VERSION ""

NS_ :

BS_:

BU_: Bosch_Radar2 Bosch_Radar1 RADAR_INPUT
VAL_TABLE_ ValueTable_Power_SNA 255 "SNA" ;
VAL_TABLE_ ValueTable_YAngle_SNA 65535 "SNA" ;
VAL_TABLE_ ValueTable_YSigmaAngle_SNA 1023 "SNA" ;
VAL_TABLE_ ValueTable_AngleType 1 "First 2 angles valid in C msg" 0 "First 4 angles valid in C msg" ;
VAL_TABLE_ RI_Veh_PRNDSTAT 0 "Park" 1 "Reverse" 2 "Neutral" 3 "Drive" ;

BO_ 1010 Location_Starter: 8 Bosch_Radar1
 SG_ Location_Veh_vEgo : 23|12@0+ (0.0625,-128) [-128|127.9375] "m/s" Vector__XXX
 SG_ Location_Veh_aEgo : 27|10@0+ (0.03125,-16) [-16|15.96875] "m/s²" Vector__XXX
 SG_ Location_Veh_slipAngle : 45|14@0+ (6.103515625E-005,-0.5) [-0.5|0.49993896484375] "Rad" Vector__XXX
 SG_ Location_Veh_psiDt : 7|16@0+ (6.103515625E-005,-2) [-2|1.99993896484375] "rad/s" Vector__XXX
 SG_ Location_MessStarterConsistBit : 56|1@0+ (1,0) [0|1] "" Vector__XXX

BO_ 1203 Location_Ender: 8 Bosch_Radar1
 SG_ Location_PacketChecksum : 63|8@0+ (1,0) [0|0] "" Vector__XXX
 SG_ Location_timestamp : 7|8@0+ (0.0009765625,0) [0|0.2490234375] "s" Vector__XXX
 SG_ Location_MessEnderConsistBit : 48|1@0+ (1,0) [0|1] "" Vector__XXX
 SG_ Location_TCCounter : 31|8@0+ (1,0) [0|0] "" Vector__XXX

BO_ 1958 Radar2_Diag_Response: 8 Bosch_Radar2
 SG_ R2_DiagResponse : 7|64@0+ (1,0) [0|0] "" Vector__XXX

BO_ 1957 Radar2_Diag_Request: 8 RADAR_INPUT
 SG_ R2_DiagRequest : 7|64@0+ (1,0) [0|0] ""  Bosch_Radar2

BO_ 1985 Radar1_Diag_Response: 8 Bosch_Radar1
 SG_ R1_DiagResponse : 7|64@0+ (1,0) [0|0] "" Vector__XXX

BO_ 1879 Radar1_Diag_Request: 8 RADAR_INPUT
 SG_ R1_DiagRequest : 7|64@0+ (1,0) [0|0] ""  Bosch_Radar1

BO_ 1011 location00_A: 8 Bosch_Radar1
 SG_ Loc00_Status : 62|1@0+ (1,0) [0|1] "" Vector__XXX
 SG_ Loc00_AngleType : 63|1@0+ (1,0) [0|1] "" Vector__XXX
 SG_ Loc00_YExistProb4 : 55|8@0+ (0.00390625,0) [0|1] "" Vector__XXX
 SG_ Loc00_YExistProb3 : 47|8@0+ (0.00390625,0) [0|1] "" Vector__XXX
 SG_ Loc00_YExistProb2 : 39|8@0+ (0.00390625,0) [0|1] "" Vector__XXX
 SG_ Loc00_YExistProb1 : 31|8@0+ (0.00390625,0) [0|1] "" Vector__XXX
 SG_ Loc00_YExistProb0 : 23|8@0+ (0.00390625,0) [0|1] "" Vector__XXX
 SG_ Loc00_RadialDist : 7|16@0+ (0.0039063,0) [0|255.9993705] "m" Vector__XXX

BO_ 1012 location00_B: 8 Bosch_Radar1
 SG_ Loc00_ZCorrelated : 53|10@0+ (0.00390625,-2) [-2|1.99609375] "rad" Vector__XXX
 SG_ Loc00_YSigmaAngle4 : 25|10@0+ (0.00012207,0) [0|0.12487761] "rad" Vector__XXX
 SG_ Loc00_YSigmaAngle3 : 47|10@0+ (0.00012207,0) [0|0.12487761] "rad" Vector__XXX
 SG_ Loc00_YSigmaAngle2 : 19|10@0+ (0.00012207,0) [0|0.12487761] "rad" Vector__XXX
 SG_ Loc00_YSigmaAngle1 : 13|10@0+ (0.00012207,0) [0|0.12487761] "rad" Vector__XXX
 SG_ Loc00_YSigmaAngle0 : 7|10@0+ (0.00012207,0) [0|0.12487761] "rad" Vector__XXX

BO_ 1013 location00_C: 8 Bosch_Radar1
 SG_ Loc00_YAngle3 : 55|16@0+ (6.103608E-005,-2) [-2|1.9999995028] "rad" Vector__XXX
 SG_ Loc00_YAngle2 : 39|16@0+ (6.103608E-005,-2) [-2|1.9999995028] "rad" Vector__XXX
 SG_ Loc00_YAngle1 : 23|16@0+ (6.103608E-005,-2) [-2|1.9999995028] "rad" Vector__XXX
 SG_ Loc00_YAngle0 : 7|16@0+ (6.103608E-005,-2) [-2|1.9999995028] "rad" Vector__XXX

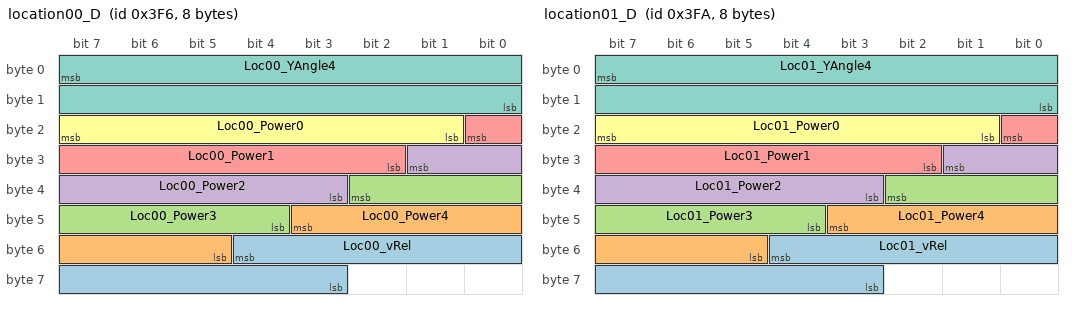
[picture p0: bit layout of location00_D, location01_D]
BO_ 1014 location00_D: 8 Bosch_Radar1
 SG_ Loc00_vRel : 52|10@0+ (0.125,-64) [-64|63.875] "m/s" Vector__XXX
 SG_ Loc00_Power4 : 43|7@0+ (1,-64) [-64|63] "dBm^2" Vector__XXX
 SG_ Loc00_Power3 : 34|7@0+ (1,-64) [-64|63] "dBm^2" Vector__XXX
 SG_ Loc00_Power2 : 25|7@0+ (1,-64) [-64|63] "dBm^2" Vector__XXX
 SG_ Loc00_Power1 : 16|7@0+ (1,-64) [-64|63] "dBm^2" Vector__XXX
 SG_ Loc00_Power0 : 23|7@0+ (1,-64) [-64|63] "dBm^2" Vector__XXX
 SG_ Loc00_YAngle4 : 7|16@0+ (6.103608E-005,-2) [-2|1.9999995028] "rad" Vector__XXX

BO_ 1015 location01_A: 8 Bosch_Radar1
 SG_ Loc01_Status : 62|1@0+ (1,0) [0|1] "" Vector__XXX
 SG_ Loc01_AngleType : 63|1@0+ (1,0) [0|1] "" Vector__XXX
 SG_ Loc01_YExistProb4 : 55|8@0+ (0.00390625,0) [0|1] "" Vector__XXX
 SG_ Loc01_YExistProb3 : 47|8@0+ (0.00390625,0) [0|1] "" Vector__XXX
 SG_ Loc01_YExistProb2 : 39|8@0+ (0.00390625,0) [0|1] "" Vector__XXX
 SG_ Loc01_YExistProb1 : 31|8@0+ (0.00390625,0) [0|1] "" Vector__XXX
 SG_ Loc01_YExistProb0 : 23|8@0+ (0.00390625,0) [0|1] "" Vector__XXX
 SG_ Loc01_RadialDist : 7|16@0+ (0.0039063,0) [0|255.9993705] "m" Vector__XXX

BO_ 1016 location01_B: 8 Bosch_Radar1
 SG_ Loc01_ZCorrelated : 53|10@0+ (0.00390625,-2) [-2|1.99609375] "rad" Vector__XXX
 SG_ Loc01_YSigmaAngle4 : 25|10@0+ (0.00012207,0) [0|0.12487761] "rad" Vector__XXX
 SG_ Loc01_YSigmaAngle3 : 47|10@0+ (0.00012207,0) [0|0.12487761] "rad" Vector__XXX
 SG_ Loc01_YSigmaAngle2 : 19|10@0+ (0.00012207,0) [0|0.12487761] "rad" Vector__XXX
 SG_ Loc01_YSigmaAngle1 : 13|10@0+ (0.00012207,0) [0|0.12487761] "rad" Vector__XXX
 SG_ Loc01_YSigmaAngle0 : 7|10@0+ (0.00012207,0) [0|0.12487761] "rad" Vector__XXX

BO_ 1017 location01_C: 8 Bosch_Radar1
 SG_ Loc01_YAngle3 : 55|16@0+ (6.103608E-005,-2) [-2|1.9999995028] "rad" Vector__XXX
 SG_ Loc01_YAngle2 : 39|16@0+ (6.103608E-005,-2) [-2|1.9999995028] "rad" Vector__XXX
 SG_ Loc01_YAngle1 : 23|16@0+ (6.103608E-005,-2) [-2|1.9999995028] "rad" Vector__XXX
 SG_ Loc01_YAngle0 : 7|16@0+ (6.103608E-005,-2) [-2|1.9999995028] "rad" Vector__XXX

BO_ 1018 location01_D: 8 Bosch_Radar1
 SG_ Loc01_vRel : 52|10@0+ (0.125,-64) [-64|63.875] "m/s" Vector__XXX
 SG_ Loc01_Power4 : 43|7@0+ (1,-64) [-64|63] "dBm^2" Vector__XXX
 SG_ Loc01_Power3 : 34|7@0+ (1,-64) [-64|63] "dBm^2" Vector__XXX
 SG_ Loc01_Power2 : 25|7@0+ (1,-64) [-64|63] "dBm^2" Vector__XXX
 SG_ Loc01_Power1 : 16|7@0+ (1,-64) [-64|63] "dBm^2" Vector__XXX
 SG_ Loc01_Power0 : 23|7@0+ (1,-64) [-64|63] "dBm^2" Vector__XXX
 SG_ Loc01_YAngle4 : 7|16@0+ (6.103608E-005,-2) [-2|1.9999995028] "rad" Vector__XXX

BO_ 1019 location02_A: 8 Bosch_Radar1
 SG_ Loc02_Status : 62|1@0+ (1,0) [0|1] "" Vector__XXX
 SG_ Loc02_AngleType : 63|1@0+ (1,0) [0|1] "" Vector__XXX
 SG_ Loc02_YExistProb4 : 55|8@0+ (0.00390625,0) [0|1] "" Vector__XXX
 SG_ Loc02_YExistProb3 : 47|8@0+ (0.00390625,0) [0|1] "" Vector__XXX
 SG_ Loc02_YExistProb2 : 39|8@0+ (0.00390625,0) [0|1] "" Vector__XXX
 SG_ Loc02_YExistProb1 : 31|8@0+ (0.00390625,0) [0|1] "" Vector__XXX
 SG_ Loc02_YExistProb0 : 23|8@0+ (0.00390625,0) [0|1] "" Vector__XXX
 SG_ Loc02_RadialDist : 7|16@0+ (0.0039063,0) [0|255.9993705] "m" Vector__XXX

BO_ 1020 location02_B: 8 Bosch_Radar1
 SG_ Loc02_ZCorrelated : 53|10@0+ (0.00390625,-2) [-2|1.99609375] "rad" Vector__XXX
 SG_ Loc02_YSigmaAngle4 : 25|10@0+ (0.00012207,0) [0|0.12487761] "rad" Vector__XXX
 SG_ Loc02_YSigmaAngle3 : 47|10@0+ (0.00012207,0) [0|0.12487761] "rad" Vector__XXX
 SG_ Loc02_YSigmaAngle2 : 19|10@0+ (0.00012207,0) [0|0.12487761] "rad" Vector__XXX
 SG_ Loc02_YSigmaAngle1 : 13|10@0+ (0.00012207,0) [0|0.12487761] "rad" Vector__XXX
 SG_ Loc02_YSigmaAngle0 : 7|10@0+ (0.00012207,0) [0|0.12487761] "rad" Vector__XXX

BO_ 1021 location02_C: 8 Bosch_Radar1
 SG_ Loc02_YAngle3 : 55|16@0+ (6.103608E-005,-2) [-2|1.9999995028] "rad" Vector__XXX
 SG_ Loc02_YAngle2 : 39|16@0+ (6.103608E-005,-2) [-2|1.9999995028] "rad" Vector__XXX
 SG_ Loc02_YAngle1 : 23|16@0+ (6.103608E-005,-2) [-2|1.9999995028] "rad" Vector__XXX
 SG_ Loc02_YAngle0 : 7|16@0+ (6.103608E-005,-2) [-2|1.9999995028] "rad" Vector__XXX

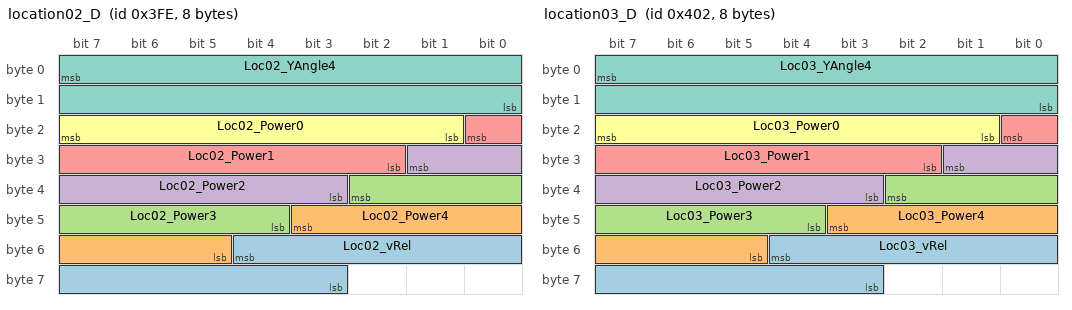
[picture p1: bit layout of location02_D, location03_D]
BO_ 1022 location02_D: 8 Bosch_Radar1
 SG_ Loc02_vRel : 52|10@0+ (0.125,-64) [-64|63.875] "m/s" Vector__XXX
 SG_ Loc02_Power4 : 43|7@0+ (1,-64) [-64|63] "dBm^2" Vector__XXX
 SG_ Loc02_Power3 : 34|7@0+ (1,-64) [-64|63] "dBm^2" Vector__XXX
 SG_ Loc02_Power2 : 25|7@0+ (1,-64) [-64|63] "dBm^2" Vector__XXX
 SG_ Loc02_Power1 : 16|7@0+ (1,-64) [-64|63] "dBm^2" Vector__XXX
 SG_ Loc02_Power0 : 23|7@0+ (1,-64) [-64|63] "dBm^2" Vector__XXX
 SG_ Loc02_YAngle4 : 7|16@0+ (6.103608E-005,-2) [-2|1.9999995028] "rad" Vector__XXX

BO_ 1023 location03_A: 8 Bosch_Radar1
 SG_ Loc03_Status : 62|1@0+ (1,0) [0|1] "" Vector__XXX
 SG_ Loc03_AngleType : 63|1@0+ (1,0) [0|1] "" Vector__XXX
 SG_ Loc03_YExistProb4 : 55|8@0+ (0.00390625,0) [0|1] "" Vector__XXX
 SG_ Loc03_YExistProb3 : 47|8@0+ (0.00390625,0) [0|1] "" Vector__XXX
 SG_ Loc03_YExistProb2 : 39|8@0+ (0.00390625,0) [0|1] "" Vector__XXX
 SG_ Loc03_YExistProb1 : 31|8@0+ (0.00390625,0) [0|1] "" Vector__XXX
 SG_ Loc03_YExistProb0 : 23|8@0+ (0.00390625,0) [0|1] "" Vector__XXX
 SG_ Loc03_RadialDist : 7|16@0+ (0.0039063,0) [0|255.9993705] "m" Vector__XXX

BO_ 1024 location03_B: 8 Bosch_Radar1
 SG_ Loc03_ZCorrelated : 53|10@0+ (0.00390625,-2) [-2|1.99609375] "rad" Vector__XXX
 SG_ Loc03_YSigmaAngle4 : 25|10@0+ (0.00012207,0) [0|0.12487761] "rad" Vector__XXX
 SG_ Loc03_YSigmaAngle3 : 47|10@0+ (0.00012207,0) [0|0.12487761] "rad" Vector__XXX
 SG_ Loc03_YSigmaAngle2 : 19|10@0+ (0.00012207,0) [0|0.12487761] "rad" Vector__XXX
 SG_ Loc03_YSigmaAngle1 : 13|10@0+ (0.00012207,0) [0|0.12487761] "rad" Vector__XXX
 SG_ Loc03_YSigmaAngle0 : 7|10@0+ (0.00012207,0) [0|0.12487761] "rad" Vector__XXX

BO_ 1025 location03_C: 8 Bosch_Radar1
 SG_ Loc03_YAngle3 : 55|16@0+ (6.103608E-005,-2) [-2|1.9999995028] "rad" Vector__XXX
 SG_ Loc03_YAngle2 : 39|16@0+ (6.103608E-005,-2) [-2|1.9999995028] "rad" Vector__XXX
 SG_ Loc03_YAngle1 : 23|16@0+ (6.103608E-005,-2) [-2|1.9999995028] "rad" Vector__XXX
 SG_ Loc03_YAngle0 : 7|16@0+ (6.103608E-005,-2) [-2|1.9999995028] "rad" Vector__XXX

BO_ 1026 location03_D: 8 Bosch_Radar1
 SG_ Loc03_vRel : 52|10@0+ (0.125,-64) [-64|63.875] "m/s" Vector__XXX
 SG_ Loc03_Power4 : 43|7@0+ (1,-64) [-64|63] "dBm^2" Vector__XXX
 SG_ Loc03_Power3 : 34|7@0+ (1,-64) [-64|63] "dBm^2" Vector__XXX
 SG_ Loc03_Power2 : 25|7@0+ (1,-64) [-64|63] "dBm^2" Vector__XXX
 SG_ Loc03_Power1 : 16|7@0+ (1,-64) [-64|63] "dBm^2" Vector__XXX
 SG_ Loc03_Power0 : 23|7@0+ (1,-64) [-64|63] "dBm^2" Vector__XXX
 SG_ Loc03_YAngle4 : 7|16@0+ (6.103608E-005,-2) [-2|1.9999995028] "rad" Vector__XXX

BO_ 1027 location04_A: 8 Bosch_Radar1
 SG_ Loc04_Status : 62|1@0+ (1,0) [0|1] "" Vector__XXX
 SG_ Loc04_AngleType : 63|1@0+ (1,0) [0|1] "" Vector__XXX
 SG_ Loc04_YExistProb4 : 55|8@0+ (0.00390625,0) [0|1] "" Vector__XXX
 SG_ Loc04_YExistProb3 : 47|8@0+ (0.00390625,0) [0|1] "" Vector__XXX
 SG_ Loc04_YExistProb2 : 39|8@0+ (0.00390625,0) [0|1] "" Vector__XXX
 SG_ Loc04_YExistProb1 : 31|8@0+ (0.00390625,0) [0|1] "" Vector__XXX
 SG_ Loc04_YExistProb0 : 23|8@0+ (0.00390625,0) [0|1] "" Vector__XXX
 SG_ Loc04_RadialDist : 7|16@0+ (0.0039063,0) [0|255.9993705] "m" Vector__XXX

BO_ 1028 location04_B: 8 Bosch_Radar1
 SG_ Loc04_ZCorrelated : 53|10@0+ (0.00390625,-2) [-2|1.99609375] "rad" Vector__XXX
 SG_ Loc04_YSigmaAngle4 : 25|10@0+ (0.00012207,0) [0|0.12487761] "rad" Vector__XXX
 SG_ Loc04_YSigmaAngle3 : 47|10@0+ (0.00012207,0) [0|0.12487761] "rad" Vector__XXX
 SG_ Loc04_YSigmaAngle2 : 19|10@0+ (0.00012207,0) [0|0.12487761] "rad" Vector__XXX
 SG_ Loc04_YSigmaAngle1 : 13|10@0+ (0.00012207,0) [0|0.12487761] "rad" Vector__XXX
 SG_ Loc04_YSigmaAngle0 : 7|10@0+ (0.00012207,0) [0|0.12487761] "rad" Vector__XXX

BO_ 1029 location04_C: 8 Bosch_Radar1
 SG_ Loc04_YAngle3 : 55|16@0+ (6.103608E-005,-2) [-2|1.9999995028] "rad" Vector__XXX
 SG_ Loc04_YAngle2 : 39|16@0+ (6.103608E-005,-2) [-2|1.9999995028] "rad" Vector__XXX
 SG_ Loc04_YAngle1 : 23|16@0+ (6.103608E-005,-2) [-2|1.9999995028] "rad" Vector__XXX
 SG_ Loc04_YAngle0 : 7|16@0+ (6.103608E-005,-2) [-2|1.9999995028] "rad" Vector__XXX

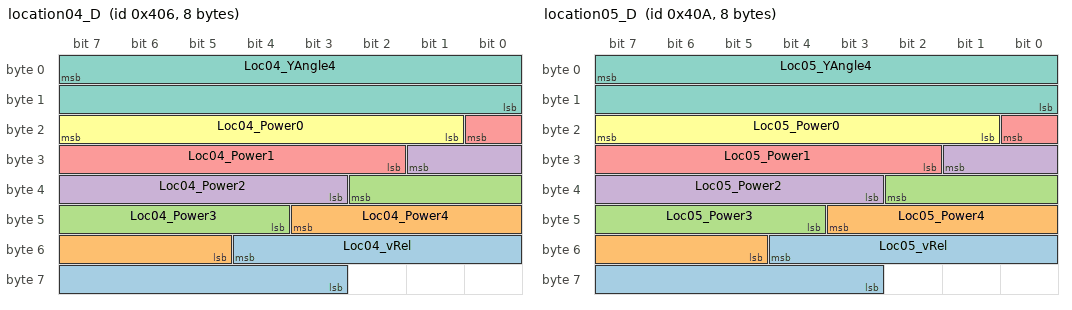
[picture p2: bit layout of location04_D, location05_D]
BO_ 1030 location04_D: 8 Bosch_Radar1
 SG_ Loc04_vRel : 52|10@0+ (0.125,-64) [-64|63.875] "m/s" Vector__XXX
 SG_ Loc04_Power4 : 43|7@0+ (1,-64) [-64|63] "dBm^2" Vector__XXX
 SG_ Loc04_Power3 : 34|7@0+ (1,-64) [-64|63] "dBm^2" Vector__XXX
 SG_ Loc04_Power2 : 25|7@0+ (1,-64) [-64|63] "dBm^2" Vector__XXX
 SG_ Loc04_Power1 : 16|7@0+ (1,-64) [-64|63] "dBm^2" Vector__XXX
 SG_ Loc04_Power0 : 23|7@0+ (1,-64) [-64|63] "dBm^2" Vector__XXX
 SG_ Loc04_YAngle4 : 7|16@0+ (6.103608E-005,-2) [-2|1.9999995028] "rad" Vector__XXX

BO_ 1031 location05_A: 8 Bosch_Radar1
 SG_ Loc05_Status : 62|1@0+ (1,0) [0|1] "" Vector__XXX
 SG_ Loc05_AngleType : 63|1@0+ (1,0) [0|1] "" Vector__XXX
 SG_ Loc05_YExistProb4 : 55|8@0+ (0.00390625,0) [0|1] "" Vector__XXX
 SG_ Loc05_YExistProb3 : 47|8@0+ (0.00390625,0) [0|1] "" Vector__XXX
 SG_ Loc05_YExistProb2 : 39|8@0+ (0.00390625,0) [0|1] "" Vector__XXX
 SG_ Loc05_YExistProb1 : 31|8@0+ (0.00390625,0) [0|1] "" Vector__XXX
 SG_ Loc05_YExistProb0 : 23|8@0+ (0.00390625,0) [0|1] "" Vector__XXX
 SG_ Loc05_RadialDist : 7|16@0+ (0.0039063,0) [0|255.9993705] "m" Vector__XXX

BO_ 1032 location05_B: 8 Bosch_Radar1
 SG_ Loc05_ZCorrelated : 53|10@0+ (0.00390625,-2) [-2|1.99609375] "rad" Vector__XXX
 SG_ Loc05_YSigmaAngle4 : 25|10@0+ (0.00012207,0) [0|0.12487761] "rad" Vector__XXX
 SG_ Loc05_YSigmaAngle3 : 47|10@0+ (0.00012207,0) [0|0.12487761] "rad" Vector__XXX
 SG_ Loc05_YSigmaAngle2 : 19|10@0+ (0.00012207,0) [0|0.12487761] "rad" Vector__XXX
 SG_ Loc05_YSigmaAngle1 : 13|10@0+ (0.00012207,0) [0|0.12487761] "rad" Vector__XXX
 SG_ Loc05_YSigmaAngle0 : 7|10@0+ (0.00012207,0) [0|0.12487761] "rad" Vector__XXX

BO_ 1033 location05_C: 8 Bosch_Radar1
 SG_ Loc05_YAngle3 : 55|16@0+ (6.103608E-005,-2) [-2|1.9999995028] "rad" Vector__XXX
 SG_ Loc05_YAngle2 : 39|16@0+ (6.103608E-005,-2) [-2|1.9999995028] "rad" Vector__XXX
 SG_ Loc05_YAngle1 : 23|16@0+ (6.103608E-005,-2) [-2|1.9999995028] "rad" Vector__XXX
 SG_ Loc05_YAngle0 : 7|16@0+ (6.103608E-005,-2) [-2|1.9999995028] "rad" Vector__XXX

BO_ 1034 location05_D: 8 Bosch_Radar1
 SG_ Loc05_vRel : 52|10@0+ (0.125,-64) [-64|63.875] "m/s" Vector__XXX
 SG_ Loc05_Power4 : 43|7@0+ (1,-64) [-64|63] "dBm^2" Vector__XXX
 SG_ Loc05_Power3 : 34|7@0+ (1,-64) [-64|63] "dBm^2" Vector__XXX
 SG_ Loc05_Power2 : 25|7@0+ (1,-64) [-64|63] "dBm^2" Vector__XXX
 SG_ Loc05_Power1 : 16|7@0+ (1,-64) [-64|63] "dBm^2" Vector__XXX
 SG_ Loc05_Power0 : 23|7@0+ (1,-64) [-64|63] "dBm^2" Vector__XXX
 SG_ Loc05_YAngle4 : 7|16@0+ (6.103608E-005,-2) [-2|1.9999995028] "rad" Vector__XXX

BO_ 1035 location06_A: 8 Bosch_Radar1
 SG_ Loc06_Status : 62|1@0+ (1,0) [0|1] "" Vector__XXX
 SG_ Loc06_AngleType : 63|1@0+ (1,0) [0|1] "" Vector__XXX
 SG_ Loc06_YExistProb4 : 55|8@0+ (0.00390625,0) [0|1] "" Vector__XXX
 SG_ Loc06_YExistProb3 : 47|8@0+ (0.00390625,0) [0|1] "" Vector__XXX
 SG_ Loc06_YExistProb2 : 39|8@0+ (0.00390625,0) [0|1] "" Vector__XXX
 SG_ Loc06_YExistProb1 : 31|8@0+ (0.00390625,0) [0|1] "" Vector__XXX
 SG_ Loc06_YExistProb0 : 23|8@0+ (0.00390625,0) [0|1] "" Vector__XXX
 SG_ Loc06_RadialDist : 7|16@0+ (0.0039063,0) [0|255.9993705] "m" Vector__XXX

BO_ 1036 location06_B: 8 Bosch_Radar1
 SG_ Loc06_ZCorrelated : 53|10@0+ (0.00390625,-2) [-2|1.99609375] "rad" Vector__XXX
 SG_ Loc06_YSigmaAngle4 : 25|10@0+ (0.00012207,0) [0|0.12487761] "rad" Vector__XXX
 SG_ Loc06_YSigmaAngle3 : 47|10@0+ (0.00012207,0) [0|0.12487761] "rad" Vector__XXX
 SG_ Loc06_YSigmaAngle2 : 19|10@0+ (0.00012207,0) [0|0.12487761] "rad" Vector__XXX
 SG_ Loc06_YSigmaAngle1 : 13|10@0+ (0.00012207,0) [0|0.12487761] "rad" Vector__XXX
 SG_ Loc06_YSigmaAngle0 : 7|10@0+ (0.00012207,0) [0|0.12487761] "rad" Vector__XXX

BO_ 1037 location06_C: 8 Bosch_Radar1
 SG_ Loc06_YAngle3 : 55|16@0+ (6.103608E-005,-2) [-2|1.9999995028] "rad" Vector__XXX
 SG_ Loc06_YAngle2 : 39|16@0+ (6.103608E-005,-2) [-2|1.9999995028] "rad" Vector__XXX
 SG_ Loc06_YAngle1 : 23|16@0+ (6.103608E-005,-2) [-2|1.9999995028] "rad" Vector__XXX
 SG_ Loc06_YAngle0 : 7|16@0+ (6.103608E-005,-2) [-2|1.9999995028] "rad" Vector__XXX

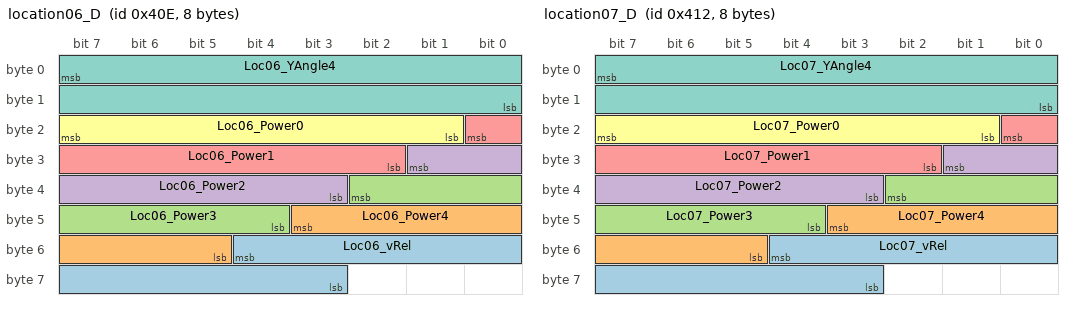
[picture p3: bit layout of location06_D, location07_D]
BO_ 1038 location06_D: 8 Bosch_Radar1
 SG_ Loc06_vRel : 52|10@0+ (0.125,-64) [-64|63.875] "m/s" Vector__XXX
 SG_ Loc06_Power4 : 43|7@0+ (1,-64) [-64|63] "dBm^2" Vector__XXX
 SG_ Loc06_Power3 : 34|7@0+ (1,-64) [-64|63] "dBm^2" Vector__XXX
 SG_ Loc06_Power2 : 25|7@0+ (1,-64) [-64|63] "dBm^2" Vector__XXX
 SG_ Loc06_Power1 : 16|7@0+ (1,-64) [-64|63] "dBm^2" Vector__XXX
 SG_ Loc06_Power0 : 23|7@0+ (1,-64) [-64|63] "dBm^2" Vector__XXX
 SG_ Loc06_YAngle4 : 7|16@0+ (6.103608E-005,-2) [-2|1.9999995028] "rad" Vector__XXX

BO_ 1039 location07_A: 8 Bosch_Radar1
 SG_ Loc07_Status : 62|1@0+ (1,0) [0|1] "" Vector__XXX
 SG_ Loc07_AngleType : 63|1@0+ (1,0) [0|1] "" Vector__XXX
 SG_ Loc07_YExistProb4 : 55|8@0+ (0.00390625,0) [0|1] "" Vector__XXX
 SG_ Loc07_YExistProb3 : 47|8@0+ (0.00390625,0) [0|1] "" Vector__XXX
 SG_ Loc07_YExistProb2 : 39|8@0+ (0.00390625,0) [0|1] "" Vector__XXX
 SG_ Loc07_YExistProb1 : 31|8@0+ (0.00390625,0) [0|1] "" Vector__XXX
 SG_ Loc07_YExistProb0 : 23|8@0+ (0.00390625,0) [0|1] "" Vector__XXX
 SG_ Loc07_RadialDist : 7|16@0+ (0.0039063,0) [0|255.9993705] "m" Vector__XXX

BO_ 1040 location07_B: 8 Bosch_Radar1
 SG_ Loc07_ZCorrelated : 53|10@0+ (0.00390625,-2) [-2|1.99609375] "rad" Vector__XXX
 SG_ Loc07_YSigmaAngle4 : 25|10@0+ (0.00012207,0) [0|0.12487761] "rad" Vector__XXX
 SG_ Loc07_YSigmaAngle3 : 47|10@0+ (0.00012207,0) [0|0.12487761] "rad" Vector__XXX
 SG_ Loc07_YSigmaAngle2 : 19|10@0+ (0.00012207,0) [0|0.12487761] "rad" Vector__XXX
 SG_ Loc07_YSigmaAngle1 : 13|10@0+ (0.00012207,0) [0|0.12487761] "rad" Vector__XXX
 SG_ Loc07_YSigmaAngle0 : 7|10@0+ (0.00012207,0) [0|0.12487761] "rad" Vector__XXX

BO_ 1041 location07_C: 8 Bosch_Radar1
 SG_ Loc07_YAngle3 : 55|16@0+ (6.103608E-005,-2) [-2|1.9999995028] "rad" Vector__XXX
 SG_ Loc07_YAngle2 : 39|16@0+ (6.103608E-005,-2) [-2|1.9999995028] "rad" Vector__XXX
 SG_ Loc07_YAngle1 : 23|16@0+ (6.103608E-005,-2) [-2|1.9999995028] "rad" Vector__XXX
 SG_ Loc07_YAngle0 : 7|16@0+ (6.103608E-005,-2) [-2|1.9999995028] "rad" Vector__XXX

BO_ 1042 location07_D: 8 Bosch_Radar1
 SG_ Loc07_vRel : 52|10@0+ (0.125,-64) [-64|63.875] "m/s" Vector__XXX
 SG_ Loc07_Power4 : 43|7@0+ (1,-64) [-64|63] "dBm^2" Vector__XXX
 SG_ Loc07_Power3 : 34|7@0+ (1,-64) [-64|63] "dBm^2" Vector__XXX
 SG_ Loc07_Power2 : 25|7@0+ (1,-64) [-64|63] "dBm^2" Vector__XXX
 SG_ Loc07_Power1 : 16|7@0+ (1,-64) [-64|63] "dBm^2" Vector__XXX
 SG_ Loc07_Power0 : 23|7@0+ (1,-64) [-64|63] "dBm^2" Vector__XXX
 SG_ Loc07_YAngle4 : 7|16@0+ (6.103608E-005,-2) [-2|1.9999995028] "rad" Vector__XXX

BO_ 1043 location08_A: 8 Bosch_Radar1
 SG_ Loc08_Status : 62|1@0+ (1,0) [0|1] "" Vector__XXX
 SG_ Loc08_AngleType : 63|1@0+ (1,0) [0|1] "" Vector__XXX
 SG_ Loc08_YExistProb4 : 55|8@0+ (0.00390625,0) [0|1] "" Vector__XXX
 SG_ Loc08_YExistProb3 : 47|8@0+ (0.00390625,0) [0|1] "" Vector__XXX
 SG_ Loc08_YExistProb2 : 39|8@0+ (0.00390625,0) [0|1] "" Vector__XXX
 SG_ Loc08_YExistProb1 : 31|8@0+ (0.00390625,0) [0|1] "" Vector__XXX
 SG_ Loc08_YExistProb0 : 23|8@0+ (0.00390625,0) [0|1] "" Vector__XXX
 SG_ Loc08_RadialDist : 7|16@0+ (0.0039063,0) [0|255.9993705] "m" Vector__XXX

BO_ 1044 location08_B: 8 Bosch_Radar1
 SG_ Loc08_ZCorrelated : 53|10@0+ (0.00390625,-2) [-2|1.99609375] "rad" Vector__XXX
 SG_ Loc08_YSigmaAngle4 : 25|10@0+ (0.00012207,0) [0|0.12487761] "rad" Vector__XXX
 SG_ Loc08_YSigmaAngle3 : 47|10@0+ (0.00012207,0) [0|0.12487761] "rad" Vector__XXX
 SG_ Loc08_YSigmaAngle2 : 19|10@0+ (0.00012207,0) [0|0.12487761] "rad" Vector__XXX
 SG_ Loc08_YSigmaAngle1 : 13|10@0+ (0.00012207,0) [0|0.12487761] "rad" Vector__XXX
 SG_ Loc08_YSigmaAngle0 : 7|10@0+ (0.00012207,0) [0|0.12487761] "rad" Vector__XXX

BO_ 1045 location08_C: 8 Bosch_Radar1
 SG_ Loc08_YAngle3 : 55|16@0+ (6.103608E-005,-2) [-2|1.9999995028] "rad" Vector__XXX
 SG_ Loc08_YAngle2 : 39|16@0+ (6.103608E-005,-2) [-2|1.9999995028] "rad" Vector__XXX
 SG_ Loc08_YAngle1 : 23|16@0+ (6.103608E-005,-2) [-2|1.9999995028] "rad" Vector__XXX
 SG_ Loc08_YAngle0 : 7|16@0+ (6.103608E-005,-2) [-2|1.9999995028] "rad" Vector__XXX

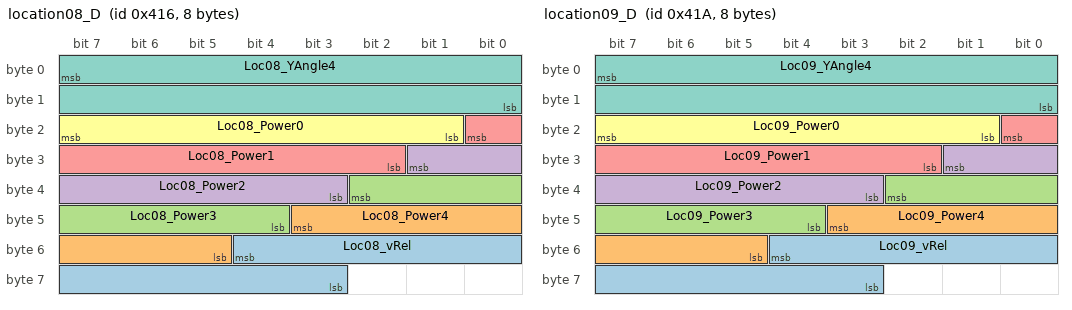
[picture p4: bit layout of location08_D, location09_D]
BO_ 1046 location08_D: 8 Bosch_Radar1
 SG_ Loc08_vRel : 52|10@0+ (0.125,-64) [-64|63.875] "m/s" Vector__XXX
 SG_ Loc08_Power4 : 43|7@0+ (1,-64) [-64|63] "dBm^2" Vector__XXX
 SG_ Loc08_Power3 : 34|7@0+ (1,-64) [-64|63] "dBm^2" Vector__XXX
 SG_ Loc08_Power2 : 25|7@0+ (1,-64) [-64|63] "dBm^2" Vector__XXX
 SG_ Loc08_Power1 : 16|7@0+ (1,-64) [-64|63] "dBm^2" Vector__XXX
 SG_ Loc08_Power0 : 23|7@0+ (1,-64) [-64|63] "dBm^2" Vector__XXX
 SG_ Loc08_YAngle4 : 7|16@0+ (6.103608E-005,-2) [-2|1.9999995028] "rad" Vector__XXX

BO_ 1047 location09_A: 8 Bosch_Radar1
 SG_ Loc09_Status : 62|1@0+ (1,0) [0|1] "" Vector__XXX
 SG_ Loc09_AngleType : 63|1@0+ (1,0) [0|1] "" Vector__XXX
 SG_ Loc09_YExistProb4 : 55|8@0+ (0.00390625,0) [0|1] "" Vector__XXX
 SG_ Loc09_YExistProb3 : 47|8@0+ (0.00390625,0) [0|1] "" Vector__XXX
 SG_ Loc09_YExistProb2 : 39|8@0+ (0.00390625,0) [0|1] "" Vector__XXX
 SG_ Loc09_YExistProb1 : 31|8@0+ (0.00390625,0) [0|1] "" Vector__XXX
 SG_ Loc09_YExistProb0 : 23|8@0+ (0.00390625,0) [0|1] "" Vector__XXX
 SG_ Loc09_RadialDist : 7|16@0+ (0.0039063,0) [0|255.9993705] "m" Vector__XXX

BO_ 1048 location09_B: 8 Bosch_Radar1
 SG_ Loc09_ZCorrelated : 53|10@0+ (0.00390625,-2) [-2|1.99609375] "rad" Vector__XXX
 SG_ Loc09_YSigmaAngle4 : 25|10@0+ (0.00012207,0) [0|0.12487761] "rad" Vector__XXX
 SG_ Loc09_YSigmaAngle3 : 47|10@0+ (0.00012207,0) [0|0.12487761] "rad" Vector__XXX
 SG_ Loc09_YSigmaAngle2 : 19|10@0+ (0.00012207,0) [0|0.12487761] "rad" Vector__XXX
 SG_ Loc09_YSigmaAngle1 : 13|10@0+ (0.00012207,0) [0|0.12487761] "rad" Vector__XXX
 SG_ Loc09_YSigmaAngle0 : 7|10@0+ (0.00012207,0) [0|0.12487761] "rad" Vector__XXX

BO_ 1049 location09_C: 8 Bosch_Radar1
 SG_ Loc09_YAngle3 : 55|16@0+ (6.103608E-005,-2) [-2|1.9999995028] "rad" Vector__XXX
 SG_ Loc09_YAngle2 : 39|16@0+ (6.103608E-005,-2) [-2|1.9999995028] "rad" Vector__XXX
 SG_ Loc09_YAngle1 : 23|16@0+ (6.103608E-005,-2) [-2|1.9999995028] "rad" Vector__XXX
 SG_ Loc09_YAngle0 : 7|16@0+ (6.103608E-005,-2) [-2|1.9999995028] "rad" Vector__XXX

BO_ 1050 location09_D: 8 Bosch_Radar1
 SG_ Loc09_vRel : 52|10@0+ (0.125,-64) [-64|63.875] "m/s" Vector__XXX
 SG_ Loc09_Power4 : 43|7@0+ (1,-64) [-64|63] "dBm^2" Vector__XXX
 SG_ Loc09_Power3 : 34|7@0+ (1,-64) [-64|63] "dBm^2" Vector__XXX
 SG_ Loc09_Power2 : 25|7@0+ (1,-64) [-64|63] "dBm^2" Vector__XXX
 SG_ Loc09_Power1 : 16|7@0+ (1,-64) [-64|63] "dBm^2" Vector__XXX
 SG_ Loc09_Power0 : 23|7@0+ (1,-64) [-64|63] "dBm^2" Vector__XXX
 SG_ Loc09_YAngle4 : 7|16@0+ (6.103608E-005,-2) [-2|1.9999995028] "rad" Vector__XXX

BO_ 1051 location10_A: 8 Bosch_Radar1
 SG_ Loc10_Status : 62|1@0+ (1,0) [0|1] "" Vector__XXX
 SG_ Loc10_AngleType : 63|1@0+ (1,0) [0|1] "" Vector__XXX
 SG_ Loc10_YExistProb4 : 55|8@0+ (0.00390625,0) [0|1] "" Vector__XXX
 SG_ Loc10_YExistProb3 : 47|8@0+ (0.00390625,0) [0|1] "" Vector__XXX
 SG_ Loc10_YExistProb2 : 39|8@0+ (0.00390625,0) [0|1] "" Vector__XXX
 SG_ Loc10_YExistProb1 : 31|8@0+ (0.00390625,0) [0|1] "" Vector__XXX
 SG_ Loc10_YExistProb0 : 23|8@0+ (0.00390625,0) [0|1] "" Vector__XXX
 SG_ Loc10_RadialDist : 7|16@0+ (0.0039063,0) [0|255.9993705] "m" Vector__XXX

BO_ 1052 location10_B: 8 Bosch_Radar1
 SG_ Loc10_ZCorrelated : 53|10@0+ (0.00390625,-2) [-2|1.99609375] "rad" Vector__XXX
 SG_ Loc10_YSigmaAngle4 : 25|10@0+ (0.00012207,0) [0|0.12487761] "rad" Vector__XXX
 SG_ Loc10_YSigmaAngle3 : 47|10@0+ (0.00012207,0) [0|0.12487761] "rad" Vector__XXX
 SG_ Loc10_YSigmaAngle2 : 19|10@0+ (0.00012207,0) [0|0.12487761] "rad" Vector__XXX
 SG_ Loc10_YSigmaAngle1 : 13|10@0+ (0.00012207,0) [0|0.12487761] "rad" Vector__XXX
 SG_ Loc10_YSigmaAngle0 : 7|10@0+ (0.00012207,0) [0|0.12487761] "rad" Vector__XXX

BO_ 1053 location10_C: 8 Bosch_Radar1
 SG_ Loc10_YAngle3 : 55|16@0+ (6.103608E-005,-2) [-2|1.9999995028] "rad" Vector__XXX
 SG_ Loc10_YAngle2 : 39|16@0+ (6.103608E-005,-2) [-2|1.9999995028] "rad" Vector__XXX
 SG_ Loc10_YAngle1 : 23|16@0+ (6.103608E-005,-2) [-2|1.9999995028] "rad" Vector__XXX
 SG_ Loc10_YAngle0 : 7|16@0+ (6.103608E-005,-2) [-2|1.9999995028] "rad" Vector__XXX

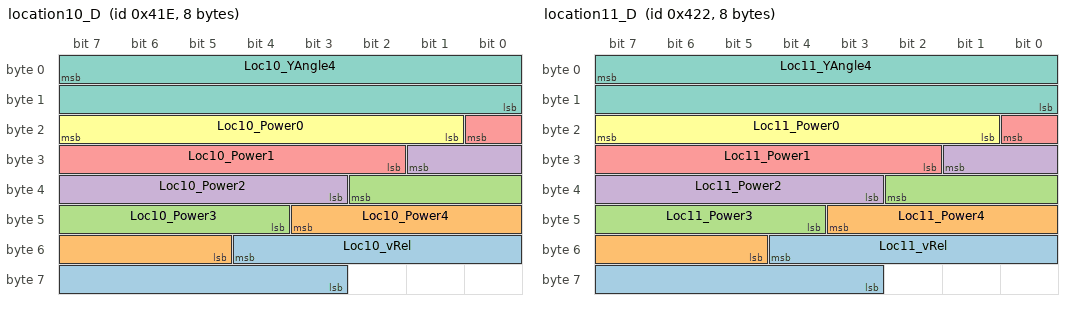
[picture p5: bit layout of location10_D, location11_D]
BO_ 1054 location10_D: 8 Bosch_Radar1
 SG_ Loc10_vRel : 52|10@0+ (0.125,-64) [-64|63.875] "m/s" Vector__XXX
 SG_ Loc10_Power4 : 43|7@0+ (1,-64) [-64|63] "dBm^2" Vector__XXX
 SG_ Loc10_Power3 : 34|7@0+ (1,-64) [-64|63] "dBm^2" Vector__XXX
 SG_ Loc10_Power2 : 25|7@0+ (1,-64) [-64|63] "dBm^2" Vector__XXX
 SG_ Loc10_Power1 : 16|7@0+ (1,-64) [-64|63] "dBm^2" Vector__XXX
 SG_ Loc10_Power0 : 23|7@0+ (1,-64) [-64|63] "dBm^2" Vector__XXX
 SG_ Loc10_YAngle4 : 7|16@0+ (6.103608E-005,-2) [-2|1.9999995028] "rad" Vector__XXX

BO_ 1055 location11_A: 8 Bosch_Radar1
 SG_ Loc11_Status : 62|1@0+ (1,0) [0|1] "" Vector__XXX
 SG_ Loc11_AngleType : 63|1@0+ (1,0) [0|1] "" Vector__XXX
 SG_ Loc11_YExistProb4 : 55|8@0+ (0.00390625,0) [0|1] "" Vector__XXX
 SG_ Loc11_YExistProb3 : 47|8@0+ (0.00390625,0) [0|1] "" Vector__XXX
 SG_ Loc11_YExistProb2 : 39|8@0+ (0.00390625,0) [0|1] "" Vector__XXX
 SG_ Loc11_YExistProb1 : 31|8@0+ (0.00390625,0) [0|1] "" Vector__XXX
 SG_ Loc11_YExistProb0 : 23|8@0+ (0.00390625,0) [0|1] "" Vector__XXX
 SG_ Loc11_RadialDist : 7|16@0+ (0.0039063,0) [0|255.9993705] "m" Vector__XXX

BO_ 1056 location11_B: 8 Bosch_Radar1
 SG_ Loc11_ZCorrelated : 53|10@0+ (0.00390625,-2) [-2|1.99609375] "rad" Vector__XXX
 SG_ Loc11_YSigmaAngle4 : 25|10@0+ (0.00012207,0) [0|0.12487761] "rad" Vector__XXX
 SG_ Loc11_YSigmaAngle3 : 47|10@0+ (0.00012207,0) [0|0.12487761] "rad" Vector__XXX
 SG_ Loc11_YSigmaAngle2 : 19|10@0+ (0.00012207,0) [0|0.12487761] "rad" Vector__XXX
 SG_ Loc11_YSigmaAngle1 : 13|10@0+ (0.00012207,0) [0|0.12487761] "rad" Vector__XXX
 SG_ Loc11_YSigmaAngle0 : 7|10@0+ (0.00012207,0) [0|0.12487761] "rad" Vector__XXX

BO_ 1057 location11_C: 8 Bosch_Radar1
 SG_ Loc11_YAngle3 : 55|16@0+ (6.103608E-005,-2) [-2|1.9999995028] "rad" Vector__XXX
 SG_ Loc11_YAngle2 : 39|16@0+ (6.103608E-005,-2) [-2|1.9999995028] "rad" Vector__XXX
 SG_ Loc11_YAngle1 : 23|16@0+ (6.103608E-005,-2) [-2|1.9999995028] "rad" Vector__XXX
 SG_ Loc11_YAngle0 : 7|16@0+ (6.103608E-005,-2) [-2|1.9999995028] "rad" Vector__XXX

BO_ 1058 location11_D: 8 Bosch_Radar1
 SG_ Loc11_vRel : 52|10@0+ (0.125,-64) [-64|63.875] "m/s" Vector__XXX
 SG_ Loc11_Power4 : 43|7@0+ (1,-64) [-64|63] "dBm^2" Vector__XXX
 SG_ Loc11_Power3 : 34|7@0+ (1,-64) [-64|63] "dBm^2" Vector__XXX
 SG_ Loc11_Power2 : 25|7@0+ (1,-64) [-64|63] "dBm^2" Vector__XXX
 SG_ Loc11_Power1 : 16|7@0+ (1,-64) [-64|63] "dBm^2" Vector__XXX
 SG_ Loc11_Power0 : 23|7@0+ (1,-64) [-64|63] "dBm^2" Vector__XXX
 SG_ Loc11_YAngle4 : 7|16@0+ (6.103608E-005,-2) [-2|1.9999995028] "rad" Vector__XXX

BO_ 1059 location12_A: 8 Bosch_Radar1
 SG_ Loc12_Status : 62|1@0+ (1,0) [0|1] "" Vector__XXX
 SG_ Loc12_AngleType : 63|1@0+ (1,0) [0|1] "" Vector__XXX
 SG_ Loc12_YExistProb4 : 55|8@0+ (0.00390625,0) [0|1] "" Vector__XXX
 SG_ Loc12_YExistProb3 : 47|8@0+ (0.00390625,0) [0|1] "" Vector__XXX
 SG_ Loc12_YExistProb2 : 39|8@0+ (0.00390625,0) [0|1] "" Vector__XXX
 SG_ Loc12_YExistProb1 : 31|8@0+ (0.00390625,0) [0|1] "" Vector__XXX
 SG_ Loc12_YExistProb0 : 23|8@0+ (0.00390625,0) [0|1] "" Vector__XXX
 SG_ Loc12_RadialDist : 7|16@0+ (0.0039063,0) [0|255.9993705] "m" Vector__XXX

BO_ 1060 location12_B: 8 Bosch_Radar1
 SG_ Loc12_ZCorrelated : 53|10@0+ (0.00390625,-2) [-2|1.99609375] "rad" Vector__XXX
 SG_ Loc12_YSigmaAngle4 : 25|10@0+ (0.00012207,0) [0|0.12487761] "rad" Vector__XXX
 SG_ Loc12_YSigmaAngle3 : 47|10@0+ (0.00012207,0) [0|0.12487761] "rad" Vector__XXX
 SG_ Loc12_YSigmaAngle2 : 19|10@0+ (0.00012207,0) [0|0.12487761] "rad" Vector__XXX
 SG_ Loc12_YSigmaAngle1 : 13|10@0+ (0.00012207,0) [0|0.12487761] "rad" Vector__XXX
 SG_ Loc12_YSigmaAngle0 : 7|10@0+ (0.00012207,0) [0|0.12487761] "rad" Vector__XXX

BO_ 1061 location12_C: 8 Bosch_Radar1
 SG_ Loc12_YAngle3 : 55|16@0+ (6.103608E-005,-2) [-2|1.9999995028] "rad" Vector__XXX
 SG_ Loc12_YAngle2 : 39|16@0+ (6.103608E-005,-2) [-2|1.9999995028] "rad" Vector__XXX
 SG_ Loc12_YAngle1 : 23|16@0+ (6.103608E-005,-2) [-2|1.9999995028] "rad" Vector__XXX
 SG_ Loc12_YAngle0 : 7|16@0+ (6.103608E-005,-2) [-2|1.9999995028] "rad" Vector__XXX

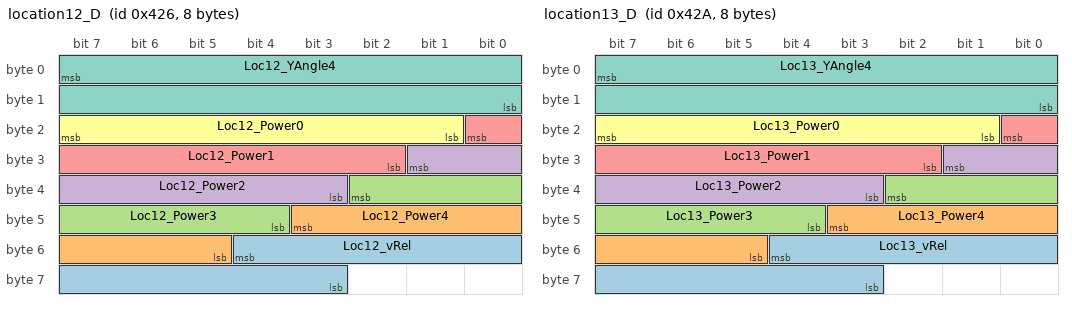
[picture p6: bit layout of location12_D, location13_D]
BO_ 1062 location12_D: 8 Bosch_Radar1
 SG_ Loc12_vRel : 52|10@0+ (0.125,-64) [-64|63.875] "m/s" Vector__XXX
 SG_ Loc12_Power4 : 43|7@0+ (1,-64) [-64|63] "dBm^2" Vector__XXX
 SG_ Loc12_Power3 : 34|7@0+ (1,-64) [-64|63] "dBm^2" Vector__XXX
 SG_ Loc12_Power2 : 25|7@0+ (1,-64) [-64|63] "dBm^2" Vector__XXX
 SG_ Loc12_Power1 : 16|7@0+ (1,-64) [-64|63] "dBm^2" Vector__XXX
 SG_ Loc12_Power0 : 23|7@0+ (1,-64) [-64|63] "dBm^2" Vector__XXX
 SG_ Loc12_YAngle4 : 7|16@0+ (6.103608E-005,-2) [-2|1.9999995028] "rad" Vector__XXX

BO_ 1063 location13_A: 8 Bosch_Radar1
 SG_ Loc13_Status : 62|1@0+ (1,0) [0|1] "" Vector__XXX
 SG_ Loc13_AngleType : 63|1@0+ (1,0) [0|1] "" Vector__XXX
 SG_ Loc13_YExistProb4 : 55|8@0+ (0.00390625,0) [0|1] "" Vector__XXX
 SG_ Loc13_YExistProb3 : 47|8@0+ (0.00390625,0) [0|1] "" Vector__XXX
 SG_ Loc13_YExistProb2 : 39|8@0+ (0.00390625,0) [0|1] "" Vector__XXX
 SG_ Loc13_YExistProb1 : 31|8@0+ (0.00390625,0) [0|1] "" Vector__XXX
 SG_ Loc13_YExistProb0 : 23|8@0+ (0.00390625,0) [0|1] "" Vector__XXX
 SG_ Loc13_RadialDist : 7|16@0+ (0.0039063,0) [0|255.9993705] "m" Vector__XXX

BO_ 1064 location13_B: 8 Bosch_Radar1
 SG_ Loc13_ZCorrelated : 53|10@0+ (0.00390625,-2) [-2|1.99609375] "rad" Vector__XXX
 SG_ Loc13_YSigmaAngle4 : 25|10@0+ (0.00012207,0) [0|0.12487761] "rad" Vector__XXX
 SG_ Loc13_YSigmaAngle3 : 47|10@0+ (0.00012207,0) [0|0.12487761] "rad" Vector__XXX
 SG_ Loc13_YSigmaAngle2 : 19|10@0+ (0.00012207,0) [0|0.12487761] "rad" Vector__XXX
 SG_ Loc13_YSigmaAngle1 : 13|10@0+ (0.00012207,0) [0|0.12487761] "rad" Vector__XXX
 SG_ Loc13_YSigmaAngle0 : 7|10@0+ (0.00012207,0) [0|0.12487761] "rad" Vector__XXX

BO_ 1065 location13_C: 8 Bosch_Radar1
 SG_ Loc13_YAngle3 : 55|16@0+ (6.103608E-005,-2) [-2|1.9999995028] "rad" Vector__XXX
 SG_ Loc13_YAngle2 : 39|16@0+ (6.103608E-005,-2) [-2|1.9999995028] "rad" Vector__XXX
 SG_ Loc13_YAngle1 : 23|16@0+ (6.103608E-005,-2) [-2|1.9999995028] "rad" Vector__XXX
 SG_ Loc13_YAngle0 : 7|16@0+ (6.103608E-005,-2) [-2|1.9999995028] "rad" Vector__XXX

BO_ 1066 location13_D: 8 Bosch_Radar1
 SG_ Loc13_vRel : 52|10@0+ (0.125,-64) [-64|63.875] "m/s" Vector__XXX
 SG_ Loc13_Power4 : 43|7@0+ (1,-64) [-64|63] "dBm^2" Vector__XXX
 SG_ Loc13_Power3 : 34|7@0+ (1,-64) [-64|63] "dBm^2" Vector__XXX
 SG_ Loc13_Power2 : 25|7@0+ (1,-64) [-64|63] "dBm^2" Vector__XXX
 SG_ Loc13_Power1 : 16|7@0+ (1,-64) [-64|63] "dBm^2" Vector__XXX
 SG_ Loc13_Power0 : 23|7@0+ (1,-64) [-64|63] "dBm^2" Vector__XXX
 SG_ Loc13_YAngle4 : 7|16@0+ (6.103608E-005,-2) [-2|1.9999995028] "rad" Vector__XXX

BO_ 1067 location14_A: 8 Bosch_Radar1
 SG_ Loc14_Status : 62|1@0+ (1,0) [0|1] "" Vector__XXX
 SG_ Loc14_AngleType : 63|1@0+ (1,0) [0|1] "" Vector__XXX
 SG_ Loc14_YExistProb4 : 55|8@0+ (0.00390625,0) [0|1] "" Vector__XXX
 SG_ Loc14_YExistProb3 : 47|8@0+ (0.00390625,0) [0|1] "" Vector__XXX
 SG_ Loc14_YExistProb2 : 39|8@0+ (0.00390625,0) [0|1] "" Vector__XXX
 SG_ Loc14_YExistProb1 : 31|8@0+ (0.00390625,0) [0|1] "" Vector__XXX
 SG_ Loc14_YExistProb0 : 23|8@0+ (0.00390625,0) [0|1] "" Vector__XXX
 SG_ Loc14_RadialDist : 7|16@0+ (0.0039063,0) [0|255.9993705] "m" Vector__XXX

BO_ 1068 location14_B: 8 Bosch_Radar1
 SG_ Loc14_ZCorrelated : 53|10@0+ (0.00390625,-2) [-2|1.99609375] "rad" Vector__XXX
 SG_ Loc14_YSigmaAngle4 : 25|10@0+ (0.00012207,0) [0|0.12487761] "rad" Vector__XXX
 SG_ Loc14_YSigmaAngle3 : 47|10@0+ (0.00012207,0) [0|0.12487761] "rad" Vector__XXX
 SG_ Loc14_YSigmaAngle2 : 19|10@0+ (0.00012207,0) [0|0.12487761] "rad" Vector__XXX
 SG_ Loc14_YSigmaAngle1 : 13|10@0+ (0.00012207,0) [0|0.12487761] "rad" Vector__XXX
 SG_ Loc14_YSigmaAngle0 : 7|10@0+ (0.00012207,0) [0|0.12487761] "rad" Vector__XXX

BO_ 1069 location14_C: 8 Bosch_Radar1
 SG_ Loc14_YAngle3 : 55|16@0+ (6.103608E-005,-2) [-2|1.9999995028] "rad" Vector__XXX
 SG_ Loc14_YAngle2 : 39|16@0+ (6.103608E-005,-2) [-2|1.9999995028] "rad" Vector__XXX
 SG_ Loc14_YAngle1 : 23|16@0+ (6.103608E-005,-2) [-2|1.9999995028] "rad" Vector__XXX
 SG_ Loc14_YAngle0 : 7|16@0+ (6.103608E-005,-2) [-2|1.9999995028] "rad" Vector__XXX

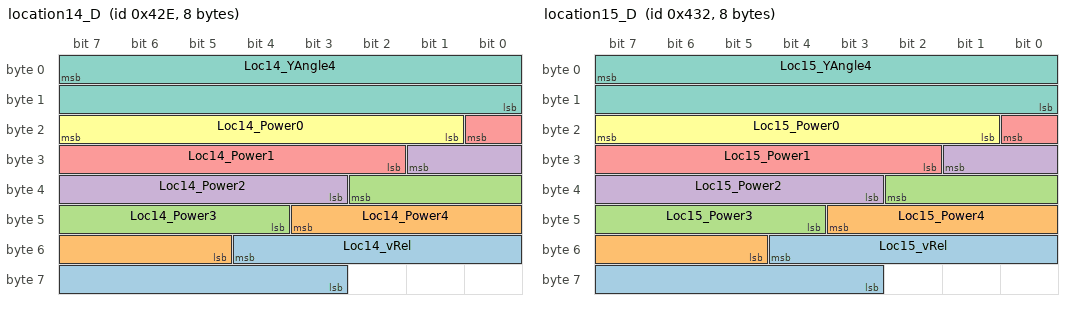
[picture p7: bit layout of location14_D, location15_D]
BO_ 1070 location14_D: 8 Bosch_Radar1
 SG_ Loc14_vRel : 52|10@0+ (0.125,-64) [-64|63.875] "m/s" Vector__XXX
 SG_ Loc14_Power4 : 43|7@0+ (1,-64) [-64|63] "dBm^2" Vector__XXX
 SG_ Loc14_Power3 : 34|7@0+ (1,-64) [-64|63] "dBm^2" Vector__XXX
 SG_ Loc14_Power2 : 25|7@0+ (1,-64) [-64|63] "dBm^2" Vector__XXX
 SG_ Loc14_Power1 : 16|7@0+ (1,-64) [-64|63] "dBm^2" Vector__XXX
 SG_ Loc14_Power0 : 23|7@0+ (1,-64) [-64|63] "dBm^2" Vector__XXX
 SG_ Loc14_YAngle4 : 7|16@0+ (6.103608E-005,-2) [-2|1.9999995028] "rad" Vector__XXX

BO_ 1071 location15_A: 8 Bosch_Radar1
 SG_ Loc15_Status : 62|1@0+ (1,0) [0|1] "" Vector__XXX
 SG_ Loc15_AngleType : 63|1@0+ (1,0) [0|1] "" Vector__XXX
 SG_ Loc15_YExistProb4 : 55|8@0+ (0.00390625,0) [0|1] "" Vector__XXX
 SG_ Loc15_YExistProb3 : 47|8@0+ (0.00390625,0) [0|1] "" Vector__XXX
 SG_ Loc15_YExistProb2 : 39|8@0+ (0.00390625,0) [0|1] "" Vector__XXX
 SG_ Loc15_YExistProb1 : 31|8@0+ (0.00390625,0) [0|1] "" Vector__XXX
 SG_ Loc15_YExistProb0 : 23|8@0+ (0.00390625,0) [0|1] "" Vector__XXX
 SG_ Loc15_RadialDist : 7|16@0+ (0.0039063,0) [0|255.9993705] "m" Vector__XXX

BO_ 1072 location15_B: 8 Bosch_Radar1
 SG_ Loc15_ZCorrelated : 53|10@0+ (0.00390625,-2) [-2|1.99609375] "rad" Vector__XXX
 SG_ Loc15_YSigmaAngle4 : 25|10@0+ (0.00012207,0) [0|0.12487761] "rad" Vector__XXX
 SG_ Loc15_YSigmaAngle3 : 47|10@0+ (0.00012207,0) [0|0.12487761] "rad" Vector__XXX
 SG_ Loc15_YSigmaAngle2 : 19|10@0+ (0.00012207,0) [0|0.12487761] "rad" Vector__XXX
 SG_ Loc15_YSigmaAngle1 : 13|10@0+ (0.00012207,0) [0|0.12487761] "rad" Vector__XXX
 SG_ Loc15_YSigmaAngle0 : 7|10@0+ (0.00012207,0) [0|0.12487761] "rad" Vector__XXX

BO_ 1073 location15_C: 8 Bosch_Radar1
 SG_ Loc15_YAngle3 : 55|16@0+ (6.103608E-005,-2) [-2|1.9999995028] "rad" Vector__XXX
 SG_ Loc15_YAngle2 : 39|16@0+ (6.103608E-005,-2) [-2|1.9999995028] "rad" Vector__XXX
 SG_ Loc15_YAngle1 : 23|16@0+ (6.103608E-005,-2) [-2|1.9999995028] "rad" Vector__XXX
 SG_ Loc15_YAngle0 : 7|16@0+ (6.103608E-005,-2) [-2|1.9999995028] "rad" Vector__XXX

BO_ 1074 location15_D: 8 Bosch_Radar1
 SG_ Loc15_vRel : 52|10@0+ (0.125,-64) [-64|63.875] "m/s" Vector__XXX
 SG_ Loc15_Power4 : 43|7@0+ (1,-64) [-64|63] "dBm^2" Vector__XXX
 SG_ Loc15_Power3 : 34|7@0+ (1,-64) [-64|63] "dBm^2" Vector__XXX
 SG_ Loc15_Power2 : 25|7@0+ (1,-64) [-64|63] "dBm^2" Vector__XXX
 SG_ Loc15_Power1 : 16|7@0+ (1,-64) [-64|63] "dBm^2" Vector__XXX
 SG_ Loc15_Power0 : 23|7@0+ (1,-64) [-64|63] "dBm^2" Vector__XXX
 SG_ Loc15_YAngle4 : 7|16@0+ (6.103608E-005,-2) [-2|1.9999995028] "rad" Vector__XXX

BO_ 1075 location16_A: 8 Bosch_Radar1
 SG_ Loc16_Status : 62|1@0+ (1,0) [0|1] "" Vector__XXX
 SG_ Loc16_AngleType : 63|1@0+ (1,0) [0|1] "" Vector__XXX
 SG_ Loc16_YExistProb4 : 55|8@0+ (0.00390625,0) [0|1] "" Vector__XXX
 SG_ Loc16_YExistProb3 : 47|8@0+ (0.00390625,0) [0|1] "" Vector__XXX
 SG_ Loc16_YExistProb2 : 39|8@0+ (0.00390625,0) [0|1] "" Vector__XXX
 SG_ Loc16_YExistProb1 : 31|8@0+ (0.00390625,0) [0|1] "" Vector__XXX
 SG_ Loc16_YExistProb0 : 23|8@0+ (0.00390625,0) [0|1] "" Vector__XXX
 SG_ Loc16_RadialDist : 7|16@0+ (0.0039063,0) [0|255.9993705] "m" Vector__XXX

BO_ 1076 location16_B: 8 Bosch_Radar1
 SG_ Loc16_ZCorrelated : 53|10@0+ (0.00390625,-2) [-2|1.99609375] "rad" Vector__XXX
 SG_ Loc16_YSigmaAngle4 : 25|10@0+ (0.00012207,0) [0|0.12487761] "rad" Vector__XXX
 SG_ Loc16_YSigmaAngle3 : 47|10@0+ (0.00012207,0) [0|0.12487761] "rad" Vector__XXX
 SG_ Loc16_YSigmaAngle2 : 19|10@0+ (0.00012207,0) [0|0.12487761] "rad" Vector__XXX
 SG_ Loc16_YSigmaAngle1 : 13|10@0+ (0.00012207,0) [0|0.12487761] "rad" Vector__XXX
 SG_ Loc16_YSigmaAngle0 : 7|10@0+ (0.00012207,0) [0|0.12487761] "rad" Vector__XXX

BO_ 1077 location16_C: 8 Bosch_Radar1
 SG_ Loc16_YAngle3 : 55|16@0+ (6.103608E-005,-2) [-2|1.9999995028] "rad" Vector__XXX
 SG_ Loc16_YAngle2 : 39|16@0+ (6.103608E-005,-2) [-2|1.9999995028] "rad" Vector__XXX
 SG_ Loc16_YAngle1 : 23|16@0+ (6.103608E-005,-2) [-2|1.9999995028] "rad" Vector__XXX
 SG_ Loc16_YAngle0 : 7|16@0+ (6.103608E-005,-2) [-2|1.9999995028] "rad" Vector__XXX

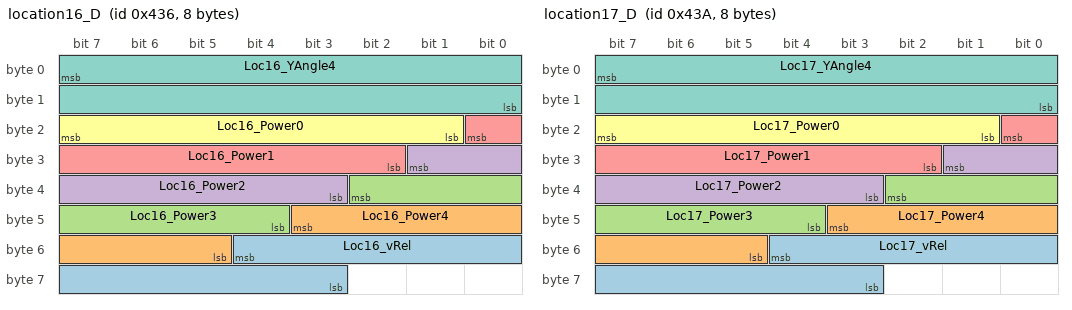
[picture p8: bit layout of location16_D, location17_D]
BO_ 1078 location16_D: 8 Bosch_Radar1
 SG_ Loc16_vRel : 52|10@0+ (0.125,-64) [-64|63.875] "m/s" Vector__XXX
 SG_ Loc16_Power4 : 43|7@0+ (1,-64) [-64|63] "dBm^2" Vector__XXX
 SG_ Loc16_Power3 : 34|7@0+ (1,-64) [-64|63] "dBm^2" Vector__XXX
 SG_ Loc16_Power2 : 25|7@0+ (1,-64) [-64|63] "dBm^2" Vector__XXX
 SG_ Loc16_Power1 : 16|7@0+ (1,-64) [-64|63] "dBm^2" Vector__XXX
 SG_ Loc16_Power0 : 23|7@0+ (1,-64) [-64|63] "dBm^2" Vector__XXX
 SG_ Loc16_YAngle4 : 7|16@0+ (6.103608E-005,-2) [-2|1.9999995028] "rad" Vector__XXX

BO_ 1079 location17_A: 8 Bosch_Radar1
 SG_ Loc17_Status : 62|1@0+ (1,0) [0|1] "" Vector__XXX
 SG_ Loc17_AngleType : 63|1@0+ (1,0) [0|1] "" Vector__XXX
 SG_ Loc17_YExistProb4 : 55|8@0+ (0.00390625,0) [0|1] "" Vector__XXX
 SG_ Loc17_YExistProb3 : 47|8@0+ (0.00390625,0) [0|1] "" Vector__XXX
 SG_ Loc17_YExistProb2 : 39|8@0+ (0.00390625,0) [0|1] "" Vector__XXX
 SG_ Loc17_YExistProb1 : 31|8@0+ (0.00390625,0) [0|1] "" Vector__XXX
 SG_ Loc17_YExistProb0 : 23|8@0+ (0.00390625,0) [0|1] "" Vector__XXX
 SG_ Loc17_RadialDist : 7|16@0+ (0.0039063,0) [0|255.9993705] "m" Vector__XXX

BO_ 1080 location17_B: 8 Bosch_Radar1
 SG_ Loc17_ZCorrelated : 53|10@0+ (0.00390625,-2) [-2|1.99609375] "rad" Vector__XXX
 SG_ Loc17_YSigmaAngle4 : 25|10@0+ (0.00012207,0) [0|0.12487761] "rad" Vector__XXX
 SG_ Loc17_YSigmaAngle3 : 47|10@0+ (0.00012207,0) [0|0.12487761] "rad" Vector__XXX
 SG_ Loc17_YSigmaAngle2 : 19|10@0+ (0.00012207,0) [0|0.12487761] "rad" Vector__XXX
 SG_ Loc17_YSigmaAngle1 : 13|10@0+ (0.00012207,0) [0|0.12487761] "rad" Vector__XXX
 SG_ Loc17_YSigmaAngle0 : 7|10@0+ (0.00012207,0) [0|0.12487761] "rad" Vector__XXX

BO_ 1081 location17_C: 8 Bosch_Radar1
 SG_ Loc17_YAngle3 : 55|16@0+ (6.103608E-005,-2) [-2|1.9999995028] "rad" Vector__XXX
 SG_ Loc17_YAngle2 : 39|16@0+ (6.103608E-005,-2) [-2|1.9999995028] "rad" Vector__XXX
 SG_ Loc17_YAngle1 : 23|16@0+ (6.103608E-005,-2) [-2|1.9999995028] "rad" Vector__XXX
 SG_ Loc17_YAngle0 : 7|16@0+ (6.103608E-005,-2) [-2|1.9999995028] "rad" Vector__XXX

BO_ 1082 location17_D: 8 Bosch_Radar1
 SG_ Loc17_vRel : 52|10@0+ (0.125,-64) [-64|63.875] "m/s" Vector__XXX
 SG_ Loc17_Power4 : 43|7@0+ (1,-64) [-64|63] "dBm^2" Vector__XXX
 SG_ Loc17_Power3 : 34|7@0+ (1,-64) [-64|63] "dBm^2" Vector__XXX
 SG_ Loc17_Power2 : 25|7@0+ (1,-64) [-64|63] "dBm^2" Vector__XXX
 SG_ Loc17_Power1 : 16|7@0+ (1,-64) [-64|63] "dBm^2" Vector__XXX
 SG_ Loc17_Power0 : 23|7@0+ (1,-64) [-64|63] "dBm^2" Vector__XXX
 SG_ Loc17_YAngle4 : 7|16@0+ (6.103608E-005,-2) [-2|1.9999995028] "rad" Vector__XXX

BO_ 1083 location18_A: 8 Bosch_Radar1
 SG_ Loc18_Status : 62|1@0+ (1,0) [0|1] "" Vector__XXX
 SG_ Loc18_AngleType : 63|1@0+ (1,0) [0|1] "" Vector__XXX
 SG_ Loc18_YExistProb4 : 55|8@0+ (0.00390625,0) [0|1] "" Vector__XXX
 SG_ Loc18_YExistProb3 : 47|8@0+ (0.00390625,0) [0|1] "" Vector__XXX
 SG_ Loc18_YExistProb2 : 39|8@0+ (0.00390625,0) [0|1] "" Vector__XXX
 SG_ Loc18_YExistProb1 : 31|8@0+ (0.00390625,0) [0|1] "" Vector__XXX
 SG_ Loc18_YExistProb0 : 23|8@0+ (0.00390625,0) [0|1] "" Vector__XXX
 SG_ Loc18_RadialDist : 7|16@0+ (0.0039063,0) [0|255.9993705] "m" Vector__XXX

BO_ 1084 location18_B: 8 Bosch_Radar1
 SG_ Loc18_ZCorrelated : 53|10@0+ (0.00390625,-2) [-2|1.99609375] "rad" Vector__XXX
 SG_ Loc18_YSigmaAngle4 : 25|10@0+ (0.00012207,0) [0|0.12487761] "rad" Vector__XXX
 SG_ Loc18_YSigmaAngle3 : 47|10@0+ (0.00012207,0) [0|0.12487761] "rad" Vector__XXX
 SG_ Loc18_YSigmaAngle2 : 19|10@0+ (0.00012207,0) [0|0.12487761] "rad" Vector__XXX
 SG_ Loc18_YSigmaAngle1 : 13|10@0+ (0.00012207,0) [0|0.12487761] "rad" Vector__XXX
 SG_ Loc18_YSigmaAngle0 : 7|10@0+ (0.00012207,0) [0|0.12487761] "rad" Vector__XXX

BO_ 1085 location18_C: 8 Bosch_Radar1
 SG_ Loc18_YAngle3 : 55|16@0+ (6.103608E-005,-2) [-2|1.9999995028] "rad" Vector__XXX
 SG_ Loc18_YAngle2 : 39|16@0+ (6.103608E-005,-2) [-2|1.9999995028] "rad" Vector__XXX
 SG_ Loc18_YAngle1 : 23|16@0+ (6.103608E-005,-2) [-2|1.9999995028] "rad" Vector__XXX
 SG_ Loc18_YAngle0 : 7|16@0+ (6.103608E-005,-2) [-2|1.9999995028] "rad" Vector__XXX

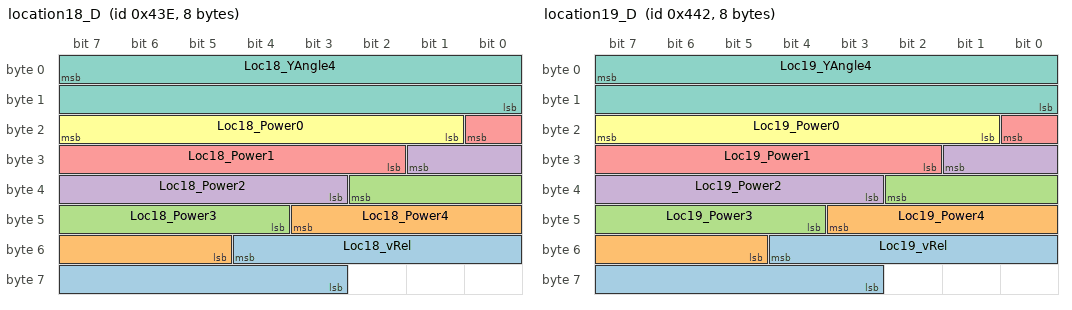
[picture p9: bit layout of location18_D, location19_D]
BO_ 1086 location18_D: 8 Bosch_Radar1
 SG_ Loc18_vRel : 52|10@0+ (0.125,-64) [-64|63.875] "m/s" Vector__XXX
 SG_ Loc18_Power4 : 43|7@0+ (1,-64) [-64|63] "dBm^2" Vector__XXX
 SG_ Loc18_Power3 : 34|7@0+ (1,-64) [-64|63] "dBm^2" Vector__XXX
 SG_ Loc18_Power2 : 25|7@0+ (1,-64) [-64|63] "dBm^2" Vector__XXX
 SG_ Loc18_Power1 : 16|7@0+ (1,-64) [-64|63] "dBm^2" Vector__XXX
 SG_ Loc18_Power0 : 23|7@0+ (1,-64) [-64|63] "dBm^2" Vector__XXX
 SG_ Loc18_YAngle4 : 7|16@0+ (6.103608E-005,-2) [-2|1.9999995028] "rad" Vector__XXX

BO_ 1087 location19_A: 8 Bosch_Radar1
 SG_ Loc19_Status : 62|1@0+ (1,0) [0|1] "" Vector__XXX
 SG_ Loc19_AngleType : 63|1@0+ (1,0) [0|1] "" Vector__XXX
 SG_ Loc19_YExistProb4 : 55|8@0+ (0.00390625,0) [0|1] "" Vector__XXX
 SG_ Loc19_YExistProb3 : 47|8@0+ (0.00390625,0) [0|1] "" Vector__XXX
 SG_ Loc19_YExistProb2 : 39|8@0+ (0.00390625,0) [0|1] "" Vector__XXX
 SG_ Loc19_YExistProb1 : 31|8@0+ (0.00390625,0) [0|1] "" Vector__XXX
 SG_ Loc19_YExistProb0 : 23|8@0+ (0.00390625,0) [0|1] "" Vector__XXX
 SG_ Loc19_RadialDist : 7|16@0+ (0.0039063,0) [0|255.9993705] "m" Vector__XXX

BO_ 1088 location19_B: 8 Bosch_Radar1
 SG_ Loc19_ZCorrelated : 53|10@0+ (0.00390625,-2) [-2|1.99609375] "rad" Vector__XXX
 SG_ Loc19_YSigmaAngle4 : 25|10@0+ (0.00012207,0) [0|0.12487761] "rad" Vector__XXX
 SG_ Loc19_YSigmaAngle3 : 47|10@0+ (0.00012207,0) [0|0.12487761] "rad" Vector__XXX
 SG_ Loc19_YSigmaAngle2 : 19|10@0+ (0.00012207,0) [0|0.12487761] "rad" Vector__XXX
 SG_ Loc19_YSigmaAngle1 : 13|10@0+ (0.00012207,0) [0|0.12487761] "rad" Vector__XXX
 SG_ Loc19_YSigmaAngle0 : 7|10@0+ (0.00012207,0) [0|0.12487761] "rad" Vector__XXX

BO_ 1089 location19_C: 8 Bosch_Radar1
 SG_ Loc19_YAngle3 : 55|16@0+ (6.103608E-005,-2) [-2|1.9999995028] "rad" Vector__XXX
 SG_ Loc19_YAngle2 : 39|16@0+ (6.103608E-005,-2) [-2|1.9999995028] "rad" Vector__XXX
 SG_ Loc19_YAngle1 : 23|16@0+ (6.103608E-005,-2) [-2|1.9999995028] "rad" Vector__XXX
 SG_ Loc19_YAngle0 : 7|16@0+ (6.103608E-005,-2) [-2|1.9999995028] "rad" Vector__XXX

BO_ 1090 location19_D: 8 Bosch_Radar1
 SG_ Loc19_vRel : 52|10@0+ (0.125,-64) [-64|63.875] "m/s" Vector__XXX
 SG_ Loc19_Power4 : 43|7@0+ (1,-64) [-64|63] "dBm^2" Vector__XXX
 SG_ Loc19_Power3 : 34|7@0+ (1,-64) [-64|63] "dBm^2" Vector__XXX
 SG_ Loc19_Power2 : 25|7@0+ (1,-64) [-64|63] "dBm^2" Vector__XXX
 SG_ Loc19_Power1 : 16|7@0+ (1,-64) [-64|63] "dBm^2" Vector__XXX
 SG_ Loc19_Power0 : 23|7@0+ (1,-64) [-64|63] "dBm^2" Vector__XXX
 SG_ Loc19_YAngle4 : 7|16@0+ (6.103608E-005,-2) [-2|1.9999995028] "rad" Vector__XXX

BO_ 1091 location20_A: 8 Bosch_Radar1
 SG_ Loc20_Status : 62|1@0+ (1,0) [0|1] "" Vector__XXX
 SG_ Loc20_AngleType : 63|1@0+ (1,0) [0|1] "" Vector__XXX
 SG_ Loc20_YExistProb4 : 55|8@0+ (0.00390625,0) [0|1] "" Vector__XXX
 SG_ Loc20_YExistProb3 : 47|8@0+ (0.00390625,0) [0|1] "" Vector__XXX
 SG_ Loc20_YExistProb2 : 39|8@0+ (0.00390625,0) [0|1] "" Vector__XXX
 SG_ Loc20_YExistProb1 : 31|8@0+ (0.00390625,0) [0|1] "" Vector__XXX
 SG_ Loc20_YExistProb0 : 23|8@0+ (0.00390625,0) [0|1] "" Vector__XXX
 SG_ Loc20_RadialDist : 7|16@0+ (0.0039063,0) [0|255.9993705] "m" Vector__XXX

BO_ 1092 location20_B: 8 Bosch_Radar1
 SG_ Loc20_ZCorrelated : 53|10@0+ (0.00390625,-2) [-2|1.99609375] "rad" Vector__XXX
 SG_ Loc20_YSigmaAngle4 : 25|10@0+ (0.00012207,0) [0|0.12487761] "rad" Vector__XXX
 SG_ Loc20_YSigmaAngle3 : 47|10@0+ (0.00012207,0) [0|0.12487761] "rad" Vector__XXX
 SG_ Loc20_YSigmaAngle2 : 19|10@0+ (0.00012207,0) [0|0.12487761] "rad" Vector__XXX
 SG_ Loc20_YSigmaAngle1 : 13|10@0+ (0.00012207,0) [0|0.12487761] "rad" Vector__XXX
 SG_ Loc20_YSigmaAngle0 : 7|10@0+ (0.00012207,0) [0|0.12487761] "rad" Vector__XXX

BO_ 1093 location20_C: 8 Bosch_Radar1
 SG_ Loc20_YAngle3 : 55|16@0+ (6.103608E-005,-2) [-2|1.9999995028] "rad" Vector__XXX
 SG_ Loc20_YAngle2 : 39|16@0+ (6.103608E-005,-2) [-2|1.9999995028] "rad" Vector__XXX
 SG_ Loc20_YAngle1 : 23|16@0+ (6.103608E-005,-2) [-2|1.9999995028] "rad" Vector__XXX
 SG_ Loc20_YAngle0 : 7|16@0+ (6.103608E-005,-2) [-2|1.9999995028] "rad" Vector__XXX

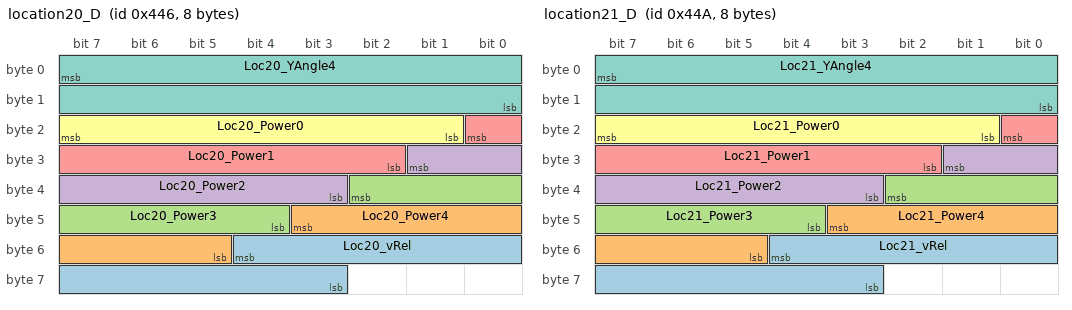
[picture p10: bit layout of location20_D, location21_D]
BO_ 1094 location20_D: 8 Bosch_Radar1
 SG_ Loc20_vRel : 52|10@0+ (0.125,-64) [-64|63.875] "m/s" Vector__XXX
 SG_ Loc20_Power4 : 43|7@0+ (1,-64) [-64|63] "dBm^2" Vector__XXX
 SG_ Loc20_Power3 : 34|7@0+ (1,-64) [-64|63] "dBm^2" Vector__XXX
 SG_ Loc20_Power2 : 25|7@0+ (1,-64) [-64|63] "dBm^2" Vector__XXX
 SG_ Loc20_Power1 : 16|7@0+ (1,-64) [-64|63] "dBm^2" Vector__XXX
 SG_ Loc20_Power0 : 23|7@0+ (1,-64) [-64|63] "dBm^2" Vector__XXX
 SG_ Loc20_YAngle4 : 7|16@0+ (6.103608E-005,-2) [-2|1.9999995028] "rad" Vector__XXX

BO_ 1095 location21_A: 8 Bosch_Radar1
 SG_ Loc21_Status : 62|1@0+ (1,0) [0|1] "" Vector__XXX
 SG_ Loc21_AngleType : 63|1@0+ (1,0) [0|1] "" Vector__XXX
 SG_ Loc21_YExistProb4 : 55|8@0+ (0.00390625,0) [0|1] "" Vector__XXX
 SG_ Loc21_YExistProb3 : 47|8@0+ (0.00390625,0) [0|1] "" Vector__XXX
 SG_ Loc21_YExistProb2 : 39|8@0+ (0.00390625,0) [0|1] "" Vector__XXX
 SG_ Loc21_YExistProb1 : 31|8@0+ (0.00390625,0) [0|1] "" Vector__XXX
 SG_ Loc21_YExistProb0 : 23|8@0+ (0.00390625,0) [0|1] "" Vector__XXX
 SG_ Loc21_RadialDist : 7|16@0+ (0.0039063,0) [0|255.9993705] "m" Vector__XXX

BO_ 1096 location21_B: 8 Bosch_Radar1
 SG_ Loc21_ZCorrelated : 53|10@0+ (0.00390625,-2) [-2|1.99609375] "rad" Vector__XXX
 SG_ Loc21_YSigmaAngle4 : 25|10@0+ (0.00012207,0) [0|0.12487761] "rad" Vector__XXX
 SG_ Loc21_YSigmaAngle3 : 47|10@0+ (0.00012207,0) [0|0.12487761] "rad" Vector__XXX
 SG_ Loc21_YSigmaAngle2 : 19|10@0+ (0.00012207,0) [0|0.12487761] "rad" Vector__XXX
 SG_ Loc21_YSigmaAngle1 : 13|10@0+ (0.00012207,0) [0|0.12487761] "rad" Vector__XXX
 SG_ Loc21_YSigmaAngle0 : 7|10@0+ (0.00012207,0) [0|0.12487761] "rad" Vector__XXX

BO_ 1097 location21_C: 8 Bosch_Radar1
 SG_ Loc21_YAngle3 : 55|16@0+ (6.103608E-005,-2) [-2|1.9999995028] "rad" Vector__XXX
 SG_ Loc21_YAngle2 : 39|16@0+ (6.103608E-005,-2) [-2|1.9999995028] "rad" Vector__XXX
 SG_ Loc21_YAngle1 : 23|16@0+ (6.103608E-005,-2) [-2|1.9999995028] "rad" Vector__XXX
 SG_ Loc21_YAngle0 : 7|16@0+ (6.103608E-005,-2) [-2|1.9999995028] "rad" Vector__XXX

BO_ 1098 location21_D: 8 Bosch_Radar1
 SG_ Loc21_vRel : 52|10@0+ (0.125,-64) [-64|63.875] "m/s" Vector__XXX
 SG_ Loc21_Power4 : 43|7@0+ (1,-64) [-64|63] "dBm^2" Vector__XXX
 SG_ Loc21_Power3 : 34|7@0+ (1,-64) [-64|63] "dBm^2" Vector__XXX
 SG_ Loc21_Power2 : 25|7@0+ (1,-64) [-64|63] "dBm^2" Vector__XXX
 SG_ Loc21_Power1 : 16|7@0+ (1,-64) [-64|63] "dBm^2" Vector__XXX
 SG_ Loc21_Power0 : 23|7@0+ (1,-64) [-64|63] "dBm^2" Vector__XXX
 SG_ Loc21_YAngle4 : 7|16@0+ (6.103608E-005,-2) [-2|1.9999995028] "rad" Vector__XXX

BO_ 1099 location22_A: 8 Bosch_Radar1
 SG_ Loc22_Status : 62|1@0+ (1,0) [0|1] "" Vector__XXX
 SG_ Loc22_AngleType : 63|1@0+ (1,0) [0|1] "" Vector__XXX
 SG_ Loc22_YExistProb4 : 55|8@0+ (0.00390625,0) [0|1] "" Vector__XXX
 SG_ Loc22_YExistProb3 : 47|8@0+ (0.00390625,0) [0|1] "" Vector__XXX
 SG_ Loc22_YExistProb2 : 39|8@0+ (0.00390625,0) [0|1] "" Vector__XXX
 SG_ Loc22_YExistProb1 : 31|8@0+ (0.00390625,0) [0|1] "" Vector__XXX
 SG_ Loc22_YExistProb0 : 23|8@0+ (0.00390625,0) [0|1] "" Vector__XXX
 SG_ Loc22_RadialDist : 7|16@0+ (0.0039063,0) [0|255.9993705] "m" Vector__XXX

BO_ 1100 location22_B: 8 Bosch_Radar1
 SG_ Loc22_ZCorrelated : 53|10@0+ (0.00390625,-2) [-2|1.99609375] "rad" Vector__XXX
 SG_ Loc22_YSigmaAngle4 : 25|10@0+ (0.00012207,0) [0|0.12487761] "rad" Vector__XXX
 SG_ Loc22_YSigmaAngle3 : 47|10@0+ (0.00012207,0) [0|0.12487761] "rad" Vector__XXX
 SG_ Loc22_YSigmaAngle2 : 19|10@0+ (0.00012207,0) [0|0.12487761] "rad" Vector__XXX
 SG_ Loc22_YSigmaAngle1 : 13|10@0+ (0.00012207,0) [0|0.12487761] "rad" Vector__XXX
 SG_ Loc22_YSigmaAngle0 : 7|10@0+ (0.00012207,0) [0|0.12487761] "rad" Vector__XXX

BO_ 1101 location22_C: 8 Bosch_Radar1
 SG_ Loc22_YAngle3 : 55|16@0+ (6.103608E-005,-2) [-2|1.9999995028] "rad" Vector__XXX
 SG_ Loc22_YAngle2 : 39|16@0+ (6.103608E-005,-2) [-2|1.9999995028] "rad" Vector__XXX
 SG_ Loc22_YAngle1 : 23|16@0+ (6.103608E-005,-2) [-2|1.9999995028] "rad" Vector__XXX
 SG_ Loc22_YAngle0 : 7|16@0+ (6.103608E-005,-2) [-2|1.9999995028] "rad" Vector__XXX

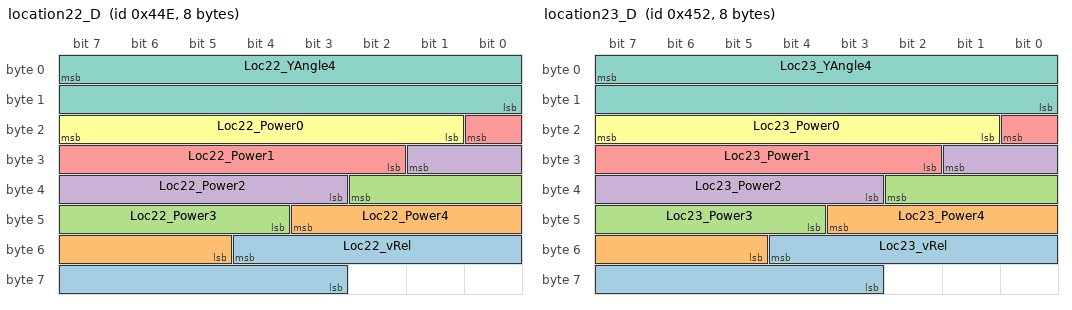
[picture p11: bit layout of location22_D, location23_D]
BO_ 1102 location22_D: 8 Bosch_Radar1
 SG_ Loc22_vRel : 52|10@0+ (0.125,-64) [-64|63.875] "m/s" Vector__XXX
 SG_ Loc22_Power4 : 43|7@0+ (1,-64) [-64|63] "dBm^2" Vector__XXX
 SG_ Loc22_Power3 : 34|7@0+ (1,-64) [-64|63] "dBm^2" Vector__XXX
 SG_ Loc22_Power2 : 25|7@0+ (1,-64) [-64|63] "dBm^2" Vector__XXX
 SG_ Loc22_Power1 : 16|7@0+ (1,-64) [-64|63] "dBm^2" Vector__XXX
 SG_ Loc22_Power0 : 23|7@0+ (1,-64) [-64|63] "dBm^2" Vector__XXX
 SG_ Loc22_YAngle4 : 7|16@0+ (6.103608E-005,-2) [-2|1.9999995028] "rad" Vector__XXX

BO_ 1103 location23_A: 8 Bosch_Radar1
 SG_ Loc23_Status : 62|1@0+ (1,0) [0|1] "" Vector__XXX
 SG_ Loc23_AngleType : 63|1@0+ (1,0) [0|1] "" Vector__XXX
 SG_ Loc23_YExistProb4 : 55|8@0+ (0.00390625,0) [0|1] "" Vector__XXX
 SG_ Loc23_YExistProb3 : 47|8@0+ (0.00390625,0) [0|1] "" Vector__XXX
 SG_ Loc23_YExistProb2 : 39|8@0+ (0.00390625,0) [0|1] "" Vector__XXX
 SG_ Loc23_YExistProb1 : 31|8@0+ (0.00390625,0) [0|1] "" Vector__XXX
 SG_ Loc23_YExistProb0 : 23|8@0+ (0.00390625,0) [0|1] "" Vector__XXX
 SG_ Loc23_RadialDist : 7|16@0+ (0.0039063,0) [0|255.9993705] "m" Vector__XXX

BO_ 1104 location23_B: 8 Bosch_Radar1
 SG_ Loc23_ZCorrelated : 53|10@0+ (0.00390625,-2) [-2|1.99609375] "rad" Vector__XXX
 SG_ Loc23_YSigmaAngle4 : 25|10@0+ (0.00012207,0) [0|0.12487761] "rad" Vector__XXX
 SG_ Loc23_YSigmaAngle3 : 47|10@0+ (0.00012207,0) [0|0.12487761] "rad" Vector__XXX
 SG_ Loc23_YSigmaAngle2 : 19|10@0+ (0.00012207,0) [0|0.12487761] "rad" Vector__XXX
 SG_ Loc23_YSigmaAngle1 : 13|10@0+ (0.00012207,0) [0|0.12487761] "rad" Vector__XXX
 SG_ Loc23_YSigmaAngle0 : 7|10@0+ (0.00012207,0) [0|0.12487761] "rad" Vector__XXX

BO_ 1105 location23_C: 8 Bosch_Radar1
 SG_ Loc23_YAngle3 : 55|16@0+ (6.103608E-005,-2) [-2|1.9999995028] "rad" Vector__XXX
 SG_ Loc23_YAngle2 : 39|16@0+ (6.103608E-005,-2) [-2|1.9999995028] "rad" Vector__XXX
 SG_ Loc23_YAngle1 : 23|16@0+ (6.103608E-005,-2) [-2|1.9999995028] "rad" Vector__XXX
 SG_ Loc23_YAngle0 : 7|16@0+ (6.103608E-005,-2) [-2|1.9999995028] "rad" Vector__XXX

BO_ 1106 location23_D: 8 Bosch_Radar1
 SG_ Loc23_vRel : 52|10@0+ (0.125,-64) [-64|63.875] "m/s" Vector__XXX
 SG_ Loc23_Power4 : 43|7@0+ (1,-64) [-64|63] "dBm^2" Vector__XXX
 SG_ Loc23_Power3 : 34|7@0+ (1,-64) [-64|63] "dBm^2" Vector__XXX
 SG_ Loc23_Power2 : 25|7@0+ (1,-64) [-64|63] "dBm^2" Vector__XXX
 SG_ Loc23_Power1 : 16|7@0+ (1,-64) [-64|63] "dBm^2" Vector__XXX
 SG_ Loc23_Power0 : 23|7@0+ (1,-64) [-64|63] "dBm^2" Vector__XXX
 SG_ Loc23_YAngle4 : 7|16@0+ (6.103608E-005,-2) [-2|1.9999995028] "rad" Vector__XXX

BO_ 1107 location24_A: 8 Bosch_Radar1
 SG_ Loc24_Status : 62|1@0+ (1,0) [0|1] "" Vector__XXX
 SG_ Loc24_AngleType : 63|1@0+ (1,0) [0|1] "" Vector__XXX
 SG_ Loc24_YExistProb4 : 55|8@0+ (0.00390625,0) [0|1] "" Vector__XXX
 SG_ Loc24_YExistProb3 : 47|8@0+ (0.00390625,0) [0|1] "" Vector__XXX
 SG_ Loc24_YExistProb2 : 39|8@0+ (0.00390625,0) [0|1] "" Vector__XXX
 SG_ Loc24_YExistProb1 : 31|8@0+ (0.00390625,0) [0|1] "" Vector__XXX
 SG_ Loc24_YExistProb0 : 23|8@0+ (0.00390625,0) [0|1] "" Vector__XXX
 SG_ Loc24_RadialDist : 7|16@0+ (0.0039063,0) [0|255.9993705] "m" Vector__XXX

BO_ 1108 location24_B: 8 Bosch_Radar1
 SG_ Loc24_ZCorrelated : 53|10@0+ (0.00390625,-2) [-2|1.99609375] "rad" Vector__XXX
 SG_ Loc24_YSigmaAngle4 : 25|10@0+ (0.00012207,0) [0|0.12487761] "rad" Vector__XXX
 SG_ Loc24_YSigmaAngle3 : 47|10@0+ (0.00012207,0) [0|0.12487761] "rad" Vector__XXX
 SG_ Loc24_YSigmaAngle2 : 19|10@0+ (0.00012207,0) [0|0.12487761] "rad" Vector__XXX
 SG_ Loc24_YSigmaAngle1 : 13|10@0+ (0.00012207,0) [0|0.12487761] "rad" Vector__XXX
 SG_ Loc24_YSigmaAngle0 : 7|10@0+ (0.00012207,0) [0|0.12487761] "rad" Vector__XXX

BO_ 1109 location24_C: 8 Bosch_Radar1
 SG_ Loc24_YAngle3 : 55|16@0+ (6.103608E-005,-2) [-2|1.9999995028] "rad" Vector__XXX
 SG_ Loc24_YAngle2 : 39|16@0+ (6.103608E-005,-2) [-2|1.9999995028] "rad" Vector__XXX
 SG_ Loc24_YAngle1 : 23|16@0+ (6.103608E-005,-2) [-2|1.9999995028] "rad" Vector__XXX
 SG_ Loc24_YAngle0 : 7|16@0+ (6.103608E-005,-2) [-2|1.9999995028] "rad" Vector__XXX

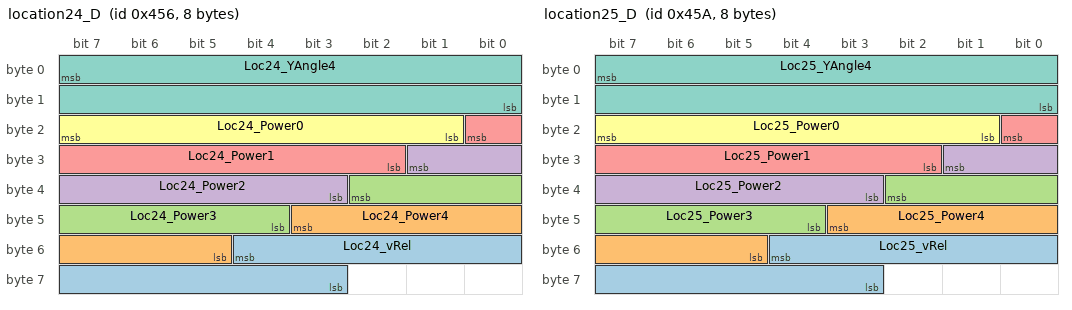
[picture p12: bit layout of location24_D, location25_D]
BO_ 1110 location24_D: 8 Bosch_Radar1
 SG_ Loc24_vRel : 52|10@0+ (0.125,-64) [-64|63.875] "m/s" Vector__XXX
 SG_ Loc24_Power4 : 43|7@0+ (1,-64) [-64|63] "dBm^2" Vector__XXX
 SG_ Loc24_Power3 : 34|7@0+ (1,-64) [-64|63] "dBm^2" Vector__XXX
 SG_ Loc24_Power2 : 25|7@0+ (1,-64) [-64|63] "dBm^2" Vector__XXX
 SG_ Loc24_Power1 : 16|7@0+ (1,-64) [-64|63] "dBm^2" Vector__XXX
 SG_ Loc24_Power0 : 23|7@0+ (1,-64) [-64|63] "dBm^2" Vector__XXX
 SG_ Loc24_YAngle4 : 7|16@0+ (6.103608E-005,-2) [-2|1.9999995028] "rad" Vector__XXX

BO_ 1111 location25_A: 8 Bosch_Radar1
 SG_ Loc25_Status : 62|1@0+ (1,0) [0|1] "" Vector__XXX
 SG_ Loc25_AngleType : 63|1@0+ (1,0) [0|1] "" Vector__XXX
 SG_ Loc25_YExistProb4 : 55|8@0+ (0.00390625,0) [0|1] "" Vector__XXX
 SG_ Loc25_YExistProb3 : 47|8@0+ (0.00390625,0) [0|1] "" Vector__XXX
 SG_ Loc25_YExistProb2 : 39|8@0+ (0.00390625,0) [0|1] "" Vector__XXX
 SG_ Loc25_YExistProb1 : 31|8@0+ (0.00390625,0) [0|1] "" Vector__XXX
 SG_ Loc25_YExistProb0 : 23|8@0+ (0.00390625,0) [0|1] "" Vector__XXX
 SG_ Loc25_RadialDist : 7|16@0+ (0.0039063,0) [0|255.9993705] "m" Vector__XXX

BO_ 1112 location25_B: 8 Bosch_Radar1
 SG_ Loc25_ZCorrelated : 53|10@0+ (0.00390625,-2) [-2|1.99609375] "rad" Vector__XXX
 SG_ Loc25_YSigmaAngle4 : 25|10@0+ (0.00012207,0) [0|0.12487761] "rad" Vector__XXX
 SG_ Loc25_YSigmaAngle3 : 47|10@0+ (0.00012207,0) [0|0.12487761] "rad" Vector__XXX
 SG_ Loc25_YSigmaAngle2 : 19|10@0+ (0.00012207,0) [0|0.12487761] "rad" Vector__XXX
 SG_ Loc25_YSigmaAngle1 : 13|10@0+ (0.00012207,0) [0|0.12487761] "rad" Vector__XXX
 SG_ Loc25_YSigmaAngle0 : 7|10@0+ (0.00012207,0) [0|0.12487761] "rad" Vector__XXX

BO_ 1113 location25_C: 8 Bosch_Radar1
 SG_ Loc25_YAngle3 : 55|16@0+ (6.103608E-005,-2) [-2|1.9999995028] "rad" Vector__XXX
 SG_ Loc25_YAngle2 : 39|16@0+ (6.103608E-005,-2) [-2|1.9999995028] "rad" Vector__XXX
 SG_ Loc25_YAngle1 : 23|16@0+ (6.103608E-005,-2) [-2|1.9999995028] "rad" Vector__XXX
 SG_ Loc25_YAngle0 : 7|16@0+ (6.103608E-005,-2) [-2|1.9999995028] "rad" Vector__XXX

BO_ 1114 location25_D: 8 Bosch_Radar1
 SG_ Loc25_vRel : 52|10@0+ (0.125,-64) [-64|63.875] "m/s" Vector__XXX
 SG_ Loc25_Power4 : 43|7@0+ (1,-64) [-64|63] "dBm^2" Vector__XXX
 SG_ Loc25_Power3 : 34|7@0+ (1,-64) [-64|63] "dBm^2" Vector__XXX
 SG_ Loc25_Power2 : 25|7@0+ (1,-64) [-64|63] "dBm^2" Vector__XXX
 SG_ Loc25_Power1 : 16|7@0+ (1,-64) [-64|63] "dBm^2" Vector__XXX
 SG_ Loc25_Power0 : 23|7@0+ (1,-64) [-64|63] "dBm^2" Vector__XXX
 SG_ Loc25_YAngle4 : 7|16@0+ (6.103608E-005,-2) [-2|1.9999995028] "rad" Vector__XXX

BO_ 1115 location26_A: 8 Bosch_Radar1
 SG_ Loc26_Status : 62|1@0+ (1,0) [0|1] "" Vector__XXX
 SG_ Loc26_AngleType : 63|1@0+ (1,0) [0|1] "" Vector__XXX
 SG_ Loc26_YExistProb4 : 55|8@0+ (0.00390625,0) [0|1] "" Vector__XXX
 SG_ Loc26_YExistProb3 : 47|8@0+ (0.00390625,0) [0|1] "" Vector__XXX
 SG_ Loc26_YExistProb2 : 39|8@0+ (0.00390625,0) [0|1] "" Vector__XXX
 SG_ Loc26_YExistProb1 : 31|8@0+ (0.00390625,0) [0|1] "" Vector__XXX
 SG_ Loc26_YExistProb0 : 23|8@0+ (0.00390625,0) [0|1] "" Vector__XXX
 SG_ Loc26_RadialDist : 7|16@0+ (0.0039063,0) [0|255.9993705] "m" Vector__XXX

BO_ 1116 location26_B: 8 Bosch_Radar1
 SG_ Loc26_ZCorrelated : 53|10@0+ (0.00390625,-2) [-2|1.99609375] "rad" Vector__XXX
 SG_ Loc26_YSigmaAngle4 : 25|10@0+ (0.00012207,0) [0|0.12487761] "rad" Vector__XXX
 SG_ Loc26_YSigmaAngle3 : 47|10@0+ (0.00012207,0) [0|0.12487761] "rad" Vector__XXX
 SG_ Loc26_YSigmaAngle2 : 19|10@0+ (0.00012207,0) [0|0.12487761] "rad" Vector__XXX
 SG_ Loc26_YSigmaAngle1 : 13|10@0+ (0.00012207,0) [0|0.12487761] "rad" Vector__XXX
 SG_ Loc26_YSigmaAngle0 : 7|10@0+ (0.00012207,0) [0|0.12487761] "rad" Vector__XXX

BO_ 1117 location26_C: 8 Bosch_Radar1
 SG_ Loc26_YAngle3 : 55|16@0+ (6.103608E-005,-2) [-2|1.9999995028] "rad" Vector__XXX
 SG_ Loc26_YAngle2 : 39|16@0+ (6.103608E-005,-2) [-2|1.9999995028] "rad" Vector__XXX
 SG_ Loc26_YAngle1 : 23|16@0+ (6.103608E-005,-2) [-2|1.9999995028] "rad" Vector__XXX
 SG_ Loc26_YAngle0 : 7|16@0+ (6.103608E-005,-2) [-2|1.9999995028] "rad" Vector__XXX

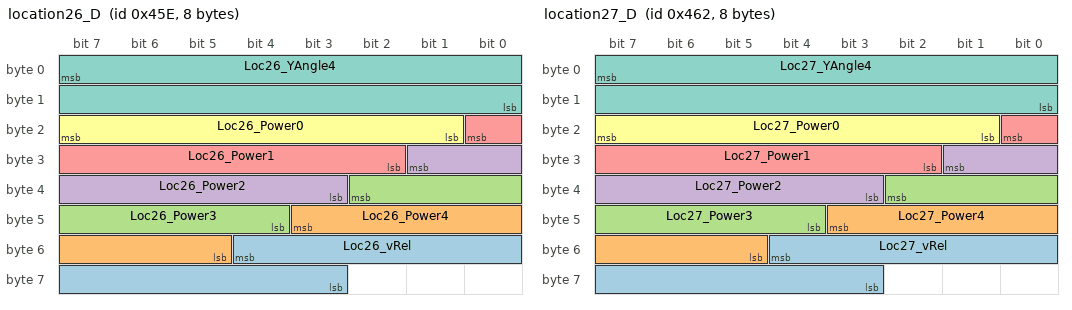
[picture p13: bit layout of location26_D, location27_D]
BO_ 1118 location26_D: 8 Bosch_Radar1
 SG_ Loc26_vRel : 52|10@0+ (0.125,-64) [-64|63.875] "m/s" Vector__XXX
 SG_ Loc26_Power4 : 43|7@0+ (1,-64) [-64|63] "dBm^2" Vector__XXX
 SG_ Loc26_Power3 : 34|7@0+ (1,-64) [-64|63] "dBm^2" Vector__XXX
 SG_ Loc26_Power2 : 25|7@0+ (1,-64) [-64|63] "dBm^2" Vector__XXX
 SG_ Loc26_Power1 : 16|7@0+ (1,-64) [-64|63] "dBm^2" Vector__XXX
 SG_ Loc26_Power0 : 23|7@0+ (1,-64) [-64|63] "dBm^2" Vector__XXX
 SG_ Loc26_YAngle4 : 7|16@0+ (6.103608E-005,-2) [-2|1.9999995028] "rad" Vector__XXX

BO_ 1119 location27_A: 8 Bosch_Radar1
 SG_ Loc27_Status : 62|1@0+ (1,0) [0|1] "" Vector__XXX
 SG_ Loc27_AngleType : 63|1@0+ (1,0) [0|1] "" Vector__XXX
 SG_ Loc27_YExistProb4 : 55|8@0+ (0.00390625,0) [0|1] "" Vector__XXX
 SG_ Loc27_YExistProb3 : 47|8@0+ (0.00390625,0) [0|1] "" Vector__XXX
 SG_ Loc27_YExistProb2 : 39|8@0+ (0.00390625,0) [0|1] "" Vector__XXX
 SG_ Loc27_YExistProb1 : 31|8@0+ (0.00390625,0) [0|1] "" Vector__XXX
 SG_ Loc27_YExistProb0 : 23|8@0+ (0.00390625,0) [0|1] "" Vector__XXX
 SG_ Loc27_RadialDist : 7|16@0+ (0.0039063,0) [0|255.9993705] "m" Vector__XXX

BO_ 1120 location27_B: 8 Bosch_Radar1
 SG_ Loc27_ZCorrelated : 53|10@0+ (0.00390625,-2) [-2|1.99609375] "rad" Vector__XXX
 SG_ Loc27_YSigmaAngle4 : 25|10@0+ (0.00012207,0) [0|0.12487761] "rad" Vector__XXX
 SG_ Loc27_YSigmaAngle3 : 47|10@0+ (0.00012207,0) [0|0.12487761] "rad" Vector__XXX
 SG_ Loc27_YSigmaAngle2 : 19|10@0+ (0.00012207,0) [0|0.12487761] "rad" Vector__XXX
 SG_ Loc27_YSigmaAngle1 : 13|10@0+ (0.00012207,0) [0|0.12487761] "rad" Vector__XXX
 SG_ Loc27_YSigmaAngle0 : 7|10@0+ (0.00012207,0) [0|0.12487761] "rad" Vector__XXX

BO_ 1121 location27_C: 8 Bosch_Radar1
 SG_ Loc27_YAngle3 : 55|16@0+ (6.103608E-005,-2) [-2|1.9999995028] "rad" Vector__XXX
 SG_ Loc27_YAngle2 : 39|16@0+ (6.103608E-005,-2) [-2|1.9999995028] "rad" Vector__XXX
 SG_ Loc27_YAngle1 : 23|16@0+ (6.103608E-005,-2) [-2|1.9999995028] "rad" Vector__XXX
 SG_ Loc27_YAngle0 : 7|16@0+ (6.103608E-005,-2) [-2|1.9999995028] "rad" Vector__XXX

BO_ 1122 location27_D: 8 Bosch_Radar1
 SG_ Loc27_vRel : 52|10@0+ (0.125,-64) [-64|63.875] "m/s" Vector__XXX
 SG_ Loc27_Power4 : 43|7@0+ (1,-64) [-64|63] "dBm^2" Vector__XXX
 SG_ Loc27_Power3 : 34|7@0+ (1,-64) [-64|63] "dBm^2" Vector__XXX
 SG_ Loc27_Power2 : 25|7@0+ (1,-64) [-64|63] "dBm^2" Vector__XXX
 SG_ Loc27_Power1 : 16|7@0+ (1,-64) [-64|63] "dBm^2" Vector__XXX
 SG_ Loc27_Power0 : 23|7@0+ (1,-64) [-64|63] "dBm^2" Vector__XXX
 SG_ Loc27_YAngle4 : 7|16@0+ (6.103608E-005,-2) [-2|1.9999995028] "rad" Vector__XXX

BO_ 1123 location28_A: 8 Bosch_Radar1
 SG_ Loc28_Status : 62|1@0+ (1,0) [0|1] "" Vector__XXX
 SG_ Loc28_AngleType : 63|1@0+ (1,0) [0|1] "" Vector__XXX
 SG_ Loc28_YExistProb4 : 55|8@0+ (0.00390625,0) [0|1] "" Vector__XXX
 SG_ Loc28_YExistProb3 : 47|8@0+ (0.00390625,0) [0|1] "" Vector__XXX
 SG_ Loc28_YExistProb2 : 39|8@0+ (0.00390625,0) [0|1] "" Vector__XXX
 SG_ Loc28_YExistProb1 : 31|8@0+ (0.00390625,0) [0|1] "" Vector__XXX
 SG_ Loc28_YExistProb0 : 23|8@0+ (0.00390625,0) [0|1] "" Vector__XXX
 SG_ Loc28_RadialDist : 7|16@0+ (0.0039063,0) [0|255.9993705] "m" Vector__XXX

BO_ 1124 location28_B: 8 Bosch_Radar1
 SG_ Loc28_ZCorrelated : 53|10@0+ (0.00390625,-2) [-2|1.99609375] "rad" Vector__XXX
 SG_ Loc28_YSigmaAngle4 : 25|10@0+ (0.00012207,0) [0|0.12487761] "rad" Vector__XXX
 SG_ Loc28_YSigmaAngle3 : 47|10@0+ (0.00012207,0) [0|0.12487761] "rad" Vector__XXX
 SG_ Loc28_YSigmaAngle2 : 19|10@0+ (0.00012207,0) [0|0.12487761] "rad" Vector__XXX
 SG_ Loc28_YSigmaAngle1 : 13|10@0+ (0.00012207,0) [0|0.12487761] "rad" Vector__XXX
 SG_ Loc28_YSigmaAngle0 : 7|10@0+ (0.00012207,0) [0|0.12487761] "rad" Vector__XXX

BO_ 1125 location28_C: 8 Bosch_Radar1
 SG_ Loc28_YAngle3 : 55|16@0+ (6.103608E-005,-2) [-2|1.9999995028] "rad" Vector__XXX
 SG_ Loc28_YAngle2 : 39|16@0+ (6.103608E-005,-2) [-2|1.9999995028] "rad" Vector__XXX
 SG_ Loc28_YAngle1 : 23|16@0+ (6.103608E-005,-2) [-2|1.9999995028] "rad" Vector__XXX
 SG_ Loc28_YAngle0 : 7|16@0+ (6.103608E-005,-2) [-2|1.9999995028] "rad" Vector__XXX

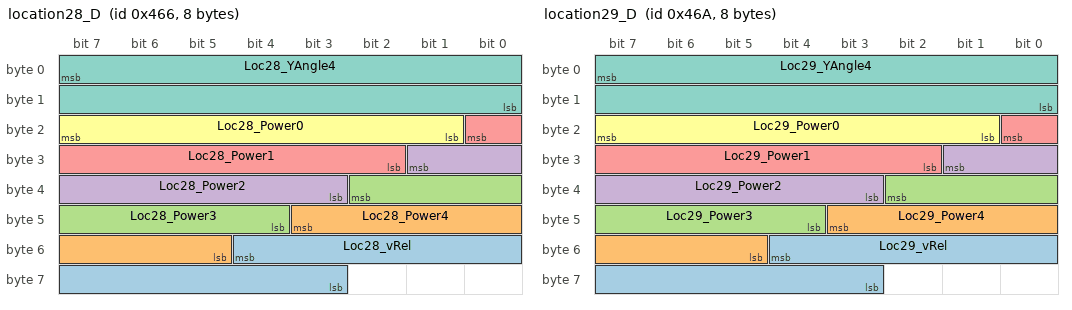
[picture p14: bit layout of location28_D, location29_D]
BO_ 1126 location28_D: 8 Bosch_Radar1
 SG_ Loc28_vRel : 52|10@0+ (0.125,-64) [-64|63.875] "m/s" Vector__XXX
 SG_ Loc28_Power4 : 43|7@0+ (1,-64) [-64|63] "dBm^2" Vector__XXX
 SG_ Loc28_Power3 : 34|7@0+ (1,-64) [-64|63] "dBm^2" Vector__XXX
 SG_ Loc28_Power2 : 25|7@0+ (1,-64) [-64|63] "dBm^2" Vector__XXX
 SG_ Loc28_Power1 : 16|7@0+ (1,-64) [-64|63] "dBm^2" Vector__XXX
 SG_ Loc28_Power0 : 23|7@0+ (1,-64) [-64|63] "dBm^2" Vector__XXX
 SG_ Loc28_YAngle4 : 7|16@0+ (6.103608E-005,-2) [-2|1.9999995028] "rad" Vector__XXX

BO_ 1127 location29_A: 8 Bosch_Radar1
 SG_ Loc29_Status : 62|1@0+ (1,0) [0|1] "" Vector__XXX
 SG_ Loc29_AngleType : 63|1@0+ (1,0) [0|1] "" Vector__XXX
 SG_ Loc29_YExistProb4 : 55|8@0+ (0.00390625,0) [0|1] "" Vector__XXX
 SG_ Loc29_YExistProb3 : 47|8@0+ (0.00390625,0) [0|1] "" Vector__XXX
 SG_ Loc29_YExistProb2 : 39|8@0+ (0.00390625,0) [0|1] "" Vector__XXX
 SG_ Loc29_YExistProb1 : 31|8@0+ (0.00390625,0) [0|1] "" Vector__XXX
 SG_ Loc29_YExistProb0 : 23|8@0+ (0.00390625,0) [0|1] "" Vector__XXX
 SG_ Loc29_RadialDist : 7|16@0+ (0.0039063,0) [0|255.9993705] "m" Vector__XXX

BO_ 1128 location29_B: 8 Bosch_Radar1
 SG_ Loc29_ZCorrelated : 53|10@0+ (0.00390625,-2) [-2|1.99609375] "rad" Vector__XXX
 SG_ Loc29_YSigmaAngle4 : 25|10@0+ (0.00012207,0) [0|0.12487761] "rad" Vector__XXX
 SG_ Loc29_YSigmaAngle3 : 47|10@0+ (0.00012207,0) [0|0.12487761] "rad" Vector__XXX
 SG_ Loc29_YSigmaAngle2 : 19|10@0+ (0.00012207,0) [0|0.12487761] "rad" Vector__XXX
 SG_ Loc29_YSigmaAngle1 : 13|10@0+ (0.00012207,0) [0|0.12487761] "rad" Vector__XXX
 SG_ Loc29_YSigmaAngle0 : 7|10@0+ (0.00012207,0) [0|0.12487761] "rad" Vector__XXX

BO_ 1129 location29_C: 8 Bosch_Radar1
 SG_ Loc29_YAngle3 : 55|16@0+ (6.103608E-005,-2) [-2|1.9999995028] "rad" Vector__XXX
 SG_ Loc29_YAngle2 : 39|16@0+ (6.103608E-005,-2) [-2|1.9999995028] "rad" Vector__XXX
 SG_ Loc29_YAngle1 : 23|16@0+ (6.103608E-005,-2) [-2|1.9999995028] "rad" Vector__XXX
 SG_ Loc29_YAngle0 : 7|16@0+ (6.103608E-005,-2) [-2|1.9999995028] "rad" Vector__XXX

BO_ 1130 location29_D: 8 Bosch_Radar1
 SG_ Loc29_vRel : 52|10@0+ (0.125,-64) [-64|63.875] "m/s" Vector__XXX
 SG_ Loc29_Power4 : 43|7@0+ (1,-64) [-64|63] "dBm^2" Vector__XXX
 SG_ Loc29_Power3 : 34|7@0+ (1,-64) [-64|63] "dBm^2" Vector__XXX
 SG_ Loc29_Power2 : 25|7@0+ (1,-64) [-64|63] "dBm^2" Vector__XXX
 SG_ Loc29_Power1 : 16|7@0+ (1,-64) [-64|63] "dBm^2" Vector__XXX
 SG_ Loc29_Power0 : 23|7@0+ (1,-64) [-64|63] "dBm^2" Vector__XXX
 SG_ Loc29_YAngle4 : 7|16@0+ (6.103608E-005,-2) [-2|1.9999995028] "rad" Vector__XXX

BO_ 1131 location30_A: 8 Bosch_Radar1
 SG_ Loc30_Status : 62|1@0+ (1,0) [0|1] "" Vector__XXX
 SG_ Loc30_AngleType : 63|1@0+ (1,0) [0|1] "" Vector__XXX
 SG_ Loc30_YExistProb4 : 55|8@0+ (0.00390625,0) [0|1] "" Vector__XXX
 SG_ Loc30_YExistProb3 : 47|8@0+ (0.00390625,0) [0|1] "" Vector__XXX
 SG_ Loc30_YExistProb2 : 39|8@0+ (0.00390625,0) [0|1] "" Vector__XXX
 SG_ Loc30_YExistProb1 : 31|8@0+ (0.00390625,0) [0|1] "" Vector__XXX
 SG_ Loc30_YExistProb0 : 23|8@0+ (0.00390625,0) [0|1] "" Vector__XXX
 SG_ Loc30_RadialDist : 7|16@0+ (0.0039063,0) [0|255.9993705] "m" Vector__XXX

BO_ 1132 location30_B: 8 Bosch_Radar1
 SG_ Loc30_ZCorrelated : 53|10@0+ (0.00390625,-2) [-2|1.99609375] "rad" Vector__XXX
 SG_ Loc30_YSigmaAngle4 : 25|10@0+ (0.00012207,0) [0|0.12487761] "rad" Vector__XXX
 SG_ Loc30_YSigmaAngle3 : 47|10@0+ (0.00012207,0) [0|0.12487761] "rad" Vector__XXX
 SG_ Loc30_YSigmaAngle2 : 19|10@0+ (0.00012207,0) [0|0.12487761] "rad" Vector__XXX
 SG_ Loc30_YSigmaAngle1 : 13|10@0+ (0.00012207,0) [0|0.12487761] "rad" Vector__XXX
 SG_ Loc30_YSigmaAngle0 : 7|10@0+ (0.00012207,0) [0|0.12487761] "rad" Vector__XXX

BO_ 1133 location30_C: 8 Bosch_Radar1
 SG_ Loc30_YAngle3 : 55|16@0+ (6.103608E-005,-2) [-2|1.9999995028] "rad" Vector__XXX
 SG_ Loc30_YAngle2 : 39|16@0+ (6.103608E-005,-2) [-2|1.9999995028] "rad" Vector__XXX
 SG_ Loc30_YAngle1 : 23|16@0+ (6.103608E-005,-2) [-2|1.9999995028] "rad" Vector__XXX
 SG_ Loc30_YAngle0 : 7|16@0+ (6.103608E-005,-2) [-2|1.9999995028] "rad" Vector__XXX

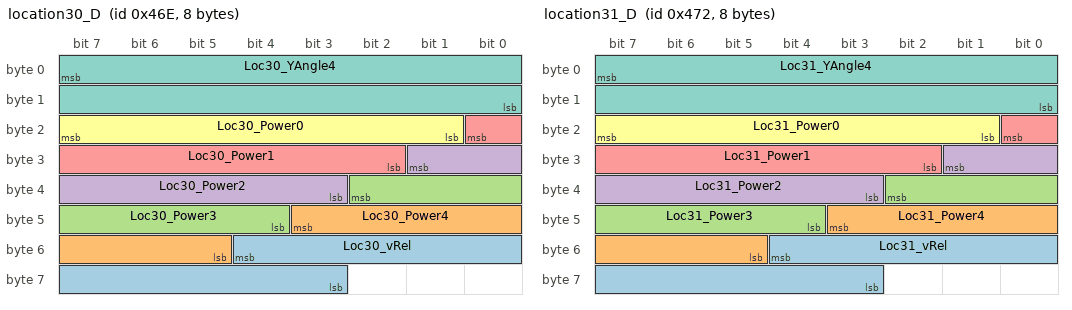
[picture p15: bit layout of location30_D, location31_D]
BO_ 1134 location30_D: 8 Bosch_Radar1
 SG_ Loc30_vRel : 52|10@0+ (0.125,-64) [-64|63.875] "m/s" Vector__XXX
 SG_ Loc30_Power4 : 43|7@0+ (1,-64) [-64|63] "dBm^2" Vector__XXX
 SG_ Loc30_Power3 : 34|7@0+ (1,-64) [-64|63] "dBm^2" Vector__XXX
 SG_ Loc30_Power2 : 25|7@0+ (1,-64) [-64|63] "dBm^2" Vector__XXX
 SG_ Loc30_Power1 : 16|7@0+ (1,-64) [-64|63] "dBm^2" Vector__XXX
 SG_ Loc30_Power0 : 23|7@0+ (1,-64) [-64|63] "dBm^2" Vector__XXX
 SG_ Loc30_YAngle4 : 7|16@0+ (6.103608E-005,-2) [-2|1.9999995028] "rad" Vector__XXX

BO_ 1135 location31_A: 8 Bosch_Radar1
 SG_ Loc31_Status : 62|1@0+ (1,0) [0|1] "" Vector__XXX
 SG_ Loc31_AngleType : 63|1@0+ (1,0) [0|1] "" Vector__XXX
 SG_ Loc31_YExistProb4 : 55|8@0+ (0.00390625,0) [0|1] "" Vector__XXX
 SG_ Loc31_YExistProb3 : 47|8@0+ (0.00390625,0) [0|1] "" Vector__XXX
 SG_ Loc31_YExistProb2 : 39|8@0+ (0.00390625,0) [0|1] "" Vector__XXX
 SG_ Loc31_YExistProb1 : 31|8@0+ (0.00390625,0) [0|1] "" Vector__XXX
 SG_ Loc31_YExistProb0 : 23|8@0+ (0.00390625,0) [0|1] "" Vector__XXX
 SG_ Loc31_RadialDist : 7|16@0+ (0.0039063,0) [0|255.9993705] "m" Vector__XXX

BO_ 1136 location31_B: 8 Bosch_Radar1
 SG_ Loc31_ZCorrelated : 53|10@0+ (0.00390625,-2) [-2|1.99609375] "rad" Vector__XXX
 SG_ Loc31_YSigmaAngle4 : 25|10@0+ (0.00012207,0) [0|0.12487761] "rad" Vector__XXX
 SG_ Loc31_YSigmaAngle3 : 47|10@0+ (0.00012207,0) [0|0.12487761] "rad" Vector__XXX
 SG_ Loc31_YSigmaAngle2 : 19|10@0+ (0.00012207,0) [0|0.12487761] "rad" Vector__XXX
 SG_ Loc31_YSigmaAngle1 : 13|10@0+ (0.00012207,0) [0|0.12487761] "rad" Vector__XXX
 SG_ Loc31_YSigmaAngle0 : 7|10@0+ (0.00012207,0) [0|0.12487761] "rad" Vector__XXX

BO_ 1137 location31_C: 8 Bosch_Radar1
 SG_ Loc31_YAngle3 : 55|16@0+ (6.103608E-005,-2) [-2|1.9999995028] "rad" Vector__XXX
 SG_ Loc31_YAngle2 : 39|16@0+ (6.103608E-005,-2) [-2|1.9999995028] "rad" Vector__XXX
 SG_ Loc31_YAngle1 : 23|16@0+ (6.103608E-005,-2) [-2|1.9999995028] "rad" Vector__XXX
 SG_ Loc31_YAngle0 : 7|16@0+ (6.103608E-005,-2) [-2|1.9999995028] "rad" Vector__XXX

BO_ 1138 location31_D: 8 Bosch_Radar1
 SG_ Loc31_vRel : 52|10@0+ (0.125,-64) [-64|63.875] "m/s" Vector__XXX
 SG_ Loc31_Power4 : 43|7@0+ (1,-64) [-64|63] "dBm^2" Vector__XXX
 SG_ Loc31_Power3 : 34|7@0+ (1,-64) [-64|63] "dBm^2" Vector__XXX
 SG_ Loc31_Power2 : 25|7@0+ (1,-64) [-64|63] "dBm^2" Vector__XXX
 SG_ Loc31_Power1 : 16|7@0+ (1,-64) [-64|63] "dBm^2" Vector__XXX
 SG_ Loc31_Power0 : 23|7@0+ (1,-64) [-64|63] "dBm^2" Vector__XXX
 SG_ Loc31_YAngle4 : 7|16@0+ (6.103608E-005,-2) [-2|1.9999995028] "rad" Vector__XXX

BO_ 1139 location32_A: 8 Bosch_Radar1
 SG_ Loc32_Status : 62|1@0+ (1,0) [0|1] "" Vector__XXX
 SG_ Loc32_AngleType : 63|1@0+ (1,0) [0|1] "" Vector__XXX
 SG_ Loc32_YExistProb4 : 55|8@0+ (0.00390625,0) [0|1] "" Vector__XXX
 SG_ Loc32_YExistProb3 : 47|8@0+ (0.00390625,0) [0|1] "" Vector__XXX
 SG_ Loc32_YExistProb2 : 39|8@0+ (0.00390625,0) [0|1] "" Vector__XXX
 SG_ Loc32_YExistProb1 : 31|8@0+ (0.00390625,0) [0|1] "" Vector__XXX
 SG_ Loc32_YExistProb0 : 23|8@0+ (0.00390625,0) [0|1] "" Vector__XXX
 SG_ Loc32_RadialDist : 7|16@0+ (0.0039063,0) [0|255.9993705] "m" Vector__XXX

BO_ 1140 location32_B: 8 Bosch_Radar1
 SG_ Loc32_ZCorrelated : 53|10@0+ (0.00390625,-2) [-2|1.99609375] "rad" Vector__XXX
 SG_ Loc32_YSigmaAngle4 : 25|10@0+ (0.00012207,0) [0|0.12487761] "rad" Vector__XXX
 SG_ Loc32_YSigmaAngle3 : 47|10@0+ (0.00012207,0) [0|0.12487761] "rad" Vector__XXX
 SG_ Loc32_YSigmaAngle2 : 19|10@0+ (0.00012207,0) [0|0.12487761] "rad" Vector__XXX
 SG_ Loc32_YSigmaAngle1 : 13|10@0+ (0.00012207,0) [0|0.12487761] "rad" Vector__XXX
 SG_ Loc32_YSigmaAngle0 : 7|10@0+ (0.00012207,0) [0|0.12487761] "rad" Vector__XXX

BO_ 1141 location32_C: 8 Bosch_Radar1
 SG_ Loc32_YAngle3 : 55|16@0+ (6.103608E-005,-2) [-2|1.9999995028] "rad" Vector__XXX
 SG_ Loc32_YAngle2 : 39|16@0+ (6.103608E-005,-2) [-2|1.9999995028] "rad" Vector__XXX
 SG_ Loc32_YAngle1 : 23|16@0+ (6.103608E-005,-2) [-2|1.9999995028] "rad" Vector__XXX
 SG_ Loc32_YAngle0 : 7|16@0+ (6.103608E-005,-2) [-2|1.9999995028] "rad" Vector__XXX

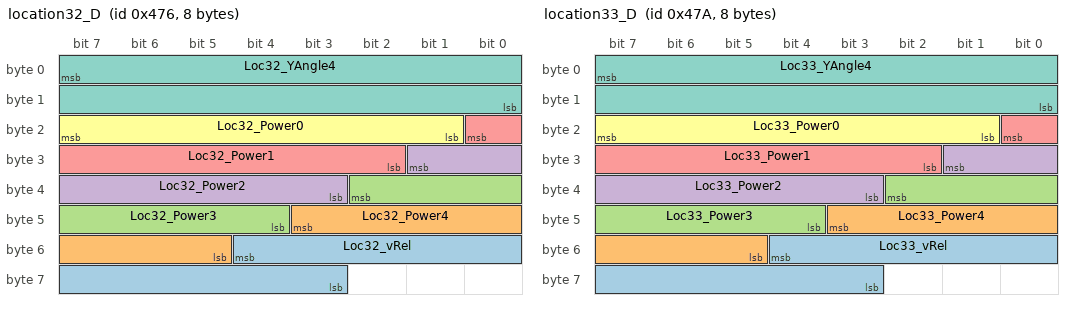
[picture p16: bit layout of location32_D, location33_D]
BO_ 1142 location32_D: 8 Bosch_Radar1
 SG_ Loc32_vRel : 52|10@0+ (0.125,-64) [-64|63.875] "m/s" Vector__XXX
 SG_ Loc32_Power4 : 43|7@0+ (1,-64) [-64|63] "dBm^2" Vector__XXX
 SG_ Loc32_Power3 : 34|7@0+ (1,-64) [-64|63] "dBm^2" Vector__XXX
 SG_ Loc32_Power2 : 25|7@0+ (1,-64) [-64|63] "dBm^2" Vector__XXX
 SG_ Loc32_Power1 : 16|7@0+ (1,-64) [-64|63] "dBm^2" Vector__XXX
 SG_ Loc32_Power0 : 23|7@0+ (1,-64) [-64|63] "dBm^2" Vector__XXX
 SG_ Loc32_YAngle4 : 7|16@0+ (6.103608E-005,-2) [-2|1.9999995028] "rad" Vector__XXX

BO_ 1143 location33_A: 8 Bosch_Radar1
 SG_ Loc33_Status : 62|1@0+ (1,0) [0|1] "" Vector__XXX
 SG_ Loc33_AngleType : 63|1@0+ (1,0) [0|1] "" Vector__XXX
 SG_ Loc33_YExistProb4 : 55|8@0+ (0.00390625,0) [0|1] "" Vector__XXX
 SG_ Loc33_YExistProb3 : 47|8@0+ (0.00390625,0) [0|1] "" Vector__XXX
 SG_ Loc33_YExistProb2 : 39|8@0+ (0.00390625,0) [0|1] "" Vector__XXX
 SG_ Loc33_YExistProb1 : 31|8@0+ (0.00390625,0) [0|1] "" Vector__XXX
 SG_ Loc33_YExistProb0 : 23|8@0+ (0.00390625,0) [0|1] "" Vector__XXX
 SG_ Loc33_RadialDist : 7|16@0+ (0.0039063,0) [0|255.9993705] "m" Vector__XXX

BO_ 1144 location33_B: 8 Bosch_Radar1
 SG_ Loc33_ZCorrelated : 53|10@0+ (0.00390625,-2) [-2|1.99609375] "rad" Vector__XXX
 SG_ Loc33_YSigmaAngle4 : 25|10@0+ (0.00012207,0) [0|0.12487761] "rad" Vector__XXX
 SG_ Loc33_YSigmaAngle3 : 47|10@0+ (0.00012207,0) [0|0.12487761] "rad" Vector__XXX
 SG_ Loc33_YSigmaAngle2 : 19|10@0+ (0.00012207,0) [0|0.12487761] "rad" Vector__XXX
 SG_ Loc33_YSigmaAngle1 : 13|10@0+ (0.00012207,0) [0|0.12487761] "rad" Vector__XXX
 SG_ Loc33_YSigmaAngle0 : 7|10@0+ (0.00012207,0) [0|0.12487761] "rad" Vector__XXX

BO_ 1145 location33_C: 8 Bosch_Radar1
 SG_ Loc33_YAngle3 : 55|16@0+ (6.103608E-005,-2) [-2|1.9999995028] "rad" Vector__XXX
 SG_ Loc33_YAngle2 : 39|16@0+ (6.103608E-005,-2) [-2|1.9999995028] "rad" Vector__XXX
 SG_ Loc33_YAngle1 : 23|16@0+ (6.103608E-005,-2) [-2|1.9999995028] "rad" Vector__XXX
 SG_ Loc33_YAngle0 : 7|16@0+ (6.103608E-005,-2) [-2|1.9999995028] "rad" Vector__XXX

BO_ 1146 location33_D: 8 Bosch_Radar1
 SG_ Loc33_vRel : 52|10@0+ (0.125,-64) [-64|63.875] "m/s" Vector__XXX
 SG_ Loc33_Power4 : 43|7@0+ (1,-64) [-64|63] "dBm^2" Vector__XXX
 SG_ Loc33_Power3 : 34|7@0+ (1,-64) [-64|63] "dBm^2" Vector__XXX
 SG_ Loc33_Power2 : 25|7@0+ (1,-64) [-64|63] "dBm^2" Vector__XXX
 SG_ Loc33_Power1 : 16|7@0+ (1,-64) [-64|63] "dBm^2" Vector__XXX
 SG_ Loc33_Power0 : 23|7@0+ (1,-64) [-64|63] "dBm^2" Vector__XXX
 SG_ Loc33_YAngle4 : 7|16@0+ (6.103608E-005,-2) [-2|1.9999995028] "rad" Vector__XXX

BO_ 1147 location34_A: 8 Bosch_Radar1
 SG_ Loc34_Status : 62|1@0+ (1,0) [0|1] "" Vector__XXX
 SG_ Loc34_AngleType : 63|1@0+ (1,0) [0|1] "" Vector__XXX
 SG_ Loc34_YExistProb4 : 55|8@0+ (0.00390625,0) [0|1] "" Vector__XXX
 SG_ Loc34_YExistProb3 : 47|8@0+ (0.00390625,0) [0|1] "" Vector__XXX
 SG_ Loc34_YExistProb2 : 39|8@0+ (0.00390625,0) [0|1] "" Vector__XXX
 SG_ Loc34_YExistProb1 : 31|8@0+ (0.00390625,0) [0|1] "" Vector__XXX
 SG_ Loc34_YExistProb0 : 23|8@0+ (0.00390625,0) [0|1] "" Vector__XXX
 SG_ Loc34_RadialDist : 7|16@0+ (0.0039063,0) [0|255.9993705] "m" Vector__XXX

BO_ 1148 location34_B: 8 Bosch_Radar1
 SG_ Loc34_ZCorrelated : 53|10@0+ (0.00390625,-2) [-2|1.99609375] "rad" Vector__XXX
 SG_ Loc34_YSigmaAngle4 : 25|10@0+ (0.00012207,0) [0|0.12487761] "rad" Vector__XXX
 SG_ Loc34_YSigmaAngle3 : 47|10@0+ (0.00012207,0) [0|0.12487761] "rad" Vector__XXX
 SG_ Loc34_YSigmaAngle2 : 19|10@0+ (0.00012207,0) [0|0.12487761] "rad" Vector__XXX
 SG_ Loc34_YSigmaAngle1 : 13|10@0+ (0.00012207,0) [0|0.12487761] "rad" Vector__XXX
 SG_ Loc34_YSigmaAngle0 : 7|10@0+ (0.00012207,0) [0|0.12487761] "rad" Vector__XXX

BO_ 1149 location34_C: 8 Bosch_Radar1
 SG_ Loc34_YAngle3 : 55|16@0+ (6.103608E-005,-2) [-2|1.9999995028] "rad" Vector__XXX
 SG_ Loc34_YAngle2 : 39|16@0+ (6.103608E-005,-2) [-2|1.9999995028] "rad" Vector__XXX
 SG_ Loc34_YAngle1 : 23|16@0+ (6.103608E-005,-2) [-2|1.9999995028] "rad" Vector__XXX
 SG_ Loc34_YAngle0 : 7|16@0+ (6.103608E-005,-2) [-2|1.9999995028] "rad" Vector__XXX

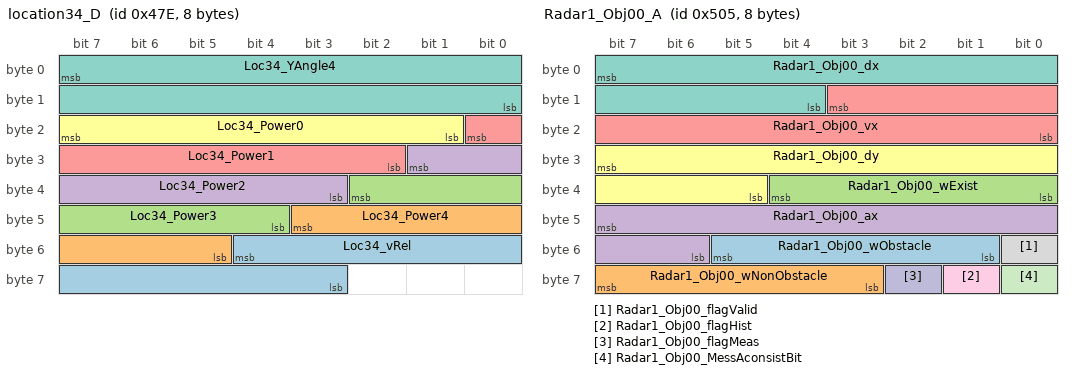
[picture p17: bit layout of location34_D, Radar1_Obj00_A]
BO_ 1150 location34_D: 8 Bosch_Radar1
 SG_ Loc34_vRel : 52|10@0+ (0.125,-64) [-64|63.875] "m/s" Vector__XXX
 SG_ Loc34_Power4 : 43|7@0+ (1,-64) [-64|63] "dBm^2" Vector__XXX
 SG_ Loc34_Power3 : 34|7@0+ (1,-64) [-64|63] "dBm^2" Vector__XXX
 SG_ Loc34_Power2 : 25|7@0+ (1,-64) [-64|63] "dBm^2" Vector__XXX
 SG_ Loc34_Power1 : 16|7@0+ (1,-64) [-64|63] "dBm^2" Vector__XXX
 SG_ Loc34_Power0 : 23|7@0+ (1,-64) [-64|63] "dBm^2" Vector__XXX
 SG_ Loc34_YAngle4 : 7|16@0+ (6.103608E-005,-2) [-2|1.9999995028] "rad" Vector__XXX

BO_ 1151 location35_A: 8 Bosch_Radar1
 SG_ Loc35_Status : 62|1@0+ (1,0) [0|1] "" Vector__XXX
 SG_ Loc35_AngleType : 63|1@0+ (1,0) [0|1] "" Vector__XXX
 SG_ Loc35_YExistProb4 : 55|8@0+ (0.00390625,0) [0|1] "" Vector__XXX
 SG_ Loc35_YExistProb3 : 47|8@0+ (0.00390625,0) [0|1] "" Vector__XXX
 SG_ Loc35_YExistProb2 : 39|8@0+ (0.00390625,0) [0|1] "" Vector__XXX
 SG_ Loc35_YExistProb1 : 31|8@0+ (0.00390625,0) [0|1] "" Vector__XXX
 SG_ Loc35_YExistProb0 : 23|8@0+ (0.00390625,0) [0|1] "" Vector__XXX
 SG_ Loc35_RadialDist : 7|16@0+ (0.0039063,0) [0|255.9993705] "m" Vector__XXX

BO_ 1152 location35_B: 8 Bosch_Radar1
 SG_ Loc35_ZCorrelated : 53|10@0+ (0.00390625,-2) [-2|1.99609375] "rad" Vector__XXX
 SG_ Loc35_YSigmaAngle4 : 25|10@0+ (0.00012207,0) [0|0.12487761] "rad" Vector__XXX
 SG_ Loc35_YSigmaAngle3 : 47|10@0+ (0.00012207,0) [0|0.12487761] "rad" Vector__XXX
 SG_ Loc35_YSigmaAngle2 : 19|10@0+ (0.00012207,0) [0|0.12487761] "rad" Vector__XXX
 SG_ Loc35_YSigmaAngle1 : 13|10@0+ (0.00012207,0) [0|0.12487761] "rad" Vector__XXX
 SG_ Loc35_YSigmaAngle0 : 7|10@0+ (0.00012207,0) [0|0.12487761] "rad" Vector__XXX

BO_ 1153 location35_C: 8 Bosch_Radar1
 SG_ Loc35_YAngle3 : 55|16@0+ (6.103608E-005,-2) [-2|1.9999995028] "rad" Vector__XXX
 SG_ Loc35_YAngle2 : 39|16@0+ (6.103608E-005,-2) [-2|1.9999995028] "rad" Vector__XXX
 SG_ Loc35_YAngle1 : 23|16@0+ (6.103608E-005,-2) [-2|1.9999995028] "rad" Vector__XXX
 SG_ Loc35_YAngle0 : 7|16@0+ (6.103608E-005,-2) [-2|1.9999995028] "rad" Vector__XXX

BO_ 1154 location35_D: 8 Bosch_Radar1
 SG_ Loc35_vRel : 52|10@0+ (0.125,-64) [-64|63.875] "m/s" Vector__XXX
 SG_ Loc35_Power4 : 43|7@0+ (1,-64) [-64|63] "dBm^2" Vector__XXX
 SG_ Loc35_Power3 : 34|7@0+ (1,-64) [-64|63] "dBm^2" Vector__XXX
 SG_ Loc35_Power2 : 25|7@0+ (1,-64) [-64|63] "dBm^2" Vector__XXX
 SG_ Loc35_Power1 : 16|7@0+ (1,-64) [-64|63] "dBm^2" Vector__XXX
 SG_ Loc35_Power0 : 23|7@0+ (1,-64) [-64|63] "dBm^2" Vector__XXX
 SG_ Loc35_YAngle4 : 7|16@0+ (6.103608E-005,-2) [-2|1.9999995028] "rad" Vector__XXX

BO_ 1155 location36_A: 8 Bosch_Radar1
 SG_ Loc36_Status : 62|1@0+ (1,0) [0|1] "" Vector__XXX
 SG_ Loc36_AngleType : 63|1@0+ (1,0) [0|1] "" Vector__XXX
 SG_ Loc36_YExistProb4 : 55|8@0+ (0.00390625,0) [0|1] "" Vector__XXX
 SG_ Loc36_YExistProb3 : 47|8@0+ (0.00390625,0) [0|1] "" Vector__XXX
 SG_ Loc36_YExistProb2 : 39|8@0+ (0.00390625,0) [0|1] "" Vector__XXX
 SG_ Loc36_YExistProb1 : 31|8@0+ (0.00390625,0) [0|1] "" Vector__XXX
 SG_ Loc36_YExistProb0 : 23|8@0+ (0.00390625,0) [0|1] "" Vector__XXX
 SG_ Loc36_RadialDist : 7|16@0+ (0.0039063,0) [0|255.9993705] "m" Vector__XXX

BO_ 1156 location36_B: 8 Bosch_Radar1
 SG_ Loc36_ZCorrelated : 53|10@0+ (0.00390625,-2) [-2|1.99609375] "rad" Vector__XXX
 SG_ Loc36_YSigmaAngle4 : 25|10@0+ (0.00012207,0) [0|0.12487761] "rad" Vector__XXX
 SG_ Loc36_YSigmaAngle3 : 47|10@0+ (0.00012207,0) [0|0.12487761] "rad" Vector__XXX
 SG_ Loc36_YSigmaAngle2 : 19|10@0+ (0.00012207,0) [0|0.12487761] "rad" Vector__XXX
 SG_ Loc36_YSigmaAngle1 : 13|10@0+ (0.00012207,0) [0|0.12487761] "rad" Vector__XXX
 SG_ Loc36_YSigmaAngle0 : 7|10@0+ (0.00012207,0) [0|0.12487761] "rad" Vector__XXX

BO_ 1157 location36_C: 8 Bosch_Radar1
 SG_ Loc36_YAngle3 : 55|16@0+ (6.103608E-005,-2) [-2|1.9999995028] "rad" Vector__XXX
 SG_ Loc36_YAngle2 : 39|16@0+ (6.103608E-005,-2) [-2|1.9999995028] "rad" Vector__XXX
 SG_ Loc36_YAngle1 : 23|16@0+ (6.103608E-005,-2) [-2|1.9999995028] "rad" Vector__XXX
 SG_ Loc36_YAngle0 : 7|16@0+ (6.103608E-005,-2) [-2|1.9999995028] "rad" Vector__XXX

BO_ 1158 location36_D: 8 Bosch_Radar1
 SG_ Loc36_vRel : 52|10@0+ (0.125,-64) [-64|63.875] "m/s" Vector__XXX
 SG_ Loc36_Power4 : 43|7@0+ (1,-64) [-64|63] "dBm^2" Vector__XXX
 SG_ Loc36_Power3 : 34|7@0+ (1,-64) [-64|63] "dBm^2" Vector__XXX
 SG_ Loc36_Power2 : 25|7@0+ (1,-64) [-64|63] "dBm^2" Vector__XXX
 SG_ Loc36_Power1 : 16|7@0+ (1,-64) [-64|63] "dBm^2" Vector__XXX
 SG_ Loc36_Power0 : 23|7@0+ (1,-64) [-64|63] "dBm^2" Vector__XXX
 SG_ Loc36_YAngle4 : 7|16@0+ (6.103608E-005,-2) [-2|1.9999995028] "rad" Vector__XXX

BO_ 1159 location37_A: 8 Bosch_Radar1
 SG_ Loc37_Status : 62|1@0+ (1,0) [0|1] "" Vector__XXX
 SG_ Loc37_AngleType : 63|1@0+ (1,0) [0|1] "" Vector__XXX
 SG_ Loc37_YExistProb4 : 55|8@0+ (0.00390625,0) [0|1] "" Vector__XXX
 SG_ Loc37_YExistProb3 : 47|8@0+ (0.00390625,0) [0|1] "" Vector__XXX
 SG_ Loc37_YExistProb2 : 39|8@0+ (0.00390625,0) [0|1] "" Vector__XXX
 SG_ Loc37_YExistProb1 : 31|8@0+ (0.00390625,0) [0|1] "" Vector__XXX
 SG_ Loc37_YExistProb0 : 23|8@0+ (0.00390625,0) [0|1] "" Vector__XXX
 SG_ Loc37_RadialDist : 7|16@0+ (0.0039063,0) [0|255.9993705] "m" Vector__XXX

BO_ 1160 location37_B: 8 Bosch_Radar1
 SG_ Loc37_ZCorrelated : 53|10@0+ (0.00390625,-2) [-2|1.99609375] "rad" Vector__XXX
 SG_ Loc37_YSigmaAngle4 : 25|10@0+ (0.00012207,0) [0|0.12487761] "rad" Vector__XXX
 SG_ Loc37_YSigmaAngle3 : 47|10@0+ (0.00012207,0) [0|0.12487761] "rad" Vector__XXX
 SG_ Loc37_YSigmaAngle2 : 19|10@0+ (0.00012207,0) [0|0.12487761] "rad" Vector__XXX
 SG_ Loc37_YSigmaAngle1 : 13|10@0+ (0.00012207,0) [0|0.12487761] "rad" Vector__XXX
 SG_ Loc37_YSigmaAngle0 : 7|10@0+ (0.00012207,0) [0|0.12487761] "rad" Vector__XXX

BO_ 1161 location37_C: 8 Bosch_Radar1
 SG_ Loc37_YAngle3 : 55|16@0+ (6.103608E-005,-2) [-2|1.9999995028] "rad" Vector__XXX
 SG_ Loc37_YAngle2 : 39|16@0+ (6.103608E-005,-2) [-2|1.9999995028] "rad" Vector__XXX
 SG_ Loc37_YAngle1 : 23|16@0+ (6.103608E-005,-2) [-2|1.9999995028] "rad" Vector__XXX
 SG_ Loc37_YAngle0 : 7|16@0+ (6.103608E-005,-2) [-2|1.9999995028] "rad" Vector__XXX

BO_ 1162 location37_D: 8 Bosch_Radar1
 SG_ Loc37_vRel : 52|10@0+ (0.125,-64) [-64|63.875] "m/s" Vector__XXX
 SG_ Loc37_Power4 : 43|7@0+ (1,-64) [-64|63] "dBm^2" Vector__XXX
 SG_ Loc37_Power3 : 34|7@0+ (1,-64) [-64|63] "dBm^2" Vector__XXX
 SG_ Loc37_Power2 : 25|7@0+ (1,-64) [-64|63] "dBm^2" Vector__XXX
 SG_ Loc37_Power1 : 16|7@0+ (1,-64) [-64|63] "dBm^2" Vector__XXX
 SG_ Loc37_Power0 : 23|7@0+ (1,-64) [-64|63] "dBm^2" Vector__XXX
 SG_ Loc37_YAngle4 : 7|16@0+ (6.103608E-005,-2) [-2|1.9999995028] "rad" Vector__XXX

BO_ 1163 location38_A: 8 Bosch_Radar1
 SG_ Loc38_Status : 62|1@0+ (1,0) [0|1] "" Vector__XXX
 SG_ Loc38_AngleType : 63|1@0+ (1,0) [0|1] "" Vector__XXX
 SG_ Loc38_YExistProb4 : 55|8@0+ (0.00390625,0) [0|1] "" Vector__XXX
 SG_ Loc38_YExistProb3 : 47|8@0+ (0.00390625,0) [0|1] "" Vector__XXX
 SG_ Loc38_YExistProb2 : 39|8@0+ (0.00390625,0) [0|1] "" Vector__XXX
 SG_ Loc38_YExistProb1 : 31|8@0+ (0.00390625,0) [0|1] "" Vector__XXX
 SG_ Loc38_YExistProb0 : 23|8@0+ (0.00390625,0) [0|1] "" Vector__XXX
 SG_ Loc38_RadialDist : 7|16@0+ (0.0039063,0) [0|255.9993705] "m" Vector__XXX

BO_ 1164 location38_B: 8 Bosch_Radar1
 SG_ Loc38_ZCorrelated : 53|10@0+ (0.00390625,-2) [-2|1.99609375] "rad" Vector__XXX
 SG_ Loc38_YSigmaAngle4 : 25|10@0+ (0.00012207,0) [0|0.12487761] "rad" Vector__XXX
 SG_ Loc38_YSigmaAngle3 : 47|10@0+ (0.00012207,0) [0|0.12487761] "rad" Vector__XXX
 SG_ Loc38_YSigmaAngle2 : 19|10@0+ (0.00012207,0) [0|0.12487761] "rad" Vector__XXX
 SG_ Loc38_YSigmaAngle1 : 13|10@0+ (0.00012207,0) [0|0.12487761] "rad" Vector__XXX
 SG_ Loc38_YSigmaAngle0 : 7|10@0+ (0.00012207,0) [0|0.12487761] "rad" Vector__XXX

BO_ 1165 location38_C: 8 Bosch_Radar1
 SG_ Loc38_YAngle3 : 55|16@0+ (6.103608E-005,-2) [-2|1.9999995028] "rad" Vector__XXX
 SG_ Loc38_YAngle2 : 39|16@0+ (6.103608E-005,-2) [-2|1.9999995028] "rad" Vector__XXX
 SG_ Loc38_YAngle1 : 23|16@0+ (6.103608E-005,-2) [-2|1.9999995028] "rad" Vector__XXX
 SG_ Loc38_YAngle0 : 7|16@0+ (6.103608E-005,-2) [-2|1.9999995028] "rad" Vector__XXX

BO_ 1166 location38_D: 8 Bosch_Radar1
 SG_ Loc38_vRel : 52|10@0+ (0.125,-64) [-64|63.875] "m/s" Vector__XXX
 SG_ Loc38_Power4 : 43|7@0+ (1,-64) [-64|63] "dBm^2" Vector__XXX
 SG_ Loc38_Power3 : 34|7@0+ (1,-64) [-64|63] "dBm^2" Vector__XXX
 SG_ Loc38_Power2 : 25|7@0+ (1,-64) [-64|63] "dBm^2" Vector__XXX
 SG_ Loc38_Power1 : 16|7@0+ (1,-64) [-64|63] "dBm^2" Vector__XXX
 SG_ Loc38_Power0 : 23|7@0+ (1,-64) [-64|63] "dBm^2" Vector__XXX
 SG_ Loc38_YAngle4 : 7|16@0+ (6.103608E-005,-2) [-2|1.9999995028] "rad" Vector__XXX

BO_ 1167 location39_A: 8 Bosch_Radar1
 SG_ Loc39_Status : 62|1@0+ (1,0) [0|1] "" Vector__XXX
 SG_ Loc39_AngleType : 63|1@0+ (1,0) [0|1] "" Vector__XXX
 SG_ Loc39_YExistProb4 : 55|8@0+ (0.00390625,0) [0|1] "" Vector__XXX
 SG_ Loc39_YExistProb3 : 47|8@0+ (0.00390625,0) [0|1] "" Vector__XXX
 SG_ Loc39_YExistProb2 : 39|8@0+ (0.00390625,0) [0|1] "" Vector__XXX
 SG_ Loc39_YExistProb1 : 31|8@0+ (0.00390625,0) [0|1] "" Vector__XXX
 SG_ Loc39_YExistProb0 : 23|8@0+ (0.00390625,0) [0|1] "" Vector__XXX
 SG_ Loc39_RadialDist : 7|16@0+ (0.0039063,0) [0|255.9993705] "m" Vector__XXX

BO_ 1168 location39_B: 8 Bosch_Radar1
 SG_ Loc39_ZCorrelated : 53|10@0+ (0.00390625,-2) [-2|1.99609375] "rad" Vector__XXX
 SG_ Loc39_YSigmaAngle4 : 25|10@0+ (0.00012207,0) [0|0.12487761] "rad" Vector__XXX
 SG_ Loc39_YSigmaAngle3 : 47|10@0+ (0.00012207,0) [0|0.12487761] "rad" Vector__XXX
 SG_ Loc39_YSigmaAngle2 : 19|10@0+ (0.00012207,0) [0|0.12487761] "rad" Vector__XXX
 SG_ Loc39_YSigmaAngle1 : 13|10@0+ (0.00012207,0) [0|0.12487761] "rad" Vector__XXX
 SG_ Loc39_YSigmaAngle0 : 7|10@0+ (0.00012207,0) [0|0.12487761] "rad" Vector__XXX

BO_ 1169 location39_C: 8 Bosch_Radar1
 SG_ Loc39_YAngle3 : 55|16@0+ (6.103608E-005,-2) [-2|1.9999995028] "rad" Vector__XXX
 SG_ Loc39_YAngle2 : 39|16@0+ (6.103608E-005,-2) [-2|1.9999995028] "rad" Vector__XXX
 SG_ Loc39_YAngle1 : 23|16@0+ (6.103608E-005,-2) [-2|1.9999995028] "rad" Vector__XXX
 SG_ Loc39_YAngle0 : 7|16@0+ (6.103608E-005,-2) [-2|1.9999995028] "rad" Vector__XXX

BO_ 1170 location39_D: 8 Bosch_Radar1
 SG_ Loc39_vRel : 52|10@0+ (0.125,-64) [-64|63.875] "m/s" Vector__XXX
 SG_ Loc39_Power4 : 43|7@0+ (1,-64) [-64|63] "dBm^2" Vector__XXX
 SG_ Loc39_Power3 : 34|7@0+ (1,-64) [-64|63] "dBm^2" Vector__XXX
 SG_ Loc39_Power2 : 25|7@0+ (1,-64) [-64|63] "dBm^2" Vector__XXX
 SG_ Loc39_Power1 : 16|7@0+ (1,-64) [-64|63] "dBm^2" Vector__XXX
 SG_ Loc39_Power0 : 23|7@0+ (1,-64) [-64|63] "dBm^2" Vector__XXX
 SG_ Loc39_YAngle4 : 7|16@0+ (6.103608E-005,-2) [-2|1.9999995028] "rad" Vector__XXX

BO_ 1171 location40_A: 8 Bosch_Radar1
 SG_ Loc40_Status : 62|1@0+ (1,0) [0|1] "" Vector__XXX
 SG_ Loc40_AngleType : 63|1@0+ (1,0) [0|1] "" Vector__XXX
 SG_ Loc40_YExistProb4 : 55|8@0+ (0.00390625,0) [0|1] "" Vector__XXX
 SG_ Loc40_YExistProb3 : 47|8@0+ (0.00390625,0) [0|1] "" Vector__XXX
 SG_ Loc40_YExistProb2 : 39|8@0+ (0.00390625,0) [0|1] "" Vector__XXX
 SG_ Loc40_YExistProb1 : 31|8@0+ (0.00390625,0) [0|1] "" Vector__XXX
 SG_ Loc40_YExistProb0 : 23|8@0+ (0.00390625,0) [0|1] "" Vector__XXX
 SG_ Loc40_RadialDist : 7|16@0+ (0.0039063,0) [0|255.9993705] "m" Vector__XXX

BO_ 1172 location40_B: 8 Bosch_Radar1
 SG_ Loc40_ZCorrelated : 53|10@0+ (0.00390625,-2) [-2|1.99609375] "rad" Vector__XXX
 SG_ Loc40_YSigmaAngle4 : 25|10@0+ (0.00012207,0) [0|0.12487761] "rad" Vector__XXX
 SG_ Loc40_YSigmaAngle3 : 47|10@0+ (0.00012207,0) [0|0.12487761] "rad" Vector__XXX
 SG_ Loc40_YSigmaAngle2 : 19|10@0+ (0.00012207,0) [0|0.12487761] "rad" Vector__XXX
 SG_ Loc40_YSigmaAngle1 : 13|10@0+ (0.00012207,0) [0|0.12487761] "rad" Vector__XXX
 SG_ Loc40_YSigmaAngle0 : 7|10@0+ (0.00012207,0) [0|0.12487761] "rad" Vector__XXX

BO_ 1173 location40_C: 8 Bosch_Radar1
 SG_ Loc40_YAngle3 : 55|16@0+ (6.103608E-005,-2) [-2|1.9999995028] "rad" Vector__XXX
 SG_ Loc40_YAngle2 : 39|16@0+ (6.103608E-005,-2) [-2|1.9999995028] "rad" Vector__XXX
 SG_ Loc40_YAngle1 : 23|16@0+ (6.103608E-005,-2) [-2|1.9999995028] "rad" Vector__XXX
 SG_ Loc40_YAngle0 : 7|16@0+ (6.103608E-005,-2) [-2|1.9999995028] "rad" Vector__XXX

BO_ 1174 location40_D: 8 Bosch_Radar1
 SG_ Loc40_vRel : 52|10@0+ (0.125,-64) [-64|63.875] "m/s" Vector__XXX
 SG_ Loc40_Power4 : 43|7@0+ (1,-64) [-64|63] "dBm^2" Vector__XXX
 SG_ Loc40_Power3 : 34|7@0+ (1,-64) [-64|63] "dBm^2" Vector__XXX
 SG_ Loc40_Power2 : 25|7@0+ (1,-64) [-64|63] "dBm^2" Vector__XXX
 SG_ Loc40_Power1 : 16|7@0+ (1,-64) [-64|63] "dBm^2" Vector__XXX
 SG_ Loc40_Power0 : 23|7@0+ (1,-64) [-64|63] "dBm^2" Vector__XXX
 SG_ Loc40_YAngle4 : 7|16@0+ (6.103608E-005,-2) [-2|1.9999995028] "rad" Vector__XXX

BO_ 1175 location41_A: 8 Bosch_Radar1
 SG_ Loc41_Status : 62|1@0+ (1,0) [0|1] "" Vector__XXX
 SG_ Loc41_AngleType : 63|1@0+ (1,0) [0|1] "" Vector__XXX
 SG_ Loc41_YExistProb4 : 55|8@0+ (0.00390625,0) [0|1] "" Vector__XXX
 SG_ Loc41_YExistProb3 : 47|8@0+ (0.00390625,0) [0|1] "" Vector__XXX
 SG_ Loc41_YExistProb2 : 39|8@0+ (0.00390625,0) [0|1] "" Vector__XXX
 SG_ Loc41_YExistProb1 : 31|8@0+ (0.00390625,0) [0|1] "" Vector__XXX
 SG_ Loc41_YExistProb0 : 23|8@0+ (0.00390625,0) [0|1] "" Vector__XXX
 SG_ Loc41_RadialDist : 7|16@0+ (0.0039063,0) [0|255.9993705] "m" Vector__XXX

BO_ 1176 location41_B: 8 Bosch_Radar1
 SG_ Loc41_ZCorrelated : 53|10@0+ (0.00390625,-2) [-2|1.99609375] "rad" Vector__XXX
 SG_ Loc41_YSigmaAngle4 : 25|10@0+ (0.00012207,0) [0|0.12487761] "rad" Vector__XXX
 SG_ Loc41_YSigmaAngle3 : 47|10@0+ (0.00012207,0) [0|0.12487761] "rad" Vector__XXX
 SG_ Loc41_YSigmaAngle2 : 19|10@0+ (0.00012207,0) [0|0.12487761] "rad" Vector__XXX
 SG_ Loc41_YSigmaAngle1 : 13|10@0+ (0.00012207,0) [0|0.12487761] "rad" Vector__XXX
 SG_ Loc41_YSigmaAngle0 : 7|10@0+ (0.00012207,0) [0|0.12487761] "rad" Vector__XXX

BO_ 1177 location41_C: 8 Bosch_Radar1
 SG_ Loc41_YAngle3 : 55|16@0+ (6.103608E-005,-2) [-2|1.9999995028] "rad" Vector__XXX
 SG_ Loc41_YAngle2 : 39|16@0+ (6.103608E-005,-2) [-2|1.9999995028] "rad" Vector__XXX
 SG_ Loc41_YAngle1 : 23|16@0+ (6.103608E-005,-2) [-2|1.9999995028] "rad" Vector__XXX
 SG_ Loc41_YAngle0 : 7|16@0+ (6.103608E-005,-2) [-2|1.9999995028] "rad" Vector__XXX

BO_ 1178 location41_D: 8 Bosch_Radar1
 SG_ Loc41_vRel : 52|10@0+ (0.125,-64) [-64|63.875] "m/s" Vector__XXX
 SG_ Loc41_Power4 : 43|7@0+ (1,-64) [-64|63] "dBm^2" Vector__XXX
 SG_ Loc41_Power3 : 34|7@0+ (1,-64) [-64|63] "dBm^2" Vector__XXX
 SG_ Loc41_Power2 : 25|7@0+ (1,-64) [-64|63] "dBm^2" Vector__XXX
 SG_ Loc41_Power1 : 16|7@0+ (1,-64) [-64|63] "dBm^2" Vector__XXX
 SG_ Loc41_Power0 : 23|7@0+ (1,-64) [-64|63] "dBm^2" Vector__XXX
 SG_ Loc41_YAngle4 : 7|16@0+ (6.103608E-005,-2) [-2|1.9999995028] "rad" Vector__XXX

BO_ 1179 location42_A: 8 Bosch_Radar1
 SG_ Loc42_Status : 62|1@0+ (1,0) [0|1] "" Vector__XXX
 SG_ Loc42_AngleType : 63|1@0+ (1,0) [0|1] "" Vector__XXX
 SG_ Loc42_YExistProb4 : 55|8@0+ (0.00390625,0) [0|1] "" Vector__XXX
 SG_ Loc42_YExistProb3 : 47|8@0+ (0.00390625,0) [0|1] "" Vector__XXX
 SG_ Loc42_YExistProb2 : 39|8@0+ (0.00390625,0) [0|1] "" Vector__XXX
 SG_ Loc42_YExistProb1 : 31|8@0+ (0.00390625,0) [0|1] "" Vector__XXX
 SG_ Loc42_YExistProb0 : 23|8@0+ (0.00390625,0) [0|1] "" Vector__XXX
 SG_ Loc42_RadialDist : 7|16@0+ (0.0039063,0) [0|255.9993705] "m" Vector__XXX

BO_ 1180 location42_B: 8 Bosch_Radar1
 SG_ Loc42_ZCorrelated : 53|10@0+ (0.00390625,-2) [-2|1.99609375] "rad" Vector__XXX
 SG_ Loc42_YSigmaAngle4 : 25|10@0+ (0.00012207,0) [0|0.12487761] "rad" Vector__XXX
 SG_ Loc42_YSigmaAngle3 : 47|10@0+ (0.00012207,0) [0|0.12487761] "rad" Vector__XXX
 SG_ Loc42_YSigmaAngle2 : 19|10@0+ (0.00012207,0) [0|0.12487761] "rad" Vector__XXX
 SG_ Loc42_YSigmaAngle1 : 13|10@0+ (0.00012207,0) [0|0.12487761] "rad" Vector__XXX
 SG_ Loc42_YSigmaAngle0 : 7|10@0+ (0.00012207,0) [0|0.12487761] "rad" Vector__XXX

BO_ 1181 location42_C: 8 Bosch_Radar1
 SG_ Loc42_YAngle3 : 55|16@0+ (6.103608E-005,-2) [-2|1.9999995028] "rad" Vector__XXX
 SG_ Loc42_YAngle2 : 39|16@0+ (6.103608E-005,-2) [-2|1.9999995028] "rad" Vector__XXX
 SG_ Loc42_YAngle1 : 23|16@0+ (6.103608E-005,-2) [-2|1.9999995028] "rad" Vector__XXX
 SG_ Loc42_YAngle0 : 7|16@0+ (6.103608E-005,-2) [-2|1.9999995028] "rad" Vector__XXX

BO_ 1182 location42_D: 8 Bosch_Radar1
 SG_ Loc42_vRel : 52|10@0+ (0.125,-64) [-64|63.875] "m/s" Vector__XXX
 SG_ Loc42_Power4 : 43|7@0+ (1,-64) [-64|63] "dBm^2" Vector__XXX
 SG_ Loc42_Power3 : 34|7@0+ (1,-64) [-64|63] "dBm^2" Vector__XXX
 SG_ Loc42_Power2 : 25|7@0+ (1,-64) [-64|63] "dBm^2" Vector__XXX
 SG_ Loc42_Power1 : 16|7@0+ (1,-64) [-64|63] "dBm^2" Vector__XXX
 SG_ Loc42_Power0 : 23|7@0+ (1,-64) [-64|63] "dBm^2" Vector__XXX
 SG_ Loc42_YAngle4 : 7|16@0+ (6.103608E-005,-2) [-2|1.9999995028] "rad" Vector__XXX

BO_ 1183 location43_A: 8 Bosch_Radar1
 SG_ Loc43_Status : 62|1@0+ (1,0) [0|1] "" Vector__XXX
 SG_ Loc43_AngleType : 63|1@0+ (1,0) [0|1] "" Vector__XXX
 SG_ Loc43_YExistProb4 : 55|8@0+ (0.00390625,0) [0|1] "" Vector__XXX
 SG_ Loc43_YExistProb3 : 47|8@0+ (0.00390625,0) [0|1] "" Vector__XXX
 SG_ Loc43_YExistProb2 : 39|8@0+ (0.00390625,0) [0|1] "" Vector__XXX
 SG_ Loc43_YExistProb1 : 31|8@0+ (0.00390625,0) [0|1] "" Vector__XXX
 SG_ Loc43_YExistProb0 : 23|8@0+ (0.00390625,0) [0|1] "" Vector__XXX
 SG_ Loc43_RadialDist : 7|16@0+ (0.0039063,0) [0|255.9993705] "m" Vector__XXX

BO_ 1184 location43_B: 8 Bosch_Radar1
 SG_ Loc43_ZCorrelated : 53|10@0+ (0.00390625,-2) [-2|1.99609375] "rad" Vector__XXX
 SG_ Loc43_YSigmaAngle4 : 25|10@0+ (0.00012207,0) [0|0.12487761] "rad" Vector__XXX
 SG_ Loc43_YSigmaAngle3 : 47|10@0+ (0.00012207,0) [0|0.12487761] "rad" Vector__XXX
 SG_ Loc43_YSigmaAngle2 : 19|10@0+ (0.00012207,0) [0|0.12487761] "rad" Vector__XXX
 SG_ Loc43_YSigmaAngle1 : 13|10@0+ (0.00012207,0) [0|0.12487761] "rad" Vector__XXX
 SG_ Loc43_YSigmaAngle0 : 7|10@0+ (0.00012207,0) [0|0.12487761] "rad" Vector__XXX

BO_ 1185 location43_C: 8 Bosch_Radar1
 SG_ Loc43_YAngle3 : 55|16@0+ (6.103608E-005,-2) [-2|1.9999995028] "rad" Vector__XXX
 SG_ Loc43_YAngle2 : 39|16@0+ (6.103608E-005,-2) [-2|1.9999995028] "rad" Vector__XXX
 SG_ Loc43_YAngle1 : 23|16@0+ (6.103608E-005,-2) [-2|1.9999995028] "rad" Vector__XXX
 SG_ Loc43_YAngle0 : 7|16@0+ (6.103608E-005,-2) [-2|1.9999995028] "rad" Vector__XXX

BO_ 1186 location43_D: 8 Bosch_Radar1
 SG_ Loc43_vRel : 52|10@0+ (0.125,-64) [-64|63.875] "m/s" Vector__XXX
 SG_ Loc43_Power4 : 43|7@0+ (1,-64) [-64|63] "dBm^2" Vector__XXX
 SG_ Loc43_Power3 : 34|7@0+ (1,-64) [-64|63] "dBm^2" Vector__XXX
 SG_ Loc43_Power2 : 25|7@0+ (1,-64) [-64|63] "dBm^2" Vector__XXX
 SG_ Loc43_Power1 : 16|7@0+ (1,-64) [-64|63] "dBm^2" Vector__XXX
 SG_ Loc43_Power0 : 23|7@0+ (1,-64) [-64|63] "dBm^2" Vector__XXX
 SG_ Loc43_YAngle4 : 7|16@0+ (6.103608E-005,-2) [-2|1.9999995028] "rad" Vector__XXX

BO_ 1187 location44_A: 8 Bosch_Radar1
 SG_ Loc44_Status : 62|1@0+ (1,0) [0|1] "" Vector__XXX
 SG_ Loc44_AngleType : 63|1@0+ (1,0) [0|1] "" Vector__XXX
 SG_ Loc44_YExistProb4 : 55|8@0+ (0.00390625,0) [0|1] "" Vector__XXX
 SG_ Loc44_YExistProb3 : 47|8@0+ (0.00390625,0) [0|1] "" Vector__XXX
 SG_ Loc44_YExistProb2 : 39|8@0+ (0.00390625,0) [0|1] "" Vector__XXX
 SG_ Loc44_YExistProb1 : 31|8@0+ (0.00390625,0) [0|1] "" Vector__XXX
 SG_ Loc44_YExistProb0 : 23|8@0+ (0.00390625,0) [0|1] "" Vector__XXX
 SG_ Loc44_RadialDist : 7|16@0+ (0.0039063,0) [0|255.9993705] "m" Vector__XXX

BO_ 1188 location44_B: 8 Bosch_Radar1
 SG_ Loc44_ZCorrelated : 53|10@0+ (0.00390625,-2) [-2|1.99609375] "rad" Vector__XXX
 SG_ Loc44_YSigmaAngle4 : 25|10@0+ (0.00012207,0) [0|0.12487761] "rad" Vector__XXX
 SG_ Loc44_YSigmaAngle3 : 47|10@0+ (0.00012207,0) [0|0.12487761] "rad" Vector__XXX
 SG_ Loc44_YSigmaAngle2 : 19|10@0+ (0.00012207,0) [0|0.12487761] "rad" Vector__XXX
 SG_ Loc44_YSigmaAngle1 : 13|10@0+ (0.00012207,0) [0|0.12487761] "rad" Vector__XXX
 SG_ Loc44_YSigmaAngle0 : 7|10@0+ (0.00012207,0) [0|0.12487761] "rad" Vector__XXX

BO_ 1189 location44_C: 8 Bosch_Radar1
 SG_ Loc44_YAngle3 : 55|16@0+ (6.103608E-005,-2) [-2|1.9999995028] "rad" Vector__XXX
 SG_ Loc44_YAngle2 : 39|16@0+ (6.103608E-005,-2) [-2|1.9999995028] "rad" Vector__XXX
 SG_ Loc44_YAngle1 : 23|16@0+ (6.103608E-005,-2) [-2|1.9999995028] "rad" Vector__XXX
 SG_ Loc44_YAngle0 : 7|16@0+ (6.103608E-005,-2) [-2|1.9999995028] "rad" Vector__XXX

BO_ 1190 location44_D: 8 Bosch_Radar1
 SG_ Loc44_vRel : 52|10@0+ (0.125,-64) [-64|63.875] "m/s" Vector__XXX
 SG_ Loc44_Power4 : 43|7@0+ (1,-64) [-64|63] "dBm^2" Vector__XXX
 SG_ Loc44_Power3 : 34|7@0+ (1,-64) [-64|63] "dBm^2" Vector__XXX
 SG_ Loc44_Power2 : 25|7@0+ (1,-64) [-64|63] "dBm^2" Vector__XXX
 SG_ Loc44_Power1 : 16|7@0+ (1,-64) [-64|63] "dBm^2" Vector__XXX
 SG_ Loc44_Power0 : 23|7@0+ (1,-64) [-64|63] "dBm^2" Vector__XXX
 SG_ Loc44_YAngle4 : 7|16@0+ (6.103608E-005,-2) [-2|1.9999995028] "rad" Vector__XXX

BO_ 1191 location45_A: 8 Bosch_Radar1
 SG_ Loc45_Status : 62|1@0+ (1,0) [0|1] "" Vector__XXX
 SG_ Loc45_AngleType : 63|1@0+ (1,0) [0|1] "" Vector__XXX
 SG_ Loc45_YExistProb4 : 55|8@0+ (0.00390625,0) [0|1] "" Vector__XXX
 SG_ Loc45_YExistProb3 : 47|8@0+ (0.00390625,0) [0|1] "" Vector__XXX
 SG_ Loc45_YExistProb2 : 39|8@0+ (0.00390625,0) [0|1] "" Vector__XXX
 SG_ Loc45_YExistProb1 : 31|8@0+ (0.00390625,0) [0|1] "" Vector__XXX
 SG_ Loc45_YExistProb0 : 23|8@0+ (0.00390625,0) [0|1] "" Vector__XXX
 SG_ Loc45_RadialDist : 7|16@0+ (0.0039063,0) [0|255.9993705] "m" Vector__XXX

BO_ 1192 location45_B: 8 Bosch_Radar1
 SG_ Loc45_ZCorrelated : 53|10@0+ (0.00390625,-2) [-2|1.99609375] "rad" Vector__XXX
 SG_ Loc45_YSigmaAngle4 : 25|10@0+ (0.00012207,0) [0|0.12487761] "rad" Vector__XXX
 SG_ Loc45_YSigmaAngle3 : 47|10@0+ (0.00012207,0) [0|0.12487761] "rad" Vector__XXX
 SG_ Loc45_YSigmaAngle2 : 19|10@0+ (0.00012207,0) [0|0.12487761] "rad" Vector__XXX
 SG_ Loc45_YSigmaAngle1 : 13|10@0+ (0.00012207,0) [0|0.12487761] "rad" Vector__XXX
 SG_ Loc45_YSigmaAngle0 : 7|10@0+ (0.00012207,0) [0|0.12487761] "rad" Vector__XXX

BO_ 1193 location45_C: 8 Bosch_Radar1
 SG_ Loc45_YAngle3 : 55|16@0+ (6.103608E-005,-2) [-2|1.9999995028] "rad" Vector__XXX
 SG_ Loc45_YAngle2 : 39|16@0+ (6.103608E-005,-2) [-2|1.9999995028] "rad" Vector__XXX
 SG_ Loc45_YAngle1 : 23|16@0+ (6.103608E-005,-2) [-2|1.9999995028] "rad" Vector__XXX
 SG_ Loc45_YAngle0 : 7|16@0+ (6.103608E-005,-2) [-2|1.9999995028] "rad" Vector__XXX

BO_ 1194 location45_D: 8 Bosch_Radar1
 SG_ Loc45_vRel : 52|10@0+ (0.125,-64) [-64|63.875] "m/s" Vector__XXX
 SG_ Loc45_Power4 : 43|7@0+ (1,-64) [-64|63] "dBm^2" Vector__XXX
 SG_ Loc45_Power3 : 34|7@0+ (1,-64) [-64|63] "dBm^2" Vector__XXX
 SG_ Loc45_Power2 : 25|7@0+ (1,-64) [-64|63] "dBm^2" Vector__XXX
 SG_ Loc45_Power1 : 16|7@0+ (1,-64) [-64|63] "dBm^2" Vector__XXX
 SG_ Loc45_Power0 : 23|7@0+ (1,-64) [-64|63] "dBm^2" Vector__XXX
 SG_ Loc45_YAngle4 : 7|16@0+ (6.103608E-005,-2) [-2|1.9999995028] "rad" Vector__XXX

BO_ 1195 location46_A: 8 Bosch_Radar1
 SG_ Loc46_Status : 62|1@0+ (1,0) [0|1] "" Vector__XXX
 SG_ Loc46_AngleType : 63|1@0+ (1,0) [0|1] "" Vector__XXX
 SG_ Loc46_YExistProb4 : 55|8@0+ (0.00390625,0) [0|1] "" Vector__XXX
 SG_ Loc46_YExistProb3 : 47|8@0+ (0.00390625,0) [0|1] "" Vector__XXX
 SG_ Loc46_YExistProb2 : 39|8@0+ (0.00390625,0) [0|1] "" Vector__XXX
 SG_ Loc46_YExistProb1 : 31|8@0+ (0.00390625,0) [0|1] "" Vector__XXX
 SG_ Loc46_YExistProb0 : 23|8@0+ (0.00390625,0) [0|1] "" Vector__XXX
 SG_ Loc46_RadialDist : 7|16@0+ (0.0039063,0) [0|255.9993705] "m" Vector__XXX

BO_ 1196 location46_B: 8 Bosch_Radar1
 SG_ Loc46_ZCorrelated : 53|10@0+ (0.00390625,-2) [-2|1.99609375] "rad" Vector__XXX
 SG_ Loc46_YSigmaAngle4 : 25|10@0+ (0.00012207,0) [0|0.12487761] "rad" Vector__XXX
 SG_ Loc46_YSigmaAngle3 : 47|10@0+ (0.00012207,0) [0|0.12487761] "rad" Vector__XXX
 SG_ Loc46_YSigmaAngle2 : 19|10@0+ (0.00012207,0) [0|0.12487761] "rad" Vector__XXX
 SG_ Loc46_YSigmaAngle1 : 13|10@0+ (0.00012207,0) [0|0.12487761] "rad" Vector__XXX
 SG_ Loc46_YSigmaAngle0 : 7|10@0+ (0.00012207,0) [0|0.12487761] "rad" Vector__XXX

BO_ 1197 location46_C: 8 Bosch_Radar1
 SG_ Loc46_YAngle3 : 55|16@0+ (6.103608E-005,-2) [-2|1.9999995028] "rad" Vector__XXX
 SG_ Loc46_YAngle2 : 39|16@0+ (6.103608E-005,-2) [-2|1.9999995028] "rad" Vector__XXX
 SG_ Loc46_YAngle1 : 23|16@0+ (6.103608E-005,-2) [-2|1.9999995028] "rad" Vector__XXX
 SG_ Loc46_YAngle0 : 7|16@0+ (6.103608E-005,-2) [-2|1.9999995028] "rad" Vector__XXX

BO_ 1198 location46_D: 8 Bosch_Radar1
 SG_ Loc46_vRel : 52|10@0+ (0.125,-64) [-64|63.875] "m/s" Vector__XXX
 SG_ Loc46_Power4 : 43|7@0+ (1,-64) [-64|63] "dBm^2" Vector__XXX
 SG_ Loc46_Power3 : 34|7@0+ (1,-64) [-64|63] "dBm^2" Vector__XXX
 SG_ Loc46_Power2 : 25|7@0+ (1,-64) [-64|63] "dBm^2" Vector__XXX
 SG_ Loc46_Power1 : 16|7@0+ (1,-64) [-64|63] "dBm^2" Vector__XXX
 SG_ Loc46_Power0 : 23|7@0+ (1,-64) [-64|63] "dBm^2" Vector__XXX
 SG_ Loc46_YAngle4 : 7|16@0+ (6.103608E-005,-2) [-2|1.9999995028] "rad" Vector__XXX

BO_ 1199 location47_A: 8 Bosch_Radar1
 SG_ Loc47_Status : 62|1@0+ (1,0) [0|1] "" Vector__XXX
 SG_ Loc47_AngleType : 63|1@0+ (1,0) [0|1] "" Vector__XXX
 SG_ Loc47_YExistProb4 : 55|8@0+ (0.00390625,0) [0|1] "" Vector__XXX
 SG_ Loc47_YExistProb3 : 47|8@0+ (0.00390625,0) [0|1] "" Vector__XXX
 SG_ Loc47_YExistProb2 : 39|8@0+ (0.00390625,0) [0|1] "" Vector__XXX
 SG_ Loc47_YExistProb1 : 31|8@0+ (0.00390625,0) [0|1] "" Vector__XXX
 SG_ Loc47_YExistProb0 : 23|8@0+ (0.00390625,0) [0|1] "" Vector__XXX
 SG_ Loc47_RadialDist : 7|16@0+ (0.0039063,0) [0|255.9993705] "m" Vector__XXX

BO_ 1200 location47_B: 8 Bosch_Radar1
 SG_ Loc47_ZCorrelated : 53|10@0+ (0.00390625,-2) [-2|1.99609375] "rad" Vector__XXX
 SG_ Loc47_YSigmaAngle4 : 25|10@0+ (0.00012207,0) [0|0.12487761] "rad" Vector__XXX
 SG_ Loc47_YSigmaAngle3 : 47|10@0+ (0.00012207,0) [0|0.12487761] "rad" Vector__XXX
 SG_ Loc47_YSigmaAngle2 : 19|10@0+ (0.00012207,0) [0|0.12487761] "rad" Vector__XXX
 SG_ Loc47_YSigmaAngle1 : 13|10@0+ (0.00012207,0) [0|0.12487761] "rad" Vector__XXX
 SG_ Loc47_YSigmaAngle0 : 7|10@0+ (0.00012207,0) [0|0.12487761] "rad" Vector__XXX

BO_ 1201 location47_C: 8 Bosch_Radar1
 SG_ Loc47_YAngle3 : 55|16@0+ (6.103608E-005,-2) [-2|1.9999995028] "rad" Vector__XXX
 SG_ Loc47_YAngle2 : 39|16@0+ (6.103608E-005,-2) [-2|1.9999995028] "rad" Vector__XXX
 SG_ Loc47_YAngle1 : 23|16@0+ (6.103608E-005,-2) [-2|1.9999995028] "rad" Vector__XXX
 SG_ Loc47_YAngle0 : 7|16@0+ (6.103608E-005,-2) [-2|1.9999995028] "rad" Vector__XXX

BO_ 1202 location47_D: 8 Bosch_Radar1
 SG_ Loc47_vRel : 52|10@0+ (0.125,-64) [-64|63.875] "m/s" Vector__XXX
 SG_ Loc47_Power4 : 43|7@0+ (1,-64) [-64|63] "dBm^2" Vector__XXX
 SG_ Loc47_Power3 : 34|7@0+ (1,-64) [-64|63] "dBm^2" Vector__XXX
 SG_ Loc47_Power2 : 25|7@0+ (1,-64) [-64|63] "dBm^2" Vector__XXX
 SG_ Loc47_Power1 : 16|7@0+ (1,-64) [-64|63] "dBm^2" Vector__XXX
 SG_ Loc47_Power0 : 23|7@0+ (1,-64) [-64|63] "dBm^2" Vector__XXX
 SG_ Loc47_YAngle4 : 7|16@0+ (6.103608E-005,-2) [-2|1.9999995028] "rad" Vector__XXX

BO_ 1285 Radar1_Obj00_A: 8 Bosch_Radar1
 SG_ Radar1_Obj00_wObstacle : 53|5@0+ (0.03125,0) [0|0.96875] "" Vector__XXX
 SG_ Radar1_Obj00_wNonObstacle : 63|5@0+ (0.03125,0) [0|0.96875] "" Vector__XXX
 SG_ Radar1_Obj00_wExist : 36|5@0+ (0.03125,0) [0|0.96875] "-" Vector__XXX
 SG_ Radar1_Obj00_ax : 47|10@0+ (0.03125,-16) [-16|15.96875] "m/s2" Vector__XXX
 SG_ Radar1_Obj00_vx : 11|12@0+ (0.0625,-128) [-128|127.9375] "m/s" Vector__XXX
 SG_ Radar1_Obj00_dy : 31|11@0+ (0.125,-128) [-128|127.875] "m" Vector__XXX
 SG_ Radar1_Obj00_dx : 7|12@0+ (0.0625,0) [0|255.9375] "m" Vector__XXX
 SG_ Radar1_Obj00_flagValid : 48|1@0+ (1,0) [0|1] "" Vector__XXX
 SG_ Radar1_Obj00_flagHist : 57|1@0+ (1,0) [0|1] "" Vector__XXX
 SG_ Radar1_Obj00_flagMeas : 58|1@0+ (1,0) [0|1] "" Vector__XXX
 SG_ Radar1_Obj00_MessAconsistBit : 56|1@0+ (1,0) [0|1] "" Vector__XXX

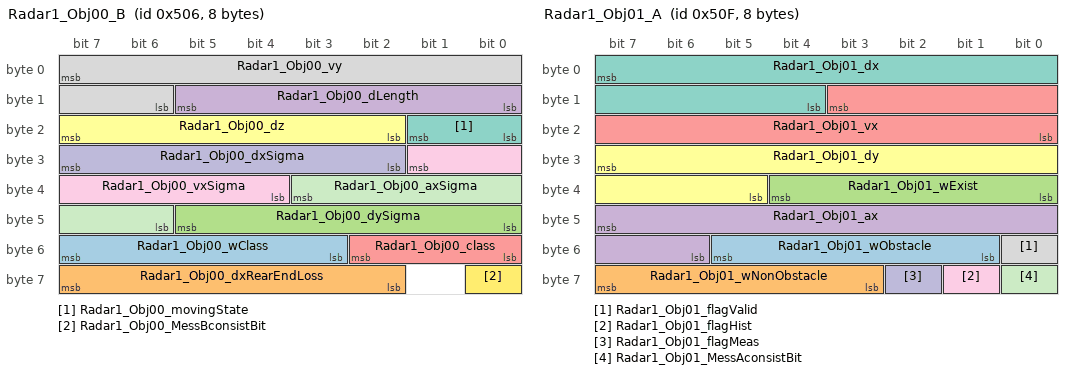
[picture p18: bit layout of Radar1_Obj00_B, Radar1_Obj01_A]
BO_ 1286 Radar1_Obj00_B: 8 Bosch_Radar1
 SG_ Radar1_Obj00_wClass : 55|5@0+ (0.03125,0) [0|0.96875] "" Vector__XXX
 SG_ Radar1_Obj00_dxRearEndLoss : 63|6@0+ (0.125,0) [0|7.875] "m" Vector__XXX
 SG_ Radar1_Obj00_dySigma : 45|6@0+ (0.0625,0) [0|3.9375] "m" Vector__XXX
 SG_ Radar1_Obj00_dLength : 13|6@0+ (0.125,0) [0|7.875] "m" Vector__XXX
 SG_ Radar1_Obj00_class : 50|3@0+ (1,0) [0|7] "" Vector__XXX
 SG_ Radar1_Obj00_dz : 23|6@0+ (0.25,-5) [-5|10.75] "m" Vector__XXX
 SG_ Radar1_Obj00_movingState : 17|2@0+ (1,0) [0|3] "" Vector__XXX
 SG_ Radar1_Obj00_vy : 7|10@0+ (0.125,-64) [-64|63.875] "m/s" Vector__XXX
 SG_ Radar1_Obj00_vxSigma : 25|6@0+ (0.0625,0) [0|3.9375] "m/s" Vector__XXX
 SG_ Radar1_Obj00_dxSigma : 31|6@0+ (0.0625,0) [0|3.9375] "m" Vector__XXX
 SG_ Radar1_Obj00_axSigma : 35|6@0+ (0.0625,0) [0|3.9375] "m/s2" Vector__XXX
 SG_ Radar1_Obj00_MessBconsistBit : 56|1@0+ (1,0) [0|1] "" Vector__XXX

BO_ 1295 Radar1_Obj01_A: 8 Bosch_Radar1
 SG_ Radar1_Obj01_wObstacle : 53|5@0+ (0.03125,0) [0|0.96875] "" Vector__XXX
 SG_ Radar1_Obj01_wNonObstacle : 63|5@0+ (0.03125,0) [0|0.96875] "" Vector__XXX
 SG_ Radar1_Obj01_wExist : 36|5@0+ (0.03125,0) [0|0.96875] "-" Vector__XXX
 SG_ Radar1_Obj01_ax : 47|10@0+ (0.03125,-16) [-16|15.96875] "m/s2" Vector__XXX
 SG_ Radar1_Obj01_vx : 11|12@0+ (0.0625,-128) [-128|127.9375] "m/s" Vector__XXX
 SG_ Radar1_Obj01_dy : 31|11@0+ (0.125,-128) [-128|127.875] "m" Vector__XXX
 SG_ Radar1_Obj01_dx : 7|12@0+ (0.0625,0) [0|255.9375] "m" Vector__XXX
 SG_ Radar1_Obj01_flagValid : 48|1@0+ (1,0) [0|1] "" Vector__XXX
 SG_ Radar1_Obj01_flagHist : 57|1@0+ (1,0) [0|1] "" Vector__XXX
 SG_ Radar1_Obj01_flagMeas : 58|1@0+ (1,0) [0|1] "" Vector__XXX
 SG_ Radar1_Obj01_MessAconsistBit : 56|1@0+ (1,0) [0|1] "" Vector__XXX

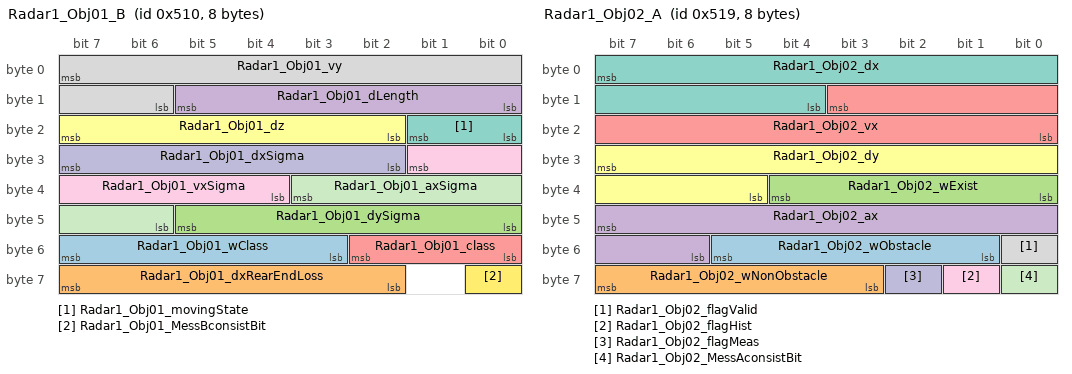
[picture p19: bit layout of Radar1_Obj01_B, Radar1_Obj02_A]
BO_ 1296 Radar1_Obj01_B: 8 Bosch_Radar1
 SG_ Radar1_Obj01_wClass : 55|5@0+ (0.03125,0) [0|0.96875] "" Vector__XXX
 SG_ Radar1_Obj01_dxRearEndLoss : 63|6@0+ (0.125,0) [0|7.875] "m" Vector__XXX
 SG_ Radar1_Obj01_dySigma : 45|6@0+ (0.0625,0) [0|3.9375] "m" Vector__XXX
 SG_ Radar1_Obj01_dLength : 13|6@0+ (0.125,0) [0|7.875] "m" Vector__XXX
 SG_ Radar1_Obj01_class : 50|3@0+ (1,0) [0|7] "" Vector__XXX
 SG_ Radar1_Obj01_dz : 23|6@0+ (0.25,-5) [-5|10.75] "m" Vector__XXX
 SG_ Radar1_Obj01_movingState : 17|2@0+ (1,0) [0|3] "" Vector__XXX
 SG_ Radar1_Obj01_vy : 7|10@0+ (0.125,-64) [-64|63.875] "m/s" Vector__XXX
 SG_ Radar1_Obj01_vxSigma : 25|6@0+ (0.0625,0) [0|3.9375] "m/s" Vector__XXX
 SG_ Radar1_Obj01_dxSigma : 31|6@0+ (0.0625,0) [0|3.9375] "m" Vector__XXX
 SG_ Radar1_Obj01_axSigma : 35|6@0+ (0.0625,0) [0|3.9375] "m/s2" Vector__XXX
 SG_ Radar1_Obj01_MessBconsistBit : 56|1@0+ (1,0) [0|1] "" Vector__XXX

BO_ 1305 Radar1_Obj02_A: 8 Bosch_Radar1
 SG_ Radar1_Obj02_wObstacle : 53|5@0+ (0.03125,0) [0|0.96875] "" Vector__XXX
 SG_ Radar1_Obj02_wNonObstacle : 63|5@0+ (0.03125,0) [0|0.96875] "" Vector__XXX
 SG_ Radar1_Obj02_wExist : 36|5@0+ (0.03125,0) [0|0.96875] "-" Vector__XXX
 SG_ Radar1_Obj02_ax : 47|10@0+ (0.03125,-16) [-16|15.96875] "m/s2" Vector__XXX
 SG_ Radar1_Obj02_vx : 11|12@0+ (0.0625,-128) [-128|127.9375] "m/s" Vector__XXX
 SG_ Radar1_Obj02_dy : 31|11@0+ (0.125,-128) [-128|127.875] "m" Vector__XXX
 SG_ Radar1_Obj02_dx : 7|12@0+ (0.0625,0) [0|255.9375] "m" Vector__XXX
 SG_ Radar1_Obj02_flagValid : 48|1@0+ (1,0) [0|1] "" Vector__XXX
 SG_ Radar1_Obj02_flagHist : 57|1@0+ (1,0) [0|1] "" Vector__XXX
 SG_ Radar1_Obj02_flagMeas : 58|1@0+ (1,0) [0|1] "" Vector__XXX
 SG_ Radar1_Obj02_MessAconsistBit : 56|1@0+ (1,0) [0|1] "" Vector__XXX

BO_TX_BU_ 1010 : Bosch_Radar2,Bosch_Radar1;
BO_TX_BU_ 1203 : Bosch_Radar2,Bosch_Radar1;
BO_TX_BU_ 1011 : Bosch_Radar2,Bosch_Radar1;
BO_TX_BU_ 1012 : Bosch_Radar2,Bosch_Radar1;
BO_TX_BU_ 1013 : Bosch_Radar2,Bosch_Radar1;
BO_TX_BU_ 1014 : Bosch_Radar2,Bosch_Radar1;
BO_TX_BU_ 1015 : Bosch_Radar2,Bosch_Radar1;
BO_TX_BU_ 1016 : Bosch_Radar2,Bosch_Radar1;
BO_TX_BU_ 1017 : Bosch_Radar2,Bosch_Radar1;
BO_TX_BU_ 1018 : Bosch_Radar2,Bosch_Radar1;
BO_TX_BU_ 1019 : Bosch_Radar2,Bosch_Radar1;
BO_TX_BU_ 1020 : Bosch_Radar2,Bosch_Radar1;
BO_TX_BU_ 1021 : Bosch_Radar2,Bosch_Radar1;
BO_TX_BU_ 1022 : Bosch_Radar2,Bosch_Radar1;
BO_TX_BU_ 1023 : Bosch_Radar2,Bosch_Radar1;
BO_TX_BU_ 1024 : Bosch_Radar2,Bosch_Radar1;
BO_TX_BU_ 1025 : Bosch_Radar2,Bosch_Radar1;
BO_TX_BU_ 1026 : Bosch_Radar2,Bosch_Radar1;
BO_TX_BU_ 1027 : Bosch_Radar2,Bosch_Radar1;
BO_TX_BU_ 1028 : Bosch_Radar2,Bosch_Radar1;
BO_TX_BU_ 1029 : Bosch_Radar2,Bosch_Radar1;
BO_TX_BU_ 1030 : Bosch_Radar2,Bosch_Radar1;
BO_TX_BU_ 1031 : Bosch_Radar2,Bosch_Radar1;
BO_TX_BU_ 1032 : Bosch_Radar2,Bosch_Radar1;
BO_TX_BU_ 1033 : Bosch_Radar2,Bosch_Radar1;
BO_TX_BU_ 1034 : Bosch_Radar2,Bosch_Radar1;
BO_TX_BU_ 1035 : Bosch_Radar2,Bosch_Radar1;
BO_TX_BU_ 1036 : Bosch_Radar2,Bosch_Radar1;
BO_TX_BU_ 1037 : Bosch_Radar2,Bosch_Radar1;
BO_TX_BU_ 1038 : Bosch_Radar2,Bosch_Radar1;
BO_TX_BU_ 1039 : Bosch_Radar2,Bosch_Radar1;
BO_TX_BU_ 1040 : Bosch_Radar2,Bosch_Radar1;
BO_TX_BU_ 1041 : Bosch_Radar2,Bosch_Radar1;
BO_TX_BU_ 1042 : Bosch_Radar2,Bosch_Radar1;
BO_TX_BU_ 1043 : Bosch_Radar2,Bosch_Radar1;
BO_TX_BU_ 1044 : Bosch_Radar2,Bosch_Radar1;
BO_TX_BU_ 1045 : Bosch_Radar2,Bosch_Radar1;
BO_TX_BU_ 1046 : Bosch_Radar2,Bosch_Radar1;
BO_TX_BU_ 1047 : Bosch_Radar2,Bosch_Radar1;
BO_TX_BU_ 1048 : Bosch_Radar2,Bosch_Radar1;
BO_TX_BU_ 1049 : Bosch_Radar2,Bosch_Radar1;
BO_TX_BU_ 1050 : Bosch_Radar2,Bosch_Radar1;
BO_TX_BU_ 1051 : Bosch_Radar2,Bosch_Radar1;
BO_TX_BU_ 1052 : Bosch_Radar2,Bosch_Radar1;
BO_TX_BU_ 1053 : Bosch_Radar2,Bosch_Radar1;
BO_TX_BU_ 1054 : Bosch_Radar2,Bosch_Radar1;
BO_TX_BU_ 1055 : Bosch_Radar2,Bosch_Radar1;
BO_TX_BU_ 1056 : Bosch_Radar2,Bosch_Radar1;
BO_TX_BU_ 1057 : Bosch_Radar2,Bosch_Radar1;
BO_TX_BU_ 1058 : Bosch_Radar2,Bosch_Radar1;
BO_TX_BU_ 1059 : Bosch_Radar2,Bosch_Radar1;
BO_TX_BU_ 1060 : Bosch_Radar2,Bosch_Radar1;
BO_TX_BU_ 1061 : Bosch_Radar2,Bosch_Radar1;
BO_TX_BU_ 1062 : Bosch_Radar2,Bosch_Radar1;
BO_TX_BU_ 1063 : Bosch_Radar2,Bosch_Radar1;
BO_TX_BU_ 1064 : Bosch_Radar2,Bosch_Radar1;
BO_TX_BU_ 1065 : Bosch_Radar2,Bosch_Radar1;
BO_TX_BU_ 1066 : Bosch_Radar2,Bosch_Radar1;
BO_TX_BU_ 1067 : Bosch_Radar2,Bosch_Radar1;
BO_TX_BU_ 1068 : Bosch_Radar2,Bosch_Radar1;
BO_TX_BU_ 1069 : Bosch_Radar2,Bosch_Radar1;
BO_TX_BU_ 1070 : Bosch_Radar2,Bosch_Radar1;
BO_TX_BU_ 1071 : Bosch_Radar2,Bosch_Radar1;
BO_TX_BU_ 1072 : Bosch_Radar2,Bosch_Radar1;
BO_TX_BU_ 1073 : Bosch_Radar2,Bosch_Radar1;
BO_TX_BU_ 1074 : Bosch_Radar2,Bosch_Radar1;
BO_TX_BU_ 1075 : Bosch_Radar2,Bosch_Radar1;
BO_TX_BU_ 1076 : Bosch_Radar2,Bosch_Radar1;
BO_TX_BU_ 1077 : Bosch_Radar2,Bosch_Radar1;
BO_TX_BU_ 1078 : Bosch_Radar2,Bosch_Radar1;
BO_TX_BU_ 1079 : Bosch_Radar2,Bosch_Radar1;
BO_TX_BU_ 1080 : Bosch_Radar2,Bosch_Radar1;
BO_TX_BU_ 1081 : Bosch_Radar2,Bosch_Radar1;
BO_TX_BU_ 1082 : Bosch_Radar2,Bosch_Radar1;
BO_TX_BU_ 1083 : Bosch_Radar2,Bosch_Radar1;
BO_TX_BU_ 1084 : Bosch_Radar2,Bosch_Radar1;
BO_TX_BU_ 1085 : Bosch_Radar2,Bosch_Radar1;
BO_TX_BU_ 1086 : Bosch_Radar2,Bosch_Radar1;
BO_TX_BU_ 1087 : Bosch_Radar2,Bosch_Radar1;
BO_TX_BU_ 1088 : Bosch_Radar2,Bosch_Radar1;
BO_TX_BU_ 1089 : Bosch_Radar2,Bosch_Radar1;
BO_TX_BU_ 1090 : Bosch_Radar2,Bosch_Radar1;
BO_TX_BU_ 1091 : Bosch_Radar2,Bosch_Radar1;
BO_TX_BU_ 1092 : Bosch_Radar2,Bosch_Radar1;
BO_TX_BU_ 1093 : Bosch_Radar2,Bosch_Radar1;
BO_TX_BU_ 1094 : Bosch_Radar2,Bosch_Radar1;
BO_TX_BU_ 1095 : Bosch_Radar2,Bosch_Radar1;
BO_TX_BU_ 1096 : Bosch_Radar2,Bosch_Radar1;
BO_TX_BU_ 1097 : Bosch_Radar2,Bosch_Radar1;
BO_TX_BU_ 1098 : Bosch_Radar2,Bosch_Radar1;
BO_TX_BU_ 1099 : Bosch_Radar2,Bosch_Radar1;
BO_TX_BU_ 1100 : Bosch_Radar2,Bosch_Radar1;
BO_TX_BU_ 1101 : Bosch_Radar2,Bosch_Radar1;
BO_TX_BU_ 1102 : Bosch_Radar2,Bosch_Radar1;
BO_TX_BU_ 1103 : Bosch_Radar2,Bosch_Radar1;
BO_TX_BU_ 1104 : Bosch_Radar2,Bosch_Radar1;
BO_TX_BU_ 1105 : Bosch_Radar2,Bosch_Radar1;
BO_TX_BU_ 1106 : Bosch_Radar2,Bosch_Radar1;
BO_TX_BU_ 1107 : Bosch_Radar2,Bosch_Radar1;
BO_TX_BU_ 1108 : Bosch_Radar2,Bosch_Radar1;
BO_TX_BU_ 1109 : Bosch_Radar2,Bosch_Radar1;
BO_TX_BU_ 1110 : Bosch_Radar2,Bosch_Radar1;
BO_TX_BU_ 1111 : Bosch_Radar2,Bosch_Radar1;
BO_TX_BU_ 1112 : Bosch_Radar2,Bosch_Radar1;
BO_TX_BU_ 1113 : Bosch_Radar2,Bosch_Radar1;
BO_TX_BU_ 1114 : Bosch_Radar2,Bosch_Radar1;
BO_TX_BU_ 1115 : Bosch_Radar2,Bosch_Radar1;
BO_TX_BU_ 1116 : Bosch_Radar2,Bosch_Radar1;
BO_TX_BU_ 1117 : Bosch_Radar2,Bosch_Radar1;
BO_TX_BU_ 1118 : Bosch_Radar2,Bosch_Radar1;
BO_TX_BU_ 1119 : Bosch_Radar2,Bosch_Radar1;
BO_TX_BU_ 1120 : Bosch_Radar2,Bosch_Radar1;
BO_TX_BU_ 1121 : Bosch_Radar2,Bosch_Radar1;
BO_TX_BU_ 1122 : Bosch_Radar2,Bosch_Radar1;
BO_TX_BU_ 1123 : Bosch_Radar2,Bosch_Radar1;
BO_TX_BU_ 1124 : Bosch_Radar2,Bosch_Radar1;
BO_TX_BU_ 1125 : Bosch_Radar2,Bosch_Radar1;
BO_TX_BU_ 1126 : Bosch_Radar2,Bosch_Radar1;
BO_TX_BU_ 1127 : Bosch_Radar2,Bosch_Radar1;
BO_TX_BU_ 1128 : Bosch_Radar2,Bosch_Radar1;
BO_TX_BU_ 1129 : Bosch_Radar2,Bosch_Radar1;
BO_TX_BU_ 1130 : Bosch_Radar2,Bosch_Radar1;
BO_TX_BU_ 1131 : Bosch_Radar2,Bosch_Radar1;
BO_TX_BU_ 1132 : Bosch_Radar2,Bosch_Radar1;
BO_TX_BU_ 1133 : Bosch_Radar2,Bosch_Radar1;
BO_TX_BU_ 1134 : Bosch_Radar2,Bosch_Radar1;
BO_TX_BU_ 1135 : Bosch_Radar2,Bosch_Radar1;
BO_TX_BU_ 1136 : Bosch_Radar2,Bosch_Radar1;
BO_TX_BU_ 1137 : Bosch_Radar2,Bosch_Radar1;
BO_TX_BU_ 1138 : Bosch_Radar2,Bosch_Radar1;
BO_TX_BU_ 1139 : Bosch_Radar2,Bosch_Radar1;
BO_TX_BU_ 1140 : Bosch_Radar2,Bosch_Radar1;
BO_TX_BU_ 1141 : Bosch_Radar2,Bosch_Radar1;
BO_TX_BU_ 1142 : Bosch_Radar2,Bosch_Radar1;
BO_TX_BU_ 1143 : Bosch_Radar2,Bosch_Radar1;
BO_TX_BU_ 1144 : Bosch_Radar2,Bosch_Radar1;
BO_TX_BU_ 1145 : Bosch_Radar2,Bosch_Radar1;
BO_TX_BU_ 1146 : Bosch_Radar2,Bosch_Radar1;
BO_TX_BU_ 1147 : Bosch_Radar2,Bosch_Radar1;
BO_TX_BU_ 1148 : Bosch_Radar2,Bosch_Radar1;
BO_TX_BU_ 1149 : Bosch_Radar2,Bosch_Radar1;
BO_TX_BU_ 1150 : Bosch_Radar2,Bosch_Radar1;
BO_TX_BU_ 1151 : Bosch_Radar2,Bosch_Radar1;
BO_TX_BU_ 1152 : Bosch_Radar2,Bosch_Radar1;
BO_TX_BU_ 1153 : Bosch_Radar2,Bosch_Radar1;
BO_TX_BU_ 1154 : Bosch_Radar2,Bosch_Radar1;
BO_TX_BU_ 1155 : Bosch_Radar2,Bosch_Radar1;
BO_TX_BU_ 1156 : Bosch_Radar2,Bosch_Radar1;
BO_TX_BU_ 1157 : Bosch_Radar2,Bosch_Radar1;
BO_TX_BU_ 1158 : Bosch_Radar2,Bosch_Radar1;
BO_TX_BU_ 1159 : Bosch_Radar2,Bosch_Radar1;
BO_TX_BU_ 1160 : Bosch_Radar2,Bosch_Radar1;
BO_TX_BU_ 1161 : Bosch_Radar2,Bosch_Radar1;
BO_TX_BU_ 1162 : Bosch_Radar2,Bosch_Radar1;
BO_TX_BU_ 1163 : Bosch_Radar2,Bosch_Radar1;
BO_TX_BU_ 1164 : Bosch_Radar2,Bosch_Radar1;
BO_TX_BU_ 1165 : Bosch_Radar2,Bosch_Radar1;
BO_TX_BU_ 1166 : Bosch_Radar2,Bosch_Radar1;
BO_TX_BU_ 1167 : Bosch_Radar2,Bosch_Radar1;
BO_TX_BU_ 1168 : Bosch_Radar2,Bosch_Radar1;
BO_TX_BU_ 1169 : Bosch_Radar2,Bosch_Radar1;
BO_TX_BU_ 1170 : Bosch_Radar2,Bosch_Radar1;
BO_TX_BU_ 1171 : Bosch_Radar2,Bosch_Radar1;
BO_TX_BU_ 1172 : Bosch_Radar2,Bosch_Radar1;
BO_TX_BU_ 1173 : Bosch_Radar2,Bosch_Radar1;
BO_TX_BU_ 1174 : Bosch_Radar2,Bosch_Radar1;
BO_TX_BU_ 1175 : Bosch_Radar2,Bosch_Radar1;
BO_TX_BU_ 1176 : Bosch_Radar2,Bosch_Radar1;
BO_TX_BU_ 1177 : Bosch_Radar2,Bosch_Radar1;
BO_TX_BU_ 1178 : Bosch_Radar2,Bosch_Radar1;
BO_TX_BU_ 1179 : Bosch_Radar2,Bosch_Radar1;
BO_TX_BU_ 1180 : Bosch_Radar2,Bosch_Radar1;
BO_TX_BU_ 1181 : Bosch_Radar2,Bosch_Radar1;
BO_TX_BU_ 1182 : Bosch_Radar2,Bosch_Radar1;
BO_TX_BU_ 1183 : Bosch_Radar2,Bosch_Radar1;
BO_TX_BU_ 1184 : Bosch_Radar2,Bosch_Radar1;
BO_TX_BU_ 1185 : Bosch_Radar2,Bosch_Radar1;
BO_TX_BU_ 1186 : Bosch_Radar2,Bosch_Radar1;
BO_TX_BU_ 1187 : Bosch_Radar2,Bosch_Radar1;
BO_TX_BU_ 1188 : Bosch_Radar2,Bosch_Radar1;
BO_TX_BU_ 1189 : Bosch_Radar2,Bosch_Radar1;
BO_TX_BU_ 1190 : Bosch_Radar2,Bosch_Radar1;
BO_TX_BU_ 1191 : Bosch_Radar2,Bosch_Radar1;
BO_TX_BU_ 1192 : Bosch_Radar2,Bosch_Radar1;
BO_TX_BU_ 1193 : Bosch_Radar2,Bosch_Radar1;
BO_TX_BU_ 1194 : Bosch_Radar2,Bosch_Radar1;
BO_TX_BU_ 1195 : Bosch_Radar2,Bosch_Radar1;
BO_TX_BU_ 1196 : Bosch_Radar2,Bosch_Radar1;
BO_TX_BU_ 1197 : Bosch_Radar2,Bosch_Radar1;
BO_TX_BU_ 1198 : Bosch_Radar2,Bosch_Radar1;
BO_TX_BU_ 1199 : Bosch_Radar2,Bosch_Radar1;
BO_TX_BU_ 1200 : Bosch_Radar2,Bosch_Radar1;
BO_TX_BU_ 1201 : Bosch_Radar2,Bosch_Radar1;
BO_TX_BU_ 1202 : Bosch_Radar2,Bosch_Radar1;

CM_ "XGU Network";
BA_DEF_ SG_  "GenSigSendOnInit" ENUM  "Not Initialized","Application","Handler";
BA_DEF_ SG_  "GenSigSendType" ENUM  "not used","not used","not used","not used","not used","not used","not used","NoSigSendType","not used","not used","OnAnyChange","OnChangeIfActive","OnDelta";
BA_DEF_ SG_  "GenSigStartValue" INT 0 65535;
BA_DEF_ BO_  "GenMsgSendType" ENUM  "cyclic","triggered";
BA_DEF_ BU_  "NmNode" ENUM  "No","Yes";
BA_DEF_ BU_  "MessageManagerUsed" ENUM  "No","Yes";
BA_DEF_  "NmType" STRING ;
BA_DEF_  "Manufacturer" ENUM  "Unknown","DBAG","VAG","BMW","PAG","GM";
BA_DEF_  "NmBaseAddress" HEX 0 2032;
BA_DEF_  "NmMessageCount" INT 0 32;
BA_DEF_  "Baudrate" INT 0 1000000;
BA_DEF_ BO_  "GenMsgCycleTime" INT 0 100000;
BA_DEF_  "BusType" STRING ;
BA_DEF_DEF_  "GenSigSendOnInit" "Not Initialized";
BA_DEF_DEF_  "GenSigSendType" "NoSigSendType";
BA_DEF_DEF_  "GenSigStartValue" 0;
BA_DEF_DEF_  "GenMsgSendType" "triggered";
BA_DEF_DEF_  "NmNode" "Yes";
BA_DEF_DEF_  "MessageManagerUsed" "Yes";
BA_DEF_DEF_  "NmType" "GMLAN";
BA_DEF_DEF_  "Manufacturer" "Unknown";
BA_DEF_DEF_  "NmBaseAddress" 1568;
BA_DEF_DEF_  "NmMessageCount" 32;
BA_DEF_DEF_  "Baudrate" 0;
BA_DEF_DEF_  "GenMsgCycleTime" 0;
BA_DEF_DEF_  "BusType" "";
BA_ "Baudrate" 500;
BA_ "NmBaseAddress" 0;
BA_ "NmType" "unknown";
BA_ "BusType" "CAN";
VAL_ 1012 Loc00_YSigmaAngle4 1023 "SNA" ;
VAL_ 1012 Loc00_YSigmaAngle3 1023 "SNA" ;
VAL_ 1012 Loc00_YSigmaAngle2 1023 "SNA" ;
VAL_ 1012 Loc00_YSigmaAngle1 1023 "SNA" ;
VAL_ 1012 Loc00_YSigmaAngle0 1023 "SNA" ;
VAL_ 1013 Loc00_YAngle3 65535 "SNA" ;
VAL_ 1013 Loc00_YAngle2 65535 "SNA" ;
VAL_ 1013 Loc00_YAngle1 65535 "SNA" ;
VAL_ 1013 Loc00_YAngle0 65535 "SNA" ;
VAL_ 1014 Loc00_Power4 255 "SNA" ;
VAL_ 1014 Loc00_Power3 255 "SNA" ;
VAL_ 1014 Loc00_Power2 255 "SNA" ;
VAL_ 1014 Loc00_Power1 255 "SNA" ;
VAL_ 1014 Loc00_Power0 255 "SNA" ;
VAL_ 1014 Loc00_YAngle4 65535 "SNA" ;
VAL_ 1016 Loc01_YSigmaAngle4 1023 "SNA" ;
VAL_ 1016 Loc01_YSigmaAngle3 1023 "SNA" ;
VAL_ 1016 Loc01_YSigmaAngle2 1023 "SNA" ;
VAL_ 1016 Loc01_YSigmaAngle1 1023 "SNA" ;
VAL_ 1016 Loc01_YSigmaAngle0 1023 "SNA" ;
VAL_ 1017 Loc01_YAngle3 65535 "SNA" ;
VAL_ 1017 Loc01_YAngle2 65535 "SNA" ;
VAL_ 1017 Loc01_YAngle1 65535 "SNA" ;
VAL_ 1017 Loc01_YAngle0 65535 "SNA" ;
VAL_ 1018 Loc01_Power4 255 "SNA" ;
VAL_ 1018 Loc01_Power3 255 "SNA" ;
VAL_ 1018 Loc01_Power2 255 "SNA" ;
VAL_ 1018 Loc01_Power1 255 "SNA" ;
VAL_ 1018 Loc01_Power0 255 "SNA" ;
VAL_ 1018 Loc01_YAngle4 65535 "SNA" ;
VAL_ 1020 Loc02_YSigmaAngle4 1023 "SNA" ;
VAL_ 1020 Loc02_YSigmaAngle3 1023 "SNA" ;
VAL_ 1020 Loc02_YSigmaAngle2 1023 "SNA" ;
VAL_ 1020 Loc02_YSigmaAngle1 1023 "SNA" ;
VAL_ 1020 Loc02_YSigmaAngle0 1023 "SNA" ;
VAL_ 1021 Loc02_YAngle3 65535 "SNA" ;
VAL_ 1021 Loc02_YAngle2 65535 "SNA" ;
VAL_ 1021 Loc02_YAngle1 65535 "SNA" ;
VAL_ 1021 Loc02_YAngle0 65535 "SNA" ;
VAL_ 1022 Loc02_Power4 255 "SNA" ;
VAL_ 1022 Loc02_Power3 255 "SNA" ;
VAL_ 1022 Loc02_Power2 255 "SNA" ;
VAL_ 1022 Loc02_Power1 255 "SNA" ;
VAL_ 1022 Loc02_Power0 255 "SNA" ;
VAL_ 1022 Loc02_YAngle4 65535 "SNA" ;
VAL_ 1024 Loc03_YSigmaAngle4 1023 "SNA" ;
VAL_ 1024 Loc03_YSigmaAngle3 1023 "SNA" ;
VAL_ 1024 Loc03_YSigmaAngle2 1023 "SNA" ;
VAL_ 1024 Loc03_YSigmaAngle1 1023 "SNA" ;
VAL_ 1024 Loc03_YSigmaAngle0 1023 "SNA" ;
VAL_ 1025 Loc03_YAngle3 65535 "SNA" ;
VAL_ 1025 Loc03_YAngle2 65535 "SNA" ;
VAL_ 1025 Loc03_YAngle1 65535 "SNA" ;
VAL_ 1025 Loc03_YAngle0 65535 "SNA" ;
VAL_ 1026 Loc03_Power4 255 "SNA" ;
VAL_ 1026 Loc03_Power3 255 "SNA" ;
VAL_ 1026 Loc03_Power2 255 "SNA" ;
VAL_ 1026 Loc03_Power1 255 "SNA" ;
VAL_ 1026 Loc03_Power0 255 "SNA" ;
VAL_ 1026 Loc03_YAngle4 65535 "SNA" ;
VAL_ 1028 Loc04_YSigmaAngle4 1023 "SNA" ;
VAL_ 1028 Loc04_YSigmaAngle3 1023 "SNA" ;
VAL_ 1028 Loc04_YSigmaAngle2 1023 "SNA" ;
VAL_ 1028 Loc04_YSigmaAngle1 1023 "SNA" ;
VAL_ 1028 Loc04_YSigmaAngle0 1023 "SNA" ;
VAL_ 1029 Loc04_YAngle3 65535 "SNA" ;
VAL_ 1029 Loc04_YAngle2 65535 "SNA" ;
VAL_ 1029 Loc04_YAngle1 65535 "SNA" ;
VAL_ 1029 Loc04_YAngle0 65535 "SNA" ;
VAL_ 1030 Loc04_Power4 255 "SNA" ;
VAL_ 1030 Loc04_Power3 255 "SNA" ;
VAL_ 1030 Loc04_Power2 255 "SNA" ;
VAL_ 1030 Loc04_Power1 255 "SNA" ;
VAL_ 1030 Loc04_Power0 255 "SNA" ;
VAL_ 1030 Loc04_YAngle4 65535 "SNA" ;
VAL_ 1032 Loc05_YSigmaAngle4 1023 "SNA" ;
VAL_ 1032 Loc05_YSigmaAngle3 1023 "SNA" ;
VAL_ 1032 Loc05_YSigmaAngle2 1023 "SNA" ;
VAL_ 1032 Loc05_YSigmaAngle1 1023 "SNA" ;
VAL_ 1032 Loc05_YSigmaAngle0 1023 "SNA" ;
VAL_ 1033 Loc05_YAngle3 65535 "SNA" ;
VAL_ 1033 Loc05_YAngle2 65535 "SNA" ;
VAL_ 1033 Loc05_YAngle1 65535 "SNA" ;
VAL_ 1033 Loc05_YAngle0 65535 "SNA" ;
VAL_ 1034 Loc05_Power4 255 "SNA" ;
VAL_ 1034 Loc05_Power3 255 "SNA" ;
VAL_ 1034 Loc05_Power2 255 "SNA" ;
VAL_ 1034 Loc05_Power1 255 "SNA" ;
VAL_ 1034 Loc05_Power0 255 "SNA" ;
VAL_ 1034 Loc05_YAngle4 65535 "SNA" ;
VAL_ 1036 Loc06_YSigmaAngle4 1023 "SNA" ;
VAL_ 1036 Loc06_YSigmaAngle3 1023 "SNA" ;
VAL_ 1036 Loc06_YSigmaAngle2 1023 "SNA" ;
VAL_ 1036 Loc06_YSigmaAngle1 1023 "SNA" ;
VAL_ 1036 Loc06_YSigmaAngle0 1023 "SNA" ;
VAL_ 1037 Loc06_YAngle3 65535 "SNA" ;
VAL_ 1037 Loc06_YAngle2 65535 "SNA" ;
VAL_ 1037 Loc06_YAngle1 65535 "SNA" ;
VAL_ 1037 Loc06_YAngle0 65535 "SNA" ;
VAL_ 1038 Loc06_Power4 255 "SNA" ;
VAL_ 1038 Loc06_Power3 255 "SNA" ;
VAL_ 1038 Loc06_Power2 255 "SNA" ;
VAL_ 1038 Loc06_Power1 255 "SNA" ;
VAL_ 1038 Loc06_Power0 255 "SNA" ;
VAL_ 1038 Loc06_YAngle4 65535 "SNA" ;
VAL_ 1040 Loc07_YSigmaAngle4 1023 "SNA" ;
VAL_ 1040 Loc07_YSigmaAngle3 1023 "SNA" ;
VAL_ 1040 Loc07_YSigmaAngle2 1023 "SNA" ;
VAL_ 1040 Loc07_YSigmaAngle1 1023 "SNA" ;
VAL_ 1040 Loc07_YSigmaAngle0 1023 "SNA" ;
VAL_ 1041 Loc07_YAngle3 65535 "SNA" ;
VAL_ 1041 Loc07_YAngle2 65535 "SNA" ;
VAL_ 1041 Loc07_YAngle1 65535 "SNA" ;
VAL_ 1041 Loc07_YAngle0 65535 "SNA" ;
VAL_ 1042 Loc07_Power4 255 "SNA" ;
VAL_ 1042 Loc07_Power3 255 "SNA" ;
VAL_ 1042 Loc07_Power2 255 "SNA" ;
VAL_ 1042 Loc07_Power1 255 "SNA" ;
VAL_ 1042 Loc07_Power0 255 "SNA" ;
VAL_ 1042 Loc07_YAngle4 65535 "SNA" ;
VAL_ 1044 Loc08_YSigmaAngle4 1023 "SNA" ;
VAL_ 1044 Loc08_YSigmaAngle3 1023 "SNA" ;
VAL_ 1044 Loc08_YSigmaAngle2 1023 "SNA" ;
VAL_ 1044 Loc08_YSigmaAngle1 1023 "SNA" ;
VAL_ 1044 Loc08_YSigmaAngle0 1023 "SNA" ;
VAL_ 1045 Loc08_YAngle3 65535 "SNA" ;
VAL_ 1045 Loc08_YAngle2 65535 "SNA" ;
VAL_ 1045 Loc08_YAngle1 65535 "SNA" ;
VAL_ 1045 Loc08_YAngle0 65535 "SNA" ;
VAL_ 1046 Loc08_Power4 255 "SNA" ;
VAL_ 1046 Loc08_Power3 255 "SNA" ;
VAL_ 1046 Loc08_Power2 255 "SNA" ;
VAL_ 1046 Loc08_Power1 255 "SNA" ;
VAL_ 1046 Loc08_Power0 255 "SNA" ;
VAL_ 1046 Loc08_YAngle4 65535 "SNA" ;
VAL_ 1048 Loc09_YSigmaAngle4 1023 "SNA" ;
VAL_ 1048 Loc09_YSigmaAngle3 1023 "SNA" ;
VAL_ 1048 Loc09_YSigmaAngle2 1023 "SNA" ;
VAL_ 1048 Loc09_YSigmaAngle1 1023 "SNA" ;
VAL_ 1048 Loc09_YSigmaAngle0 1023 "SNA" ;
VAL_ 1049 Loc09_YAngle3 65535 "SNA" ;
VAL_ 1049 Loc09_YAngle2 65535 "SNA" ;
VAL_ 1049 Loc09_YAngle1 65535 "SNA" ;
VAL_ 1049 Loc09_YAngle0 65535 "SNA" ;
VAL_ 1050 Loc09_Power4 255 "SNA" ;
VAL_ 1050 Loc09_Power3 255 "SNA" ;
VAL_ 1050 Loc09_Power2 255 "SNA" ;
VAL_ 1050 Loc09_Power1 255 "SNA" ;
VAL_ 1050 Loc09_Power0 255 "SNA" ;
VAL_ 1050 Loc09_YAngle4 65535 "SNA" ;
VAL_ 1052 Loc10_YSigmaAngle4 1023 "SNA" ;
VAL_ 1052 Loc10_YSigmaAngle3 1023 "SNA" ;
VAL_ 1052 Loc10_YSigmaAngle2 1023 "SNA" ;
VAL_ 1052 Loc10_YSigmaAngle1 1023 "SNA" ;
VAL_ 1052 Loc10_YSigmaAngle0 1023 "SNA" ;
VAL_ 1053 Loc10_YAngle3 65535 "SNA" ;
VAL_ 1053 Loc10_YAngle2 65535 "SNA" ;
VAL_ 1053 Loc10_YAngle1 65535 "SNA" ;
VAL_ 1053 Loc10_YAngle0 65535 "SNA" ;
VAL_ 1054 Loc10_Power4 255 "SNA" ;
VAL_ 1054 Loc10_Power3 255 "SNA" ;
VAL_ 1054 Loc10_Power2 255 "SNA" ;
VAL_ 1054 Loc10_Power1 255 "SNA" ;
VAL_ 1054 Loc10_Power0 255 "SNA" ;
VAL_ 1054 Loc10_YAngle4 65535 "SNA" ;
VAL_ 1056 Loc11_YSigmaAngle4 1023 "SNA" ;
VAL_ 1056 Loc11_YSigmaAngle3 1023 "SNA" ;
VAL_ 1056 Loc11_YSigmaAngle2 1023 "SNA" ;
VAL_ 1056 Loc11_YSigmaAngle1 1023 "SNA" ;
VAL_ 1056 Loc11_YSigmaAngle0 1023 "SNA" ;
VAL_ 1057 Loc11_YAngle3 65535 "SNA" ;
VAL_ 1057 Loc11_YAngle2 65535 "SNA" ;
VAL_ 1057 Loc11_YAngle1 65535 "SNA" ;
VAL_ 1057 Loc11_YAngle0 65535 "SNA" ;
VAL_ 1058 Loc11_Power4 255 "SNA" ;
VAL_ 1058 Loc11_Power3 255 "SNA" ;
VAL_ 1058 Loc11_Power2 255 "SNA" ;
VAL_ 1058 Loc11_Power1 255 "SNA" ;
VAL_ 1058 Loc11_Power0 255 "SNA" ;
VAL_ 1058 Loc11_YAngle4 65535 "SNA" ;
VAL_ 1060 Loc12_YSigmaAngle4 1023 "SNA" ;
VAL_ 1060 Loc12_YSigmaAngle3 1023 "SNA" ;
VAL_ 1060 Loc12_YSigmaAngle2 1023 "SNA" ;
VAL_ 1060 Loc12_YSigmaAngle1 1023 "SNA" ;
VAL_ 1060 Loc12_YSigmaAngle0 1023 "SNA" ;
VAL_ 1061 Loc12_YAngle3 65535 "SNA" ;
VAL_ 1061 Loc12_YAngle2 65535 "SNA" ;
VAL_ 1061 Loc12_YAngle1 65535 "SNA" ;
VAL_ 1061 Loc12_YAngle0 65535 "SNA" ;
VAL_ 1062 Loc12_Power4 255 "SNA" ;
VAL_ 1062 Loc12_Power3 255 "SNA" ;
VAL_ 1062 Loc12_Power2 255 "SNA" ;
VAL_ 1062 Loc12_Power1 255 "SNA" ;
VAL_ 1062 Loc12_Power0 255 "SNA" ;
VAL_ 1062 Loc12_YAngle4 65535 "SNA" ;
VAL_ 1064 Loc13_YSigmaAngle4 1023 "SNA" ;
VAL_ 1064 Loc13_YSigmaAngle3 1023 "SNA" ;
VAL_ 1064 Loc13_YSigmaAngle2 1023 "SNA" ;
VAL_ 1064 Loc13_YSigmaAngle1 1023 "SNA" ;
VAL_ 1064 Loc13_YSigmaAngle0 1023 "SNA" ;
VAL_ 1065 Loc13_YAngle3 65535 "SNA" ;
VAL_ 1065 Loc13_YAngle2 65535 "SNA" ;
VAL_ 1065 Loc13_YAngle1 65535 "SNA" ;
VAL_ 1065 Loc13_YAngle0 65535 "SNA" ;
VAL_ 1066 Loc13_Power4 255 "SNA" ;
VAL_ 1066 Loc13_Power3 255 "SNA" ;
VAL_ 1066 Loc13_Power2 255 "SNA" ;
VAL_ 1066 Loc13_Power1 255 "SNA" ;
VAL_ 1066 Loc13_Power0 255 "SNA" ;
VAL_ 1066 Loc13_YAngle4 65535 "SNA" ;
VAL_ 1068 Loc14_YSigmaAngle4 1023 "SNA" ;
VAL_ 1068 Loc14_YSigmaAngle3 1023 "SNA" ;
VAL_ 1068 Loc14_YSigmaAngle2 1023 "SNA" ;
VAL_ 1068 Loc14_YSigmaAngle1 1023 "SNA" ;
VAL_ 1068 Loc14_YSigmaAngle0 1023 "SNA" ;
VAL_ 1069 Loc14_YAngle3 65535 "SNA" ;
VAL_ 1069 Loc14_YAngle2 65535 "SNA" ;
VAL_ 1069 Loc14_YAngle1 65535 "SNA" ;
VAL_ 1069 Loc14_YAngle0 65535 "SNA" ;
VAL_ 1070 Loc14_Power4 255 "SNA" ;
VAL_ 1070 Loc14_Power3 255 "SNA" ;
VAL_ 1070 Loc14_Power2 255 "SNA" ;
VAL_ 1070 Loc14_Power1 255 "SNA" ;
VAL_ 1070 Loc14_Power0 255 "SNA" ;
VAL_ 1070 Loc14_YAngle4 65535 "SNA" ;
VAL_ 1072 Loc15_YSigmaAngle4 1023 "SNA" ;
VAL_ 1072 Loc15_YSigmaAngle3 1023 "SNA" ;
VAL_ 1072 Loc15_YSigmaAngle2 1023 "SNA" ;
VAL_ 1072 Loc15_YSigmaAngle1 1023 "SNA" ;
VAL_ 1072 Loc15_YSigmaAngle0 1023 "SNA" ;
VAL_ 1073 Loc15_YAngle3 65535 "SNA" ;
VAL_ 1073 Loc15_YAngle2 65535 "SNA" ;
VAL_ 1073 Loc15_YAngle1 65535 "SNA" ;
VAL_ 1073 Loc15_YAngle0 65535 "SNA" ;
VAL_ 1074 Loc15_Power4 255 "SNA" ;
VAL_ 1074 Loc15_Power3 255 "SNA" ;
VAL_ 1074 Loc15_Power2 255 "SNA" ;
VAL_ 1074 Loc15_Power1 255 "SNA" ;
VAL_ 1074 Loc15_Power0 255 "SNA" ;
VAL_ 1074 Loc15_YAngle4 65535 "SNA" ;
VAL_ 1076 Loc16_YSigmaAngle4 1023 "SNA" ;
VAL_ 1076 Loc16_YSigmaAngle3 1023 "SNA" ;
VAL_ 1076 Loc16_YSigmaAngle2 1023 "SNA" ;
VAL_ 1076 Loc16_YSigmaAngle1 1023 "SNA" ;
VAL_ 1076 Loc16_YSigmaAngle0 1023 "SNA" ;
VAL_ 1077 Loc16_YAngle3 65535 "SNA" ;
VAL_ 1077 Loc16_YAngle2 65535 "SNA" ;
VAL_ 1077 Loc16_YAngle1 65535 "SNA" ;
VAL_ 1077 Loc16_YAngle0 65535 "SNA" ;
VAL_ 1078 Loc16_Power4 255 "SNA" ;
VAL_ 1078 Loc16_Power3 255 "SNA" ;
VAL_ 1078 Loc16_Power2 255 "SNA" ;
VAL_ 1078 Loc16_Power1 255 "SNA" ;
VAL_ 1078 Loc16_Power0 255 "SNA" ;
VAL_ 1078 Loc16_YAngle4 65535 "SNA" ;
VAL_ 1080 Loc17_YSigmaAngle4 1023 "SNA" ;
VAL_ 1080 Loc17_YSigmaAngle3 1023 "SNA" ;
VAL_ 1080 Loc17_YSigmaAngle2 1023 "SNA" ;
VAL_ 1080 Loc17_YSigmaAngle1 1023 "SNA" ;
VAL_ 1080 Loc17_YSigmaAngle0 1023 "SNA" ;
VAL_ 1081 Loc17_YAngle3 65535 "SNA" ;
VAL_ 1081 Loc17_YAngle2 65535 "SNA" ;
VAL_ 1081 Loc17_YAngle1 65535 "SNA" ;
VAL_ 1081 Loc17_YAngle0 65535 "SNA" ;
VAL_ 1082 Loc17_Power4 255 "SNA" ;
VAL_ 1082 Loc17_Power3 255 "SNA" ;
VAL_ 1082 Loc17_Power2 255 "SNA" ;
VAL_ 1082 Loc17_Power1 255 "SNA" ;
VAL_ 1082 Loc17_Power0 255 "SNA" ;
VAL_ 1082 Loc17_YAngle4 65535 "SNA" ;
VAL_ 1084 Loc18_YSigmaAngle4 1023 "SNA" ;
VAL_ 1084 Loc18_YSigmaAngle3 1023 "SNA" ;
VAL_ 1084 Loc18_YSigmaAngle2 1023 "SNA" ;
VAL_ 1084 Loc18_YSigmaAngle1 1023 "SNA" ;
VAL_ 1084 Loc18_YSigmaAngle0 1023 "SNA" ;
VAL_ 1085 Loc18_YAngle3 65535 "SNA" ;
VAL_ 1085 Loc18_YAngle2 65535 "SNA" ;
VAL_ 1085 Loc18_YAngle1 65535 "SNA" ;
VAL_ 1085 Loc18_YAngle0 65535 "SNA" ;
VAL_ 1086 Loc18_Power4 255 "SNA" ;
VAL_ 1086 Loc18_Power3 255 "SNA" ;
VAL_ 1086 Loc18_Power2 255 "SNA" ;
VAL_ 1086 Loc18_Power1 255 "SNA" ;
VAL_ 1086 Loc18_Power0 255 "SNA" ;
VAL_ 1086 Loc18_YAngle4 65535 "SNA" ;
VAL_ 1088 Loc19_YSigmaAngle4 1023 "SNA" ;
VAL_ 1088 Loc19_YSigmaAngle3 1023 "SNA" ;
VAL_ 1088 Loc19_YSigmaAngle2 1023 "SNA" ;
VAL_ 1088 Loc19_YSigmaAngle1 1023 "SNA" ;
VAL_ 1088 Loc19_YSigmaAngle0 1023 "SNA" ;
VAL_ 1089 Loc19_YAngle3 65535 "SNA" ;
VAL_ 1089 Loc19_YAngle2 65535 "SNA" ;
VAL_ 1089 Loc19_YAngle1 65535 "SNA" ;
VAL_ 1089 Loc19_YAngle0 65535 "SNA" ;
VAL_ 1090 Loc19_Power4 255 "SNA" ;
VAL_ 1090 Loc19_Power3 255 "SNA" ;
VAL_ 1090 Loc19_Power2 255 "SNA" ;
VAL_ 1090 Loc19_Power1 255 "SNA" ;
VAL_ 1090 Loc19_Power0 255 "SNA" ;
VAL_ 1090 Loc19_YAngle4 65535 "SNA" ;
VAL_ 1092 Loc20_YSigmaAngle4 1023 "SNA" ;
VAL_ 1092 Loc20_YSigmaAngle3 1023 "SNA" ;
VAL_ 1092 Loc20_YSigmaAngle2 1023 "SNA" ;
VAL_ 1092 Loc20_YSigmaAngle1 1023 "SNA" ;
VAL_ 1092 Loc20_YSigmaAngle0 1023 "SNA" ;
VAL_ 1093 Loc20_YAngle3 65535 "SNA" ;
VAL_ 1093 Loc20_YAngle2 65535 "SNA" ;
VAL_ 1093 Loc20_YAngle1 65535 "SNA" ;
VAL_ 1093 Loc20_YAngle0 65535 "SNA" ;
VAL_ 1094 Loc20_Power4 255 "SNA" ;
VAL_ 1094 Loc20_Power3 255 "SNA" ;
VAL_ 1094 Loc20_Power2 255 "SNA" ;
VAL_ 1094 Loc20_Power1 255 "SNA" ;
VAL_ 1094 Loc20_Power0 255 "SNA" ;
VAL_ 1094 Loc20_YAngle4 65535 "SNA" ;
VAL_ 1096 Loc21_YSigmaAngle4 1023 "SNA" ;
VAL_ 1096 Loc21_YSigmaAngle3 1023 "SNA" ;
VAL_ 1096 Loc21_YSigmaAngle2 1023 "SNA" ;
VAL_ 1096 Loc21_YSigmaAngle1 1023 "SNA" ;
VAL_ 1096 Loc21_YSigmaAngle0 1023 "SNA" ;
VAL_ 1097 Loc21_YAngle3 65535 "SNA" ;
VAL_ 1097 Loc21_YAngle2 65535 "SNA" ;
VAL_ 1097 Loc21_YAngle1 65535 "SNA" ;
VAL_ 1097 Loc21_YAngle0 65535 "SNA" ;
VAL_ 1098 Loc21_Power4 255 "SNA" ;
VAL_ 1098 Loc21_Power3 255 "SNA" ;
VAL_ 1098 Loc21_Power2 255 "SNA" ;
VAL_ 1098 Loc21_Power1 255 "SNA" ;
VAL_ 1098 Loc21_Power0 255 "SNA" ;
VAL_ 1098 Loc21_YAngle4 65535 "SNA" ;
VAL_ 1100 Loc22_YSigmaAngle4 1023 "SNA" ;
VAL_ 1100 Loc22_YSigmaAngle3 1023 "SNA" ;
VAL_ 1100 Loc22_YSigmaAngle2 1023 "SNA" ;
VAL_ 1100 Loc22_YSigmaAngle1 1023 "SNA" ;
VAL_ 1100 Loc22_YSigmaAngle0 1023 "SNA" ;
VAL_ 1101 Loc22_YAngle3 65535 "SNA" ;
VAL_ 1101 Loc22_YAngle2 65535 "SNA" ;
VAL_ 1101 Loc22_YAngle1 65535 "SNA" ;
VAL_ 1101 Loc22_YAngle0 65535 "SNA" ;
VAL_ 1102 Loc22_Power4 255 "SNA" ;
VAL_ 1102 Loc22_Power3 255 "SNA" ;
VAL_ 1102 Loc22_Power2 255 "SNA" ;
VAL_ 1102 Loc22_Power1 255 "SNA" ;
VAL_ 1102 Loc22_Power0 255 "SNA" ;
VAL_ 1102 Loc22_YAngle4 65535 "SNA" ;
VAL_ 1104 Loc23_YSigmaAngle4 1023 "SNA" ;
VAL_ 1104 Loc23_YSigmaAngle3 1023 "SNA" ;
VAL_ 1104 Loc23_YSigmaAngle2 1023 "SNA" ;
VAL_ 1104 Loc23_YSigmaAngle1 1023 "SNA" ;
VAL_ 1104 Loc23_YSigmaAngle0 1023 "SNA" ;
VAL_ 1105 Loc23_YAngle3 65535 "SNA" ;
VAL_ 1105 Loc23_YAngle2 65535 "SNA" ;
VAL_ 1105 Loc23_YAngle1 65535 "SNA" ;
VAL_ 1105 Loc23_YAngle0 65535 "SNA" ;
VAL_ 1106 Loc23_Power4 255 "SNA" ;
VAL_ 1106 Loc23_Power3 255 "SNA" ;
VAL_ 1106 Loc23_Power2 255 "SNA" ;
VAL_ 1106 Loc23_Power1 255 "SNA" ;
VAL_ 1106 Loc23_Power0 255 "SNA" ;
VAL_ 1106 Loc23_YAngle4 65535 "SNA" ;
VAL_ 1108 Loc24_YSigmaAngle4 1023 "SNA" ;
VAL_ 1108 Loc24_YSigmaAngle3 1023 "SNA" ;
VAL_ 1108 Loc24_YSigmaAngle2 1023 "SNA" ;
VAL_ 1108 Loc24_YSigmaAngle1 1023 "SNA" ;
VAL_ 1108 Loc24_YSigmaAngle0 1023 "SNA" ;
VAL_ 1109 Loc24_YAngle3 65535 "SNA" ;
VAL_ 1109 Loc24_YAngle2 65535 "SNA" ;
VAL_ 1109 Loc24_YAngle1 65535 "SNA" ;
VAL_ 1109 Loc24_YAngle0 65535 "SNA" ;
VAL_ 1110 Loc24_Power4 255 "SNA" ;
VAL_ 1110 Loc24_Power3 255 "SNA" ;
VAL_ 1110 Loc24_Power2 255 "SNA" ;
VAL_ 1110 Loc24_Power1 255 "SNA" ;
VAL_ 1110 Loc24_Power0 255 "SNA" ;
VAL_ 1110 Loc24_YAngle4 65535 "SNA" ;
VAL_ 1112 Loc25_YSigmaAngle4 1023 "SNA" ;
VAL_ 1112 Loc25_YSigmaAngle3 1023 "SNA" ;
VAL_ 1112 Loc25_YSigmaAngle2 1023 "SNA" ;
VAL_ 1112 Loc25_YSigmaAngle1 1023 "SNA" ;
VAL_ 1112 Loc25_YSigmaAngle0 1023 "SNA" ;
VAL_ 1113 Loc25_YAngle3 65535 "SNA" ;
VAL_ 1113 Loc25_YAngle2 65535 "SNA" ;
VAL_ 1113 Loc25_YAngle1 65535 "SNA" ;
VAL_ 1113 Loc25_YAngle0 65535 "SNA" ;
VAL_ 1114 Loc25_Power4 255 "SNA" ;
VAL_ 1114 Loc25_Power3 255 "SNA" ;
VAL_ 1114 Loc25_Power2 255 "SNA" ;
VAL_ 1114 Loc25_Power1 255 "SNA" ;
VAL_ 1114 Loc25_Power0 255 "SNA" ;
VAL_ 1114 Loc25_YAngle4 65535 "SNA" ;
VAL_ 1116 Loc26_YSigmaAngle4 1023 "SNA" ;
VAL_ 1116 Loc26_YSigmaAngle3 1023 "SNA" ;
VAL_ 1116 Loc26_YSigmaAngle2 1023 "SNA" ;
VAL_ 1116 Loc26_YSigmaAngle1 1023 "SNA" ;
VAL_ 1116 Loc26_YSigmaAngle0 1023 "SNA" ;
VAL_ 1117 Loc26_YAngle3 65535 "SNA" ;
VAL_ 1117 Loc26_YAngle2 65535 "SNA" ;
VAL_ 1117 Loc26_YAngle1 65535 "SNA" ;
VAL_ 1117 Loc26_YAngle0 65535 "SNA" ;
VAL_ 1118 Loc26_Power4 255 "SNA" ;
VAL_ 1118 Loc26_Power3 255 "SNA" ;
VAL_ 1118 Loc26_Power2 255 "SNA" ;
VAL_ 1118 Loc26_Power1 255 "SNA" ;
VAL_ 1118 Loc26_Power0 255 "SNA" ;
VAL_ 1118 Loc26_YAngle4 65535 "SNA" ;
VAL_ 1120 Loc27_YSigmaAngle4 1023 "SNA" ;
VAL_ 1120 Loc27_YSigmaAngle3 1023 "SNA" ;
VAL_ 1120 Loc27_YSigmaAngle2 1023 "SNA" ;
VAL_ 1120 Loc27_YSigmaAngle1 1023 "SNA" ;
VAL_ 1120 Loc27_YSigmaAngle0 1023 "SNA" ;
VAL_ 1121 Loc27_YAngle3 65535 "SNA" ;
VAL_ 1121 Loc27_YAngle2 65535 "SNA" ;
VAL_ 1121 Loc27_YAngle1 65535 "SNA" ;
VAL_ 1121 Loc27_YAngle0 65535 "SNA" ;
VAL_ 1122 Loc27_Power4 255 "SNA" ;
VAL_ 1122 Loc27_Power3 255 "SNA" ;
VAL_ 1122 Loc27_Power2 255 "SNA" ;
VAL_ 1122 Loc27_Power1 255 "SNA" ;
VAL_ 1122 Loc27_Power0 255 "SNA" ;
VAL_ 1122 Loc27_YAngle4 65535 "SNA" ;
VAL_ 1124 Loc28_YSigmaAngle4 1023 "SNA" ;
VAL_ 1124 Loc28_YSigmaAngle3 1023 "SNA" ;
VAL_ 1124 Loc28_YSigmaAngle2 1023 "SNA" ;
VAL_ 1124 Loc28_YSigmaAngle1 1023 "SNA" ;
VAL_ 1124 Loc28_YSigmaAngle0 1023 "SNA" ;
VAL_ 1125 Loc28_YAngle3 65535 "SNA" ;
VAL_ 1125 Loc28_YAngle2 65535 "SNA" ;
VAL_ 1125 Loc28_YAngle1 65535 "SNA" ;
VAL_ 1125 Loc28_YAngle0 65535 "SNA" ;
VAL_ 1126 Loc28_Power4 255 "SNA" ;
VAL_ 1126 Loc28_Power3 255 "SNA" ;
VAL_ 1126 Loc28_Power2 255 "SNA" ;
VAL_ 1126 Loc28_Power1 255 "SNA" ;
VAL_ 1126 Loc28_Power0 255 "SNA" ;
VAL_ 1126 Loc28_YAngle4 65535 "SNA" ;
VAL_ 1128 Loc29_YSigmaAngle4 1023 "SNA" ;
VAL_ 1128 Loc29_YSigmaAngle3 1023 "SNA" ;
VAL_ 1128 Loc29_YSigmaAngle2 1023 "SNA" ;
VAL_ 1128 Loc29_YSigmaAngle1 1023 "SNA" ;
VAL_ 1128 Loc29_YSigmaAngle0 1023 "SNA" ;
VAL_ 1129 Loc29_YAngle3 65535 "SNA" ;
VAL_ 1129 Loc29_YAngle2 65535 "SNA" ;
VAL_ 1129 Loc29_YAngle1 65535 "SNA" ;
VAL_ 1129 Loc29_YAngle0 65535 "SNA" ;
VAL_ 1130 Loc29_Power4 255 "SNA" ;
VAL_ 1130 Loc29_Power3 255 "SNA" ;
VAL_ 1130 Loc29_Power2 255 "SNA" ;
VAL_ 1130 Loc29_Power1 255 "SNA" ;
VAL_ 1130 Loc29_Power0 255 "SNA" ;
VAL_ 1130 Loc29_YAngle4 65535 "SNA" ;
VAL_ 1132 Loc30_YSigmaAngle4 1023 "SNA" ;
VAL_ 1132 Loc30_YSigmaAngle3 1023 "SNA" ;
VAL_ 1132 Loc30_YSigmaAngle2 1023 "SNA" ;
VAL_ 1132 Loc30_YSigmaAngle1 1023 "SNA" ;
VAL_ 1132 Loc30_YSigmaAngle0 1023 "SNA" ;
VAL_ 1133 Loc30_YAngle3 65535 "SNA" ;
VAL_ 1133 Loc30_YAngle2 65535 "SNA" ;
VAL_ 1133 Loc30_YAngle1 65535 "SNA" ;
VAL_ 1133 Loc30_YAngle0 65535 "SNA" ;
VAL_ 1134 Loc30_Power4 255 "SNA" ;
VAL_ 1134 Loc30_Power3 255 "SNA" ;
VAL_ 1134 Loc30_Power2 255 "SNA" ;
VAL_ 1134 Loc30_Power1 255 "SNA" ;
VAL_ 1134 Loc30_Power0 255 "SNA" ;
VAL_ 1134 Loc30_YAngle4 65535 "SNA" ;
VAL_ 1136 Loc31_YSigmaAngle4 1023 "SNA" ;
VAL_ 1136 Loc31_YSigmaAngle3 1023 "SNA" ;
VAL_ 1136 Loc31_YSigmaAngle2 1023 "SNA" ;
VAL_ 1136 Loc31_YSigmaAngle1 1023 "SNA" ;
VAL_ 1136 Loc31_YSigmaAngle0 1023 "SNA" ;
VAL_ 1137 Loc31_YAngle3 65535 "SNA" ;
VAL_ 1137 Loc31_YAngle2 65535 "SNA" ;
VAL_ 1137 Loc31_YAngle1 65535 "SNA" ;
VAL_ 1137 Loc31_YAngle0 65535 "SNA" ;
VAL_ 1138 Loc31_Power4 255 "SNA" ;
VAL_ 1138 Loc31_Power3 255 "SNA" ;
VAL_ 1138 Loc31_Power2 255 "SNA" ;
VAL_ 1138 Loc31_Power1 255 "SNA" ;
VAL_ 1138 Loc31_Power0 255 "SNA" ;
VAL_ 1138 Loc31_YAngle4 65535 "SNA" ;
VAL_ 1140 Loc32_YSigmaAngle4 1023 "SNA" ;
VAL_ 1140 Loc32_YSigmaAngle3 1023 "SNA" ;
VAL_ 1140 Loc32_YSigmaAngle2 1023 "SNA" ;
VAL_ 1140 Loc32_YSigmaAngle1 1023 "SNA" ;
VAL_ 1140 Loc32_YSigmaAngle0 1023 "SNA" ;
VAL_ 1141 Loc32_YAngle3 65535 "SNA" ;
VAL_ 1141 Loc32_YAngle2 65535 "SNA" ;
VAL_ 1141 Loc32_YAngle1 65535 "SNA" ;
VAL_ 1141 Loc32_YAngle0 65535 "SNA" ;
VAL_ 1142 Loc32_Power4 255 "SNA" ;
VAL_ 1142 Loc32_Power3 255 "SNA" ;
VAL_ 1142 Loc32_Power2 255 "SNA" ;
VAL_ 1142 Loc32_Power1 255 "SNA" ;
VAL_ 1142 Loc32_Power0 255 "SNA" ;
VAL_ 1142 Loc32_YAngle4 65535 "SNA" ;
VAL_ 1144 Loc33_YSigmaAngle4 1023 "SNA" ;
VAL_ 1144 Loc33_YSigmaAngle3 1023 "SNA" ;
VAL_ 1144 Loc33_YSigmaAngle2 1023 "SNA" ;
VAL_ 1144 Loc33_YSigmaAngle1 1023 "SNA" ;
VAL_ 1144 Loc33_YSigmaAngle0 1023 "SNA" ;
VAL_ 1145 Loc33_YAngle3 65535 "SNA" ;
VAL_ 1145 Loc33_YAngle2 65535 "SNA" ;
VAL_ 1145 Loc33_YAngle1 65535 "SNA" ;
VAL_ 1145 Loc33_YAngle0 65535 "SNA" ;
VAL_ 1146 Loc33_Power4 255 "SNA" ;
VAL_ 1146 Loc33_Power3 255 "SNA" ;
VAL_ 1146 Loc33_Power2 255 "SNA" ;
VAL_ 1146 Loc33_Power1 255 "SNA" ;
VAL_ 1146 Loc33_Power0 255 "SNA" ;
VAL_ 1146 Loc33_YAngle4 65535 "SNA" ;
VAL_ 1148 Loc34_YSigmaAngle4 1023 "SNA" ;
VAL_ 1148 Loc34_YSigmaAngle3 1023 "SNA" ;
VAL_ 1148 Loc34_YSigmaAngle2 1023 "SNA" ;
VAL_ 1148 Loc34_YSigmaAngle1 1023 "SNA" ;
VAL_ 1148 Loc34_YSigmaAngle0 1023 "SNA" ;
VAL_ 1149 Loc34_YAngle3 65535 "SNA" ;
VAL_ 1149 Loc34_YAngle2 65535 "SNA" ;
VAL_ 1149 Loc34_YAngle1 65535 "SNA" ;
VAL_ 1149 Loc34_YAngle0 65535 "SNA" ;
VAL_ 1150 Loc34_Power4 255 "SNA" ;
VAL_ 1150 Loc34_Power3 255 "SNA" ;
VAL_ 1150 Loc34_Power2 255 "SNA" ;
VAL_ 1150 Loc34_Power1 255 "SNA" ;
VAL_ 1150 Loc34_Power0 255 "SNA" ;
VAL_ 1150 Loc34_YAngle4 65535 "SNA" ;
VAL_ 1152 Loc35_YSigmaAngle4 1023 "SNA" ;
VAL_ 1152 Loc35_YSigmaAngle3 1023 "SNA" ;
VAL_ 1152 Loc35_YSigmaAngle2 1023 "SNA" ;
VAL_ 1152 Loc35_YSigmaAngle1 1023 "SNA" ;
VAL_ 1152 Loc35_YSigmaAngle0 1023 "SNA" ;
VAL_ 1153 Loc35_YAngle3 65535 "SNA" ;
VAL_ 1153 Loc35_YAngle2 65535 "SNA" ;
VAL_ 1153 Loc35_YAngle1 65535 "SNA" ;
VAL_ 1153 Loc35_YAngle0 65535 "SNA" ;
VAL_ 1154 Loc35_Power4 255 "SNA" ;
VAL_ 1154 Loc35_Power3 255 "SNA" ;
VAL_ 1154 Loc35_Power2 255 "SNA" ;
VAL_ 1154 Loc35_Power1 255 "SNA" ;
VAL_ 1154 Loc35_Power0 255 "SNA" ;
VAL_ 1154 Loc35_YAngle4 65535 "SNA" ;
VAL_ 1156 Loc36_YSigmaAngle4 1023 "SNA" ;
VAL_ 1156 Loc36_YSigmaAngle3 1023 "SNA" ;
VAL_ 1156 Loc36_YSigmaAngle2 1023 "SNA" ;
VAL_ 1156 Loc36_YSigmaAngle1 1023 "SNA" ;
VAL_ 1156 Loc36_YSigmaAngle0 1023 "SNA" ;
VAL_ 1157 Loc36_YAngle3 65535 "SNA" ;
VAL_ 1157 Loc36_YAngle2 65535 "SNA" ;
VAL_ 1157 Loc36_YAngle1 65535 "SNA" ;
VAL_ 1157 Loc36_YAngle0 65535 "SNA" ;
VAL_ 1158 Loc36_Power4 255 "SNA" ;
VAL_ 1158 Loc36_Power3 255 "SNA" ;
VAL_ 1158 Loc36_Power2 255 "SNA" ;
VAL_ 1158 Loc36_Power1 255 "SNA" ;
VAL_ 1158 Loc36_Power0 255 "SNA" ;
VAL_ 1158 Loc36_YAngle4 65535 "SNA" ;
VAL_ 1160 Loc37_YSigmaAngle4 1023 "SNA" ;
VAL_ 1160 Loc37_YSigmaAngle3 1023 "SNA" ;
VAL_ 1160 Loc37_YSigmaAngle2 1023 "SNA" ;
VAL_ 1160 Loc37_YSigmaAngle1 1023 "SNA" ;
VAL_ 1160 Loc37_YSigmaAngle0 1023 "SNA" ;
VAL_ 1161 Loc37_YAngle3 65535 "SNA" ;
VAL_ 1161 Loc37_YAngle2 65535 "SNA" ;
VAL_ 1161 Loc37_YAngle1 65535 "SNA" ;
VAL_ 1161 Loc37_YAngle0 65535 "SNA" ;
VAL_ 1162 Loc37_Power4 255 "SNA" ;
VAL_ 1162 Loc37_Power3 255 "SNA" ;
VAL_ 1162 Loc37_Power2 255 "SNA" ;
VAL_ 1162 Loc37_Power1 255 "SNA" ;
VAL_ 1162 Loc37_Power0 255 "SNA" ;
VAL_ 1162 Loc37_YAngle4 65535 "SNA" ;
VAL_ 1164 Loc38_YSigmaAngle4 1023 "SNA" ;
VAL_ 1164 Loc38_YSigmaAngle3 1023 "SNA" ;
VAL_ 1164 Loc38_YSigmaAngle2 1023 "SNA" ;
VAL_ 1164 Loc38_YSigmaAngle1 1023 "SNA" ;
VAL_ 1164 Loc38_YSigmaAngle0 1023 "SNA" ;
VAL_ 1165 Loc38_YAngle3 65535 "SNA" ;
VAL_ 1165 Loc38_YAngle2 65535 "SNA" ;
VAL_ 1165 Loc38_YAngle1 65535 "SNA" ;
VAL_ 1165 Loc38_YAngle0 65535 "SNA" ;
VAL_ 1166 Loc38_Power4 255 "SNA" ;
VAL_ 1166 Loc38_Power3 255 "SNA" ;
VAL_ 1166 Loc38_Power2 255 "SNA" ;
VAL_ 1166 Loc38_Power1 255 "SNA" ;
VAL_ 1166 Loc38_Power0 255 "SNA" ;
VAL_ 1166 Loc38_YAngle4 65535 "SNA" ;
VAL_ 1168 Loc39_YSigmaAngle4 1023 "SNA" ;
VAL_ 1168 Loc39_YSigmaAngle3 1023 "SNA" ;
VAL_ 1168 Loc39_YSigmaAngle2 1023 "SNA" ;
VAL_ 1168 Loc39_YSigmaAngle1 1023 "SNA" ;
VAL_ 1168 Loc39_YSigmaAngle0 1023 "SNA" ;
VAL_ 1169 Loc39_YAngle3 65535 "SNA" ;
VAL_ 1169 Loc39_YAngle2 65535 "SNA" ;
VAL_ 1169 Loc39_YAngle1 65535 "SNA" ;
VAL_ 1169 Loc39_YAngle0 65535 "SNA" ;
VAL_ 1170 Loc39_Power4 255 "SNA" ;
VAL_ 1170 Loc39_Power3 255 "SNA" ;
VAL_ 1170 Loc39_Power2 255 "SNA" ;
VAL_ 1170 Loc39_Power1 255 "SNA" ;
VAL_ 1170 Loc39_Power0 255 "SNA" ;
VAL_ 1170 Loc39_YAngle4 65535 "SNA" ;
VAL_ 1172 Loc40_YSigmaAngle4 1023 "SNA" ;
VAL_ 1172 Loc40_YSigmaAngle3 1023 "SNA" ;
VAL_ 1172 Loc40_YSigmaAngle2 1023 "SNA" ;
VAL_ 1172 Loc40_YSigmaAngle1 1023 "SNA" ;
VAL_ 1172 Loc40_YSigmaAngle0 1023 "SNA" ;
VAL_ 1173 Loc40_YAngle3 65535 "SNA" ;
VAL_ 1173 Loc40_YAngle2 65535 "SNA" ;
VAL_ 1173 Loc40_YAngle1 65535 "SNA" ;
VAL_ 1173 Loc40_YAngle0 65535 "SNA" ;
VAL_ 1174 Loc40_Power4 255 "SNA" ;
VAL_ 1174 Loc40_Power3 255 "SNA" ;
VAL_ 1174 Loc40_Power2 255 "SNA" ;
VAL_ 1174 Loc40_Power1 255 "SNA" ;
VAL_ 1174 Loc40_Power0 255 "SNA" ;
VAL_ 1174 Loc40_YAngle4 65535 "SNA" ;
VAL_ 1176 Loc41_YSigmaAngle4 1023 "SNA" ;
VAL_ 1176 Loc41_YSigmaAngle3 1023 "SNA" ;
VAL_ 1176 Loc41_YSigmaAngle2 1023 "SNA" ;
VAL_ 1176 Loc41_YSigmaAngle1 1023 "SNA" ;
VAL_ 1176 Loc41_YSigmaAngle0 1023 "SNA" ;
VAL_ 1177 Loc41_YAngle3 65535 "SNA" ;
VAL_ 1177 Loc41_YAngle2 65535 "SNA" ;
VAL_ 1177 Loc41_YAngle1 65535 "SNA" ;
VAL_ 1177 Loc41_YAngle0 65535 "SNA" ;
VAL_ 1178 Loc41_Power4 255 "SNA" ;
VAL_ 1178 Loc41_Power3 255 "SNA" ;
VAL_ 1178 Loc41_Power2 255 "SNA" ;
VAL_ 1178 Loc41_Power1 255 "SNA" ;
VAL_ 1178 Loc41_Power0 255 "SNA" ;
VAL_ 1178 Loc41_YAngle4 65535 "SNA" ;
VAL_ 1180 Loc42_YSigmaAngle4 1023 "SNA" ;
VAL_ 1180 Loc42_YSigmaAngle3 1023 "SNA" ;
VAL_ 1180 Loc42_YSigmaAngle2 1023 "SNA" ;
VAL_ 1180 Loc42_YSigmaAngle1 1023 "SNA" ;
VAL_ 1180 Loc42_YSigmaAngle0 1023 "SNA" ;
VAL_ 1181 Loc42_YAngle3 65535 "SNA" ;
VAL_ 1181 Loc42_YAngle2 65535 "SNA" ;
VAL_ 1181 Loc42_YAngle1 65535 "SNA" ;
VAL_ 1181 Loc42_YAngle0 65535 "SNA" ;
VAL_ 1182 Loc42_Power4 255 "SNA" ;
VAL_ 1182 Loc42_Power3 255 "SNA" ;
VAL_ 1182 Loc42_Power2 255 "SNA" ;
VAL_ 1182 Loc42_Power1 255 "SNA" ;
VAL_ 1182 Loc42_Power0 255 "SNA" ;
VAL_ 1182 Loc42_YAngle4 65535 "SNA" ;
VAL_ 1184 Loc43_YSigmaAngle4 1023 "SNA" ;
VAL_ 1184 Loc43_YSigmaAngle3 1023 "SNA" ;
VAL_ 1184 Loc43_YSigmaAngle2 1023 "SNA" ;
VAL_ 1184 Loc43_YSigmaAngle1 1023 "SNA" ;
VAL_ 1184 Loc43_YSigmaAngle0 1023 "SNA" ;
VAL_ 1185 Loc43_YAngle3 65535 "SNA" ;
VAL_ 1185 Loc43_YAngle2 65535 "SNA" ;
VAL_ 1185 Loc43_YAngle1 65535 "SNA" ;
VAL_ 1185 Loc43_YAngle0 65535 "SNA" ;
VAL_ 1186 Loc43_Power4 255 "SNA" ;
VAL_ 1186 Loc43_Power3 255 "SNA" ;
VAL_ 1186 Loc43_Power2 255 "SNA" ;
VAL_ 1186 Loc43_Power1 255 "SNA" ;
VAL_ 1186 Loc43_Power0 255 "SNA" ;
VAL_ 1186 Loc43_YAngle4 65535 "SNA" ;
VAL_ 1188 Loc44_YSigmaAngle4 1023 "SNA" ;
VAL_ 1188 Loc44_YSigmaAngle3 1023 "SNA" ;
VAL_ 1188 Loc44_YSigmaAngle2 1023 "SNA" ;
VAL_ 1188 Loc44_YSigmaAngle1 1023 "SNA" ;
VAL_ 1188 Loc44_YSigmaAngle0 1023 "SNA" ;
VAL_ 1189 Loc44_YAngle3 65535 "SNA" ;
VAL_ 1189 Loc44_YAngle2 65535 "SNA" ;
VAL_ 1189 Loc44_YAngle1 65535 "SNA" ;
VAL_ 1189 Loc44_YAngle0 65535 "SNA" ;
VAL_ 1190 Loc44_Power4 255 "SNA" ;
VAL_ 1190 Loc44_Power3 255 "SNA" ;
VAL_ 1190 Loc44_Power2 255 "SNA" ;
VAL_ 1190 Loc44_Power1 255 "SNA" ;
VAL_ 1190 Loc44_Power0 255 "SNA" ;
VAL_ 1190 Loc44_YAngle4 65535 "SNA" ;
VAL_ 1192 Loc45_YSigmaAngle4 1023 "SNA" ;
VAL_ 1192 Loc45_YSigmaAngle3 1023 "SNA" ;
VAL_ 1192 Loc45_YSigmaAngle2 1023 "SNA" ;
VAL_ 1192 Loc45_YSigmaAngle1 1023 "SNA" ;
VAL_ 1192 Loc45_YSigmaAngle0 1023 "SNA" ;
VAL_ 1193 Loc45_YAngle3 65535 "SNA" ;
VAL_ 1193 Loc45_YAngle2 65535 "SNA" ;
VAL_ 1193 Loc45_YAngle1 65535 "SNA" ;
VAL_ 1193 Loc45_YAngle0 65535 "SNA" ;
VAL_ 1194 Loc45_Power4 255 "SNA" ;
VAL_ 1194 Loc45_Power3 255 "SNA" ;
VAL_ 1194 Loc45_Power2 255 "SNA" ;
VAL_ 1194 Loc45_Power1 255 "SNA" ;
VAL_ 1194 Loc45_Power0 255 "SNA" ;
VAL_ 1194 Loc45_YAngle4 65535 "SNA" ;
VAL_ 1196 Loc46_YSigmaAngle4 1023 "SNA" ;
VAL_ 1196 Loc46_YSigmaAngle3 1023 "SNA" ;
VAL_ 1196 Loc46_YSigmaAngle2 1023 "SNA" ;
VAL_ 1196 Loc46_YSigmaAngle1 1023 "SNA" ;
VAL_ 1196 Loc46_YSigmaAngle0 1023 "SNA" ;
VAL_ 1197 Loc46_YAngle3 65535 "SNA" ;
VAL_ 1197 Loc46_YAngle2 65535 "SNA" ;
VAL_ 1197 Loc46_YAngle1 65535 "SNA" ;
VAL_ 1197 Loc46_YAngle0 65535 "SNA" ;
VAL_ 1198 Loc46_Power4 255 "SNA" ;
VAL_ 1198 Loc46_Power3 255 "SNA" ;
VAL_ 1198 Loc46_Power2 255 "SNA" ;
VAL_ 1198 Loc46_Power1 255 "SNA" ;
VAL_ 1198 Loc46_Power0 255 "SNA" ;
VAL_ 1198 Loc46_YAngle4 65535 "SNA" ;
VAL_ 1200 Loc47_YSigmaAngle4 1023 "SNA" ;
VAL_ 1200 Loc47_YSigmaAngle3 1023 "SNA" ;
VAL_ 1200 Loc47_YSigmaAngle2 1023 "SNA" ;
VAL_ 1200 Loc47_YSigmaAngle1 1023 "SNA" ;
VAL_ 1200 Loc47_YSigmaAngle0 1023 "SNA" ;
VAL_ 1201 Loc47_YAngle3 65535 "SNA" ;
VAL_ 1201 Loc47_YAngle2 65535 "SNA" ;
VAL_ 1201 Loc47_YAngle1 65535 "SNA" ;
VAL_ 1201 Loc47_YAngle0 65535 "SNA" ;
VAL_ 1202 Loc47_Power4 255 "SNA" ;
VAL_ 1202 Loc47_Power3 255 "SNA" ;
VAL_ 1202 Loc47_Power2 255 "SNA" ;
VAL_ 1202 Loc47_Power1 255 "SNA" ;
VAL_ 1202 Loc47_Power0 255 "SNA" ;
VAL_ 1202 Loc47_YAngle4 65535 "SNA" ;
VAL_ 1285 Radar1_Obj00_flagValid 1 "Radar1_object_valid" 0 "Radar1_object_invalid" ;
VAL_ 1285 Radar1_Obj00_flagHist 1 "Radar1_object_prev_present" 0 "Radar1_new_object" ;
VAL_ 1285 Radar1_Obj00_flagMeas 1 "Radar1_object_measured" 0 "Radar1_object_not_measured" ;
VAL_ 1286 Radar1_Obj00_class 4 "constElem" 3 "movingPedestrian" 2 "movingTwoWheelVeh" 1 "movingFourWheelVeh" 0 "unknown" ;
VAL_ 1286 Radar1_Obj00_movingState 3 "standing" 2 "stopped" 1 "moving" 0 "Unknown/Unclassified" ;
